VERSION "hnnbnnnynnnnnnnnnnnnnnnnnnnnnnnnnnnnnnnnnn/4/%%%/4/'%**4nnn///"

NS_ :

BS_:

BU_: BAP_Tester Fahrerdisplay_Kombi HUD ICAS1_X_Gateway ICAS3_Gateway ICC_IO_Node Kombi SmartLight_01 ZR_MIB_TOP_ab_Gen3

BO_ 2536721664 BAP_FAS_Profiles_ASG_01: 8 ICAS3_Gateway
	SG_ BAP_FAS_Profiles_ASG_01_Header : 0|8@1+ (1,0) [0|255] "None"  ICAS1_X_Gateway

BO_ 2536721680 BAP_FAS_Profiles_FSG_01: 8 ICAS1_X_Gateway
	SG_ BAP_FAS_Profiles_FSG_01_Header : 0|8@1+ (1,0) [0|255] "None"  ICAS3_Gateway

BO_ 2536707072 BAP_Homelink_ASG_01: 8 ZR_MIB_TOP_ab_Gen3
	SG_ BAP_Homelink_ASG_01_Header : 0|64@1+ (1,0) [0|18446744073709551616] ""  ICAS1_X_Gateway

BO_ 2536707088 BAP_Homelink_FSG_01: 8 ICAS1_X_Gateway
	SG_ BAP_Homelink_FSG_01_Header : 0|64@1+ (1,0) [0|18446744073709551616] ""  ZR_MIB_TOP_ab_Gen3

BO_ 2536722944 BAP_IAA_PSO_ASG_01: 8 ICAS3_Gateway
	SG_ BAP_IAA_PSO_ASG_01_Header : 0|8@1+ (1,0) [0|255] "None"  ICAS1_X_Gateway

BO_ 2536722960 BAP_IAA_PSO_FSG_01: 8 ICAS1_X_Gateway
	SG_ BAP_IAA_PSO_FSG_01_Header : 0|8@1+ (1,0) [0|255] "None"  ICAS3_Gateway,ZR_MIB_TOP_ab_Gen3

BO_ 2536722434 BAP_InfoSettings_ASG_03: 8 ICAS1_X_Gateway
	SG_ BAP_InfoSettings_ASG_03_Header : 0|64@1+ (1,0) [0|18446744073709551616] ""  ICAS3_Gateway,ZR_MIB_TOP_ab_Gen3

BO_ 2536722448 BAP_InfoSettings_FSG_01: 8 ICAS3_Gateway
	SG_ BAP_InfoSettings_FSG_01_Header : 0|8@1+ (1,0) [0|255] "None"  ICAS1_X_Gateway

BO_ 2536729088 BAP_Innenlicht2_ASG_01: 8 ICAS3_Gateway
	SG_ BAP_Innenlicht2_ASG_01_Header : 0|64@1+ (1,0) [0|18446744073709551616] ""  ICAS1_X_Gateway

BO_ 2536729104 BAP_Innenlicht2_FSG_01: 8 ICAS1_X_Gateway
	SG_ BAP_Innenlicht2_FSG_01_Header : 0|64@1+ (1,0) [0|18446744073709551616] ""  ICAS3_Gateway,ZR_MIB_TOP_ab_Gen3

BO_ 2536704000 BAP_Innenlicht_ASG_01: 8 ICAS3_Gateway
	SG_ BAP_Innenlicht_ASG_01_Header : 0|8@1+ (1,0) [0|255] ""  ICAS1_X_Gateway

BO_ 2536704016 BAP_Innenlicht_FSG_01: 8 ICAS1_X_Gateway
	SG_ BAP_Innenlicht_FSG_01_Header : 0|8@1+ (1,0) [0|255] ""  ICAS3_Gateway,ZR_MIB_TOP_ab_Gen3

BO_ 2536702208 BAP_Klima1_ASG_01: 8 ICAS3_Gateway
	SG_ BAP_Klima1_ASG_01_Header : 0|64@1+ (1,0) [0|18446744073709551616] ""  ICAS1_X_Gateway

BO_ 2536702224 BAP_Klima1_FSG_01: 8 ICAS1_X_Gateway
	SG_ BAP_Klima1_FSG_01_Header : 0|64@1+ (1,0) [0|18446744073709551616] ""  ICAS3_Gateway,ZR_MIB_TOP_ab_Gen3

BO_ 2536702464 BAP_Klima2_ASG_01: 8 ICAS3_Gateway
	SG_ BAP_Klima2_ASG_01_Header : 0|64@1+ (1,0) [0|18446744073709551616] ""  ICAS1_X_Gateway

BO_ 2536702480 BAP_Klima2_FSG_01: 8 ICAS1_X_Gateway
	SG_ BAP_Klima2_FSG_01_Header : 0|8@1+ (1,0) [0|255] ""  ICAS3_Gateway,ZR_MIB_TOP_ab_Gen3

BO_ 2536718848 BAP_KlimaMaster_ASG_01: 8 ICAS3_Gateway
	SG_ BAP_KlimaMaster_ASG_01_Header : 0|8@1+ (1,0) [0|255] "None"  ICAS1_X_Gateway

BO_ 2536718864 BAP_KlimaMaster_FSG_01: 8 ICAS1_X_Gateway
	SG_ BAP_KlimaMaster_FSG_01_Header : 0|8@1+ (1,0) [0|255] "None"  ICAS3_Gateway,ZR_MIB_TOP_ab_Gen3

BO_ 2536708352 BAP_LDW_ASG_01: 8 ICAS3_Gateway
	SG_ BAP_LDW_ASG_01_Header : 0|8@1+ (1,0) [0|255] ""  ICAS1_X_Gateway

BO_ 2536708353 BAP_LDW_ASG_02: 8 ICAS3_Gateway
	SG_ BAP_LDW_ASG_02_Header : 0|8@1+ (1,0) [0|255] ""  ICAS1_X_Gateway

BO_ 2536708368 BAP_LDW_FSG_01: 8 ICAS1_X_Gateway
	SG_ BAP_LDW_FSG_01_Header : 0|8@1+ (1,0) [0|255] ""  ICAS3_Gateway,ZR_MIB_TOP_ab_Gen3

BO_ 2536715264 BAP_MFL_ASG_01: 8 Kombi
	SG_ BAP_MFL_ASG_01_Header : 0|8@1+ (1,0) [0|255] ""  ZR_MIB_TOP_ab_Gen3

BO_ 2536715280 BAP_MFL_FSG_01: 8 ZR_MIB_TOP_ab_Gen3
	SG_ BAP_MFL_FSG_01_Header : 0|8@1+ (1,0) [0|255] ""  Kombi

BO_ 2536705536 BAP_Mirror_ASG_01: 8 ICAS3_Gateway
	SG_ BAP_Mirror_ASG_01_Header : 0|8@1+ (1,0) [0|255] ""  ICAS1_X_Gateway

BO_ 2536705552 BAP_Mirror_FSG_01: 8 ICAS1_X_Gateway
	SG_ BAP_Mirror_FSG_01_Header : 0|8@1+ (1,0) [0|255] ""  ICAS3_Gateway,ZR_MIB_TOP_ab_Gen3

BO_ 2536710656 BAP_MKE_ASG_01: 8 ICAS3_Gateway
	SG_ BAP_MKE_ASG_01_Header : 0|8@1+ (1,0) [0|255] ""  ICAS1_X_Gateway

BO_ 2536710672 BAP_MKE_FSG_01: 8 ICAS1_X_Gateway
	SG_ BAP_MKE_FSG_01_Header : 0|8@1+ (1,0) [0|255] ""  ICAS3_Gateway,ZR_MIB_TOP_ab_Gen3

BO_ 2536732416 BAP_MobDevKey_ASG_01: 8 ICAS3_Gateway
	SG_ BAP_MobDevKey_ASG_01_Header : 0|64@1+ (1,0) [0|18446744073709551616] ""  ICAS1_X_Gateway

BO_ 2536732432 BAP_MobDevKey_FSG_01: 8 ICAS1_X_Gateway
	SG_ BAP_MobDevKey_FSG_01_Header : 0|64@1+ (1,0) [0|18446744073709551616] ""  ICAS3_Gateway

BO_ 2536714752 BAP_Navigation_ASG_01: 8 Kombi
	SG_ BAP_Navigation_ASG_01_Header : 0|8@1+ (1,0) [0|255] ""  ZR_MIB_TOP_ab_Gen3

BO_ 2536714753 BAP_Navigation_ASG_02: 8 Kombi
	SG_ BAP_Navigation_ASG_02_Header : 0|8@1+ (1,0) [0|255] ""  ZR_MIB_TOP_ab_Gen3

BO_ 2536714768 BAP_Navigation_FSG_01: 8 ZR_MIB_TOP_ab_Gen3
	SG_ BAP_Navigation_FSG_01_Header : 0|8@1+ (1,0) [0|255] ""  Kombi

BO_ 2536714769 BAP_Navigation_FSG_02: 8 ZR_MIB_TOP_ab_Gen3
	SG_ BAP_Navigation_FSG_02_Header : 0|8@1+ (1,0) [0|255] ""  Kombi

BO_ 2536712704 BAP_OnlineFunctions_ASG_01: 8 Kombi
	SG_ BAP_OnlineFunction_ASG_01_Header : 0|8@1+ (1,0) [0|255] "None"  ZR_MIB_TOP_ab_Gen3

BO_ 2536712720 BAP_OnlineFunctions_FSG_01: 8 ZR_MIB_TOP_ab_Gen3
	SG_ BAP_OnlineFunction_FSG_01_Header : 0|8@1+ (1,0) [0|255] "None"  Kombi

BO_ 2536704512 BAP_OPS_ASG_01: 8 ICAS3_Gateway
	SG_ BAP_OPS_ASG_01_Header : 0|8@1+ (1,0) [0|255] ""  ICAS1_X_Gateway

BO_ 2536704528 BAP_OPS_FSG_01: 8 ICAS1_X_Gateway
	SG_ BAP_OPS_FSG_01_Header : 0|8@1+ (1,0) [0|255] ""  ICAS3_Gateway,ZR_MIB_TOP_ab_Gen3

BO_ 2536704529 BAP_OPS_FSG_02: 8 ICAS1_X_Gateway
	SG_ BAP_OPS_FSG_02_Header : 0|8@1+ (1,0) [0|255] ""  ICAS3_Gateway,ZR_MIB_TOP_ab_Gen3

BO_ 2536723712 BAP_PaCo_ASG_01: 8 ICAS3_Gateway
	SG_ BAP_PaCo_ASG_01_Header : 0|8@1+ (1,0) [0|255] "None"  ICAS1_X_Gateway

BO_ 2536723713 BAP_PaCo_ASG_02: 8 ICAS3_Gateway
	SG_ BAP_PaCo_ASG_02_Header : 0|8@1+ (1,0) [0|255] "None"  ICAS1_X_Gateway

BO_ 2536723728 BAP_PaCo_FSG_01: 8 ICAS1_X_Gateway
	SG_ BAP_PaCo_FSG_01_Header : 0|8@1+ (1,0) [0|255] "None"  ICAS3_Gateway,Kombi,ZR_MIB_TOP_ab_Gen3

BO_ 2536702720 BAP_ParkHeater_ASG_01: 8 ICAS3_Gateway
	SG_ BAP_ParkHeater_ASG_01_Header : 0|8@1+ (1,0) [0|255] ""  ICAS1_X_Gateway

BO_ 2536702736 BAP_ParkHeater_FSG_01: 8 ICAS1_X_Gateway
	SG_ BAP_ParkHeater_FSG_01_Header : 0|8@1+ (1,0) [0|255] ""  ICAS3_Gateway,ZR_MIB_TOP_ab_Gen3

BO_ 2536703744 BAP_RDK_ASG_01: 8 ICAS3_Gateway
	SG_ BAP_RDK_ASG_01_Header : 0|8@1+ (1,0) [0|255] ""  ICAS1_X_Gateway

BO_ 2536703745 BAP_RDK_ASG_02: 8 ICAS3_Gateway
	SG_ BAP_RDK_ASG_02_Header : 0|8@1+ (1,0) [0|255] ""  ICAS1_X_Gateway

BO_ 2536703747 BAP_RDK_ASG_04: 8 ICAS3_Gateway
	SG_ BAP_RDK_ASG_04_Header : 0|64@1+ (1,0) [0|18446744073709551616] ""  ICAS1_X_Gateway

BO_ 2536703760 BAP_RDK_FSG_01: 8 ICAS1_X_Gateway
	SG_ BAP_RDK_FSG_01_Header : 0|8@1+ (1,0) [0|255] ""  ICAS3_Gateway,ZR_MIB_TOP_ab_Gen3

BO_ 2536721921 BAP_RemoteServices_ASG_02: 8 ICAS3_Gateway
	SG_ BAP_RemoteServices_ASG_02_Header : 0|8@1+ (1,0) [0|255] "None"  ICAS1_X_Gateway

BO_ 2536721936 BAP_RemoteServices_FSG_01: 8 ICAS1_X_Gateway
	SG_ BAP_RemoteServices_FSG_01_Header : 0|8@1+ (1,0) [0|255] "None"  ICAS3_Gateway,ZR_MIB_TOP_ab_Gen3

BO_ 2536704768 BAP_RVC_ASG_01: 8 ICAS3_Gateway
	SG_ BAP_RVC_ASG_01_Header : 0|64@1+ (1,0) [0|18446744073709551616] ""  ICAS1_X_Gateway

BO_ 2536704784 BAP_RVC_FSG_01: 8 ICAS1_X_Gateway
	SG_ BAP_RVC_FSG_01_Header : 0|8@1+ (1,0) [0|255] ""  ICAS3_Gateway,ZR_MIB_TOP_ab_Gen3

BO_ 2536717056 BAP_SeatPneumatic_ASG_01: 8 ICAS3_Gateway
	SG_ BAP_SeatPneumatic_ASG_01_Header : 0|8@1+ (1,0) [0|255] ""  ICAS1_X_Gateway

BO_ 2536717072 BAP_SeatPneumatic_FSG_01: 8 ICAS1_X_Gateway
	SG_ BAP_SeatPneumatic_FSG_01_Header : 0|8@1+ (1,0) [0|255] ""  ICAS3_Gateway,ZR_MIB_TOP_ab_Gen3

BO_ 2536706560 BAP_SIA_ASG_01: 8 ZR_MIB_TOP_ab_Gen3
	SG_ BAP_SIA_ASG_01_Header : 0|8@1+ (1,0) [0|255] ""  Kombi

BO_ 2536706576 BAP_SIA_FSG_01: 8 Kombi
	SG_ BAP_SIA_FSG_01_Header : 0|8@1+ (1,0) [0|255] ""  ZR_MIB_TOP_ab_Gen3

BO_ 2536706048 BAP_Sitz1_ASG_01: 8 ICAS3_Gateway
	SG_ BAP_Sitz1_ASG_01_Header : 0|64@1+ (1,0) [0|18446744073709551616] ""  ICAS1_X_Gateway

BO_ 2536706064 BAP_Sitz1_FSG_01: 8 ICAS1_X_Gateway
	SG_ BAP_Sitz1_FSG_01_Header : 0|8@1+ (1,0) [0|255] ""  ICAS3_Gateway,ZR_MIB_TOP_ab_Gen3

BO_ 2536710144 BAP_Sitz2_ASG_01: 8 ZR_MIB_TOP_ab_Gen3
	SG_ BAP_Sitz2_ASG_01_Header : 0|8@1+ (1,0) [0|255] ""  ICAS1_X_Gateway

BO_ 2536710160 BAP_Sitz2_FSG_01: 8 ICAS1_X_Gateway
	SG_ BAP_Sitz2_FSG_01_Header : 0|8@1+ (1,0) [0|255] ""  ZR_MIB_TOP_ab_Gen3

BO_ 2536721152 BAP_Sunroof_ASG_01: 8 ICAS3_Gateway
	SG_ BAP_Sunroof_ASG_01_Header : 0|8@1+ (1,0) [0|255] "None"  ICAS1_X_Gateway

BO_ 2536721168 BAP_Sunroof_FSG_01: 8 ICAS1_X_Gateway
	SG_ BAP_Sunroof_FSG_01_Header : 0|8@1+ (1,0) [0|255] "None"  ICAS3_Gateway

BO_ 2536708608 BAP_SWA_ASG_01: 8 ICAS3_Gateway
	SG_ BAP_SWA_ASG_01_Header : 0|8@1+ (1,0) [0|255] ""  ICAS1_X_Gateway

BO_ 2536708624 BAP_SWA_FSG_01: 8 ICAS1_X_Gateway
	SG_ BAP_SWA_FSG_01_Header : 0|8@1+ (1,0) [0|255] ""  ICAS3_Gateway,ZR_MIB_TOP_ab_Gen3

BO_ 2536712448 BAP_Telefon2_ASG_01: 8 Kombi
	SG_ BAP_Telefon2_ASG_01_Header : 0|8@1+ (1,0) [0|255] ""  ZR_MIB_TOP_ab_Gen3

BO_ 2536712464 BAP_Telefon2_FSG_01: 8 ZR_MIB_TOP_ab_Gen3
	SG_ BAP_Telefon2_FSG_01_Header : 0|8@1+ (1,0) [0|255] ""  Kombi

BO_ 2536712465 BAP_Telefon2_FSG_02: 8 ZR_MIB_TOP_ab_Gen3
	SG_ BAP_Telefon2_FSG_02_Header : 0|8@1+ (1,0) [0|255] "None"  Kombi

BO_ 2536712192 BAP_Telefon_ASG_01: 8 Kombi
	SG_ BAP_Telefon_ASG_01_Header : 0|8@1+ (1,0) [0|255] ""  ZR_MIB_TOP_ab_Gen3

BO_ 2536712193 BAP_Telefon_ASG_02: 8 Kombi
	SG_ BAP_Telefon_ASG_02_Header : 0|8@1+ (1,0) [0|255] ""  ZR_MIB_TOP_ab_Gen3

BO_ 2536712208 BAP_Telefon_FSG_01: 8 ZR_MIB_TOP_ab_Gen3
	SG_ BAP_Telefon_FSG_01_Header : 0|8@1+ (1,0) [0|255] ""  Kombi

BO_ 2536712209 BAP_Telefon_FSG_02: 8 ZR_MIB_TOP_ab_Gen3
	SG_ BAP_Telefon_FSG_02_Header : 0|8@1+ (1,0) [0|255] ""  Kombi

BO_ 2536728576 BAP_THA_ASG_01: 8 ICAS3_Gateway
	SG_ BAP_THA_ASG_01_Header : 0|64@1+ (1,0) [0|18446744073709551616] ""  ICAS1_X_Gateway

BO_ 2536728592 BAP_THA_FSG_01: 8 ICAS1_X_Gateway
	SG_ BAP_THA_FSG_01_Header : 0|64@1+ (1,0) [0|18446744073709551616] ""  ICAS3_Gateway

BO_ 2536726273 BAP_TPA_ASG_02: 8 ICAS3_Gateway
	SG_ BAP_TPA_ASG_02_Header : 0|64@1+ (1,0) [0|18446744073709551616] ""  ICAS1_X_Gateway

BO_ 2536726288 BAP_TPA_FSG_01: 8 ICAS1_X_Gateway
	SG_ BAP_TPA_FSG_01_Header : 0|64@1+ (1,0) [0|18446744073709551616] ""  ICAS3_Gateway

BO_ 2536715776 BAP_TrailerAssist_ASG_01: 8 ICAS3_Gateway
	SG_ BAP_TrailerAssist_ASG_01_Header : 0|8@1+ (1,0) [0|255] ""  ICAS1_X_Gateway

BO_ 2536715792 BAP_TrailerAssist_FSG_01: 8 ICAS1_X_Gateway
	SG_ BAP_TrailerAssist_FSG_01_Header : 0|8@1+ (1,0) [0|255] ""  ICAS3_Gateway,ZR_MIB_TOP_ab_Gen3

BO_ 2536710400 BAP_VZA_ASG_01: 8 ICAS3_Gateway
	SG_ BAP_VZA_ASG_01_Header : 0|8@1+ (1,0) [0|255] ""  ICAS1_X_Gateway

BO_ 2536710401 BAP_VZA_ASG_02: 8 ICAS3_Gateway
	SG_ BAP_VZA_ASG_02_Header : 0|8@1+ (1,0) [0|255] ""  ICAS1_X_Gateway

BO_ 2536710402 BAP_VZA_ASG_03: 8 ICAS3_Gateway
	SG_ BAP_VZA_ASG_03_Header : 0|8@1+ (1,0) [0|255] "None"  ICAS1_X_Gateway

BO_ 2536710416 BAP_VZA_FSG_01: 8 ICAS1_X_Gateway
	SG_ BAP_VZA_FSG_01_Header : 0|8@1+ (1,0) [0|255] ""  ICAS3_Gateway,Kombi,ZR_MIB_TOP_ab_Gen3

BO_ 2536705024 BAP_Wiper_ASG_01: 8 ICAS3_Gateway
	SG_ BAP_Wiper_ASG_01_Header : 0|8@1+ (1,0) [0|255] ""  ICAS1_X_Gateway

BO_ 2536705040 BAP_Wiper_FSG_01: 8 ICAS1_X_Gateway
	SG_ BAP_Wiper_FSG_01_Header : 0|8@1+ (1,0) [0|255] ""  ICAS3_Gateway,ZR_MIB_TOP_ab_Gen3

BO_ 1626 BCM_01: 8 ICAS1_X_Gateway
	SG_ APS_Tongeber_defekt : 44|1@1+ (1,0) [0|1] ""  Vector__XXX
	SG_ BCM1_AFS_Lampe : 35|1@1+ (1,0) [0|1] ""  Vector__XXX
	SG_ BCM1_EasyEntry_Status : 45|1@1+ (1,0) [0|1] ""  Vector__XXX
	SG_ BCM1_Kl_15_HW_erkannt : 17|1@1+ (1,0) [0|1] ""  Vector__XXX
	SG_ BCM1_Kl_15_Sig_HW_erkannt : 18|1@1+ (1,0) [0|1] ""  Vector__XXX
	SG_ BCM1_Lenksaeule_aktiv : 46|1@1+ (1,0) [0|1] ""  Vector__XXX
	SG_ BCM1_MH_Schalter : 31|1@1+ (1,0) [0|1] ""  ICAS3_Gateway,Kombi,ZR_MIB_TOP_ab_Gen3
	SG_ BCM1_MH_WIV_Schalter : 32|1@1+ (1,0) [0|1] ""  Vector__XXX
	SG_ BCM1_NV_Taster : 34|1@1+ (1,0) [0|1] ""  Vector__XXX
	SG_ BCM1_Reisemodus_Texte : 36|2@1+ (1,0) [0|3] ""  Vector__XXX
	SG_ BCM1_Rueckfahrlicht_Schalter : 30|1@1+ (1,0) [0|1] ""  Vector__XXX
	SG_ BCM1_Spannungs_Anf : 47|2@1+ (1,0) [0|3] ""  Vector__XXX
	SG_ BCM1_Valet_Parking_Taster : 26|1@1+ (1,0) [0|1] ""  Vector__XXX
	SG_ BCM1_Warnblink_Taster : 25|1@1+ (1,0) [0|1] ""  Vector__XXX
	SG_ BCM_Anf_AAW_MoLaWa : 58|2@1+ (1,0) [0|3] ""  Vector__XXX
	SG_ BCM_Bremsbelag_Sensor : 12|1@1+ (1,0) [0|1] ""  Kombi
	SG_ BCM_Bremsfluessigkeit_Sensor : 13|1@1+ (1,0) [0|1] ""  Fahrerdisplay_Kombi,Kombi
	SG_ BCM_Charisma_Taste2 : 22|1@1+ (1,0) [0|1] ""  Vector__XXX
	SG_ BCM_Eco_Charisma_Taste : 33|1@1+ (1,0) [0|1] ""  Vector__XXX
	SG_ BCM_Handbremse_Hinweis : 60|1@1+ (1,0) [0|1] ""  Vector__XXX
	SG_ BCM_HDF_betaetigt : 63|1@1+ (1,0) [0|1] ""  Vector__XXX
	SG_ BCM_Hybrid_StartStopp_Taste : 24|1@1+ (1,0) [0|1] ""  Vector__XXX
	SG_ BCM_Hybrid_StSt_Taste_Fehler : 23|1@1+ (1,0) [0|1] ""  Vector__XXX
	SG_ BCM_Kuehlmittel_Sensor : 16|1@1+ (1,0) [0|1] ""  Kombi
	SG_ BCM_Kuehlmittel_Sensor_02 : 19|1@1+ (1,0) [0|1] ""  Vector__XXX
	SG_ BCM_Offroad_Taste : 21|1@1+ (1,0) [0|1] ""  Vector__XXX
	SG_ BCM_ValetTaster_Fkts_LED : 42|1@1+ (1,0) [0|1] ""  Vector__XXX
	SG_ BCM_Waschwasser_Sensor : 15|1@1+ (1,0) [0|1] ""  Kombi
	SG_ Gong_TFL_Umschaltung : 40|1@1+ (1,0) [0|1] ""  Vector__XXX
	SG_ LRH_Taster : 43|1@1+ (1,0) [0|1] ""  Vector__XXX

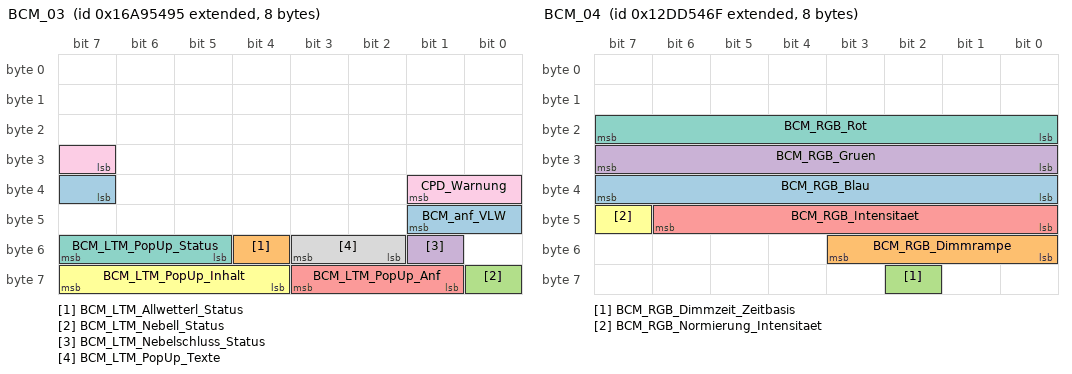
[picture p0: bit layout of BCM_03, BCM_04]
BO_ 2527679637 BCM_03: 8 ICAS1_X_Gateway
	SG_ BCM_anf_VLW : 39|3@1+ (1,0) [0|7] ""  Vector__XXX
	SG_ BCM_LTM_Allwetterl_Status : 52|1@1+ (1,0) [0|1] ""  ICAS3_Gateway,Kombi
	SG_ BCM_LTM_Nebell_Status : 56|1@1+ (1,0) [0|1] ""  Kombi
	SG_ BCM_LTM_Nebelschluss_Status : 49|1@1+ (1,0) [0|1] ""  Kombi
	SG_ BCM_LTM_PopUp_Anf : 57|3@1+ (1,0) [0|7] ""  Kombi
	SG_ BCM_LTM_PopUp_Inhalt : 60|4@1+ (1,0) [0|15] ""  Kombi
	SG_ BCM_LTM_PopUp_Status : 53|3@1+ (1,0) [0|7] ""  Kombi
	SG_ BCM_LTM_PopUp_Texte : 50|2@1+ (1,0) [0|3] ""  Vector__XXX
	SG_ CPD_Warnung : 31|3@1+ (1,0) [0|7] ""  Kombi

BO_ 2463978607 BCM_04: 8 ICAS1_X_Gateway
	SG_ BCM_RGB_Blau : 32|8@1+ (1,0) [0|255] ""  ICAS3_Gateway,ZR_MIB_TOP_ab_Gen3
	SG_ BCM_RGB_Dimmrampe : 48|4@1+ (0.25,0) [0|3.75] "Secon"  Vector__XXX
	SG_ BCM_RGB_Dimmzeit_Zeitbasis : 58|1@1+ (1,0) [0|1] ""  Vector__XXX
	SG_ BCM_RGB_Gruen : 24|8@1+ (1,0) [0|255] ""  ICAS3_Gateway,ZR_MIB_TOP_ab_Gen3
	SG_ BCM_RGB_Intensitaet : 40|7@1+ (1,0) [0|100] "PerCent"  Vector__XXX
	SG_ BCM_RGB_Normierung_Intensitaet : 47|1@1+ (1,0) [0|1] ""  Vector__XXX
	SG_ BCM_RGB_Rot : 16|8@1+ (1,0) [0|255] ""  ICAS3_Gateway,ZR_MIB_TOP_ab_Gen3

BO_ 1432 BCM_Taster_02: 8 ICAS1_X_Gateway
	SG_ BCM_BFS_Massage_Taster : 42|1@1+ (1,0) [0|1] ""  Vector__XXX
	SG_ BCM_BFS_Multif_Taster : 40|1@1+ (1,0) [0|1] ""  Vector__XXX
	SG_ BCM_BFS_Pneumatik_Verstellung : 44|1@1+ (1,0) [0|1] ""  Vector__XXX
	SG_ BCM_BFS_Programmwippe : 38|1@1+ (1,0) [0|1] ""  Vector__XXX
	SG_ BCM_FS_Massage_Taster : 41|1@1+ (1,0) [0|1] ""  Vector__XXX
	SG_ BCM_FS_Multif_Taster : 39|1@1+ (1,0) [0|1] ""  Vector__XXX
	SG_ BCM_FS_Pneumatik_Verstellung : 43|1@1+ (1,0) [0|1] ""  Vector__XXX
	SG_ BCM_FS_Programmwippe : 37|1@1+ (1,0) [0|1] ""  Vector__XXX
	SG_ FAS_Profile_Taster : 20|2@1+ (1,0) [0|3] ""  ZR_MIB_TOP_ab_Gen3
	SG_ LIM_bCall_Taster : 12|1@1+ (1,0) [0|1] ""  Vector__XXX
	SG_ LIM_iCall_Taster : 13|1@1+ (1,0) [0|1] ""  Vector__XXX
	SG_ LIM_S_Rollo_hi : 53|3@1+ (1,0) [0|7] ""  Vector__XXX
	SG_ LIM_S_Rollo_vo : 50|3@1+ (1,0) [0|7] ""  Vector__XXX
	SG_ LIM_S_SAD_hi : 60|4@1+ (1,0) [0|15] ""  Vector__XXX
	SG_ LIM_S_SAD_Vo : 56|4@1+ (1,0) [0|15] ""  Vector__XXX
	SG_ LINDa_Touch_Event : 16|4@1+ (1,0) [0|15] ""  ICAS3_Gateway,ICC_IO_Node,ZR_MIB_TOP_ab_Gen3
	SG_ Tuerkontakt_Innenlicht_Taste : 14|1@1+ (1,0) [0|1] ""  Vector__XXX

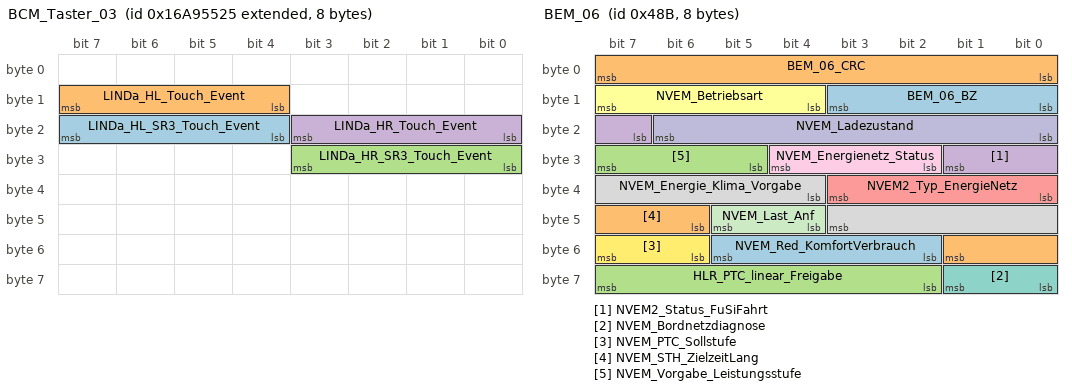
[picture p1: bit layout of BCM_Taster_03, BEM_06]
BO_ 2527679781 BCM_Taster_03: 8 ICAS1_X_Gateway
	SG_ LINDa_HL_SR3_Touch_Event : 20|4@1+ (1,0) [0|15] ""  ICAS3_Gateway,ICC_IO_Node,ZR_MIB_TOP_ab_Gen3
	SG_ LINDa_HL_Touch_Event : 12|4@1+ (1,0) [0|15] ""  ICAS3_Gateway,ICC_IO_Node,ZR_MIB_TOP_ab_Gen3
	SG_ LINDa_HR_SR3_Touch_Event : 24|4@1+ (1,0) [0|15] ""  ICAS3_Gateway,ICC_IO_Node,ZR_MIB_TOP_ab_Gen3
	SG_ LINDa_HR_Touch_Event : 16|4@1+ (1,0) [0|15] ""  ICAS3_Gateway,ICC_IO_Node,ZR_MIB_TOP_ab_Gen3

BO_ 1635 BEM_02: 8 ICAS1_X_Gateway
	SG_ BEM_Anf_KL15_schalten : 54|2@1+ (1,0) [0|3] ""  ICAS3_Gateway,ICC_IO_Node,ZR_MIB_TOP_ab_Gen3
	SG_ BEM_Batt_Ab : 39|1@1+ (1,0) [0|1] ""  ICAS3_Gateway,ICC_IO_Node,ZR_MIB_TOP_ab_Gen3
	SG_ BEM_Batteriediagnose : 28|3@1+ (1,0) [0|7] ""  ICAS3_Gateway,ICC_IO_Node,Kombi,ZR_MIB_TOP_ab_Gen3
	SG_ BEM_DFM : 32|5@1+ (3.225,0.025) [0.025|100] ""  ICAS3_Gateway,ICC_IO_Node,ZR_MIB_TOP_ab_Gen3
	SG_ BEM_EMLIN_ungueltig : 38|1@1+ (1,0) [0|1] ""  ICAS3_Gateway,ICC_IO_Node,ZR_MIB_TOP_ab_Gen3
	SG_ BEM_Generatordiagnose : 16|2@1+ (1,0) [0|3] ""  ICAS3_Gateway,ICC_IO_Node,Kombi,ZR_MIB_TOP_ab_Gen3
	SG_ BEM_HL_Kontingentierung : 8|6@1+ (50,-1000) [-1000|1000] "Watt"  ICAS3_Gateway,ICC_IO_Node,ZR_MIB_TOP_ab_Gen3
	SG_ BEM_HL_Regelung_Status : 21|3@1+ (1,0) [0|7] ""  ICAS3_Gateway,ICC_IO_Node,ZR_MIB_TOP_ab_Gen3
	SG_ BEM_Ladezustand : 24|4@1+ (10,0) [0|100] "PerCent"  ICAS3_Gateway,ICC_IO_Node,Kombi,ZR_MIB_TOP_ab_Gen3
	SG_ BEM_MMI_Vorwarnung : 7|1@1+ (1,0) [0|1] ""  ICAS3_Gateway,ICC_IO_Node,ZR_MIB_TOP_ab_Gen3
	SG_ BEM_Red_Innengeblaese : 18|2@1+ (1,0) [0|3] ""  ICAS3_Gateway,ICC_IO_Node,ZR_MIB_TOP_ab_Gen3
	SG_ BEM_REK_aktiv : 37|1@1+ (1,0) [0|1] ""  ICAS3_Gateway,ICC_IO_Node,ZR_MIB_TOP_ab_Gen3
	SG_ BEM_STH_Einschaltverbot : 20|1@1+ (1,0) [0|1] ""  ICAS3_Gateway,ICC_IO_Node,ZR_MIB_TOP_ab_Gen3
	SG_ BEM_STH_Zielzeit : 3|4@1+ (5,0) [0|60] "Minut"  ICAS3_Gateway,ICC_IO_Node,ZR_MIB_TOP_ab_Gen3
	SG_ BEM_UBDM : 40|8@1+ (0.05,5) [5.05|17.7] "Volt"  ICAS3_Gateway,ICC_IO_Node,ZR_MIB_TOP_ab_Gen3
	SG_ BEM_UGenSoll : 48|6@1+ (0.1,10.6) [10.6|16] "Volt"  ICAS3_Gateway,ICC_IO_Node,ZR_MIB_TOP_ab_Gen3
	SG_ MIB_Stromsparmodus : 31|1@1+ (1,0) [0|1] ""  ICAS3_Gateway,ICC_IO_Node,ZR_MIB_TOP_ab_Gen3
	SG_ NVEM_Abschaltstufe : 0|2@1+ (1,0) [0|3] ""  HUD,ICAS3_Gateway,ICC_IO_Node,Kombi,SmartLight_01,ZR_MIB_TOP_ab_Gen3
	SG_ NVEM_Anf_SD_schalten : 15|1@1+ (1,0) [0|1] ""  ICAS3_Gateway,ICC_IO_Node,ZR_MIB_TOP_ab_Gen3
	SG_ NVEM_Batterie_Service : 56|2@1+ (1,0) [0|3] ""  ICAS3_Gateway,ICC_IO_Node,Kombi,ZR_MIB_TOP_ab_Gen3
	SG_ NVEM_Freigabe_OnlineUpdate : 58|1@1+ (1,0) [0|1] ""  ICAS3_Gateway,ICC_IO_Node,ZR_MIB_TOP_ab_Gen3
	SG_ NVEM_Freigabe_ORU4 : 59|2@1+ (1,0) [0|3] ""  ICAS3_Gateway,ICC_IO_Node,ZR_MIB_TOP_ab_Gen3
	SG_ NVEM_Freigabe_ZusBatt_Laden : 14|1@1+ (1,0) [0|1] ""  ICAS3_Gateway,ICC_IO_Node,ZR_MIB_TOP_ab_Gen3
	SG_ NVEM_Verbraucherabsch_Anz : 61|1@1+ (1,0) [0|1] ""  ICAS3_Gateway,ICC_IO_Node,Kombi,ZR_MIB_TOP_ab_Gen3

BO_ 1163 BEM_06: 8 ICAS1_X_Gateway
	SG_ BEM_06_BZ : 8|4@1+ (1,0) [0|15] ""  Fahrerdisplay_Kombi,Kombi
	SG_ BEM_06_CRC : 0|8@1+ (1,0) [0|255] ""  Fahrerdisplay_Kombi,Kombi
	SG_ HLR_PTC_linear_Freigabe : 58|6@1+ (50,0) [0|3100] "Watt"  Vector__XXX
	SG_ NVEM2_Status_FuSiFahrt : 23|3@1+ (1,0) [0|7] ""  Vector__XXX
	SG_ NVEM2_Typ_EnergieNetz : 32|4@1+ (1,0) [0|15] ""  Vector__XXX
	SG_ NVEM_Betriebsart : 12|4@1+ (1,0) [0|15] ""  Vector__XXX
	SG_ NVEM_Bordnetzdiagnose : 56|2@1+ (1,0) [0|3] ""  Fahrerdisplay_Kombi,Kombi
	SG_ NVEM_Energie_Klima_Vorgabe : 36|8@1+ (10,0) [0|2530] "WattHour"  Vector__XXX
	SG_ NVEM_Energienetz_Status : 26|3@1+ (1,0) [0|7] ""  Vector__XXX
	SG_ NVEM_Ladezustand : 16|7@1+ (1,0) [0|100] "PerCent"  Vector__XXX
	SG_ NVEM_Last_Anf : 44|2@1+ (1,0) [0|3] ""  Vector__XXX
	SG_ NVEM_PTC_Sollstufe : 54|2@1+ (1,0) [0|3] ""  Vector__XXX
	SG_ NVEM_Red_KomfortVerbrauch : 50|4@1+ (1,0) [0|15] ""  Vector__XXX
	SG_ NVEM_STH_ZielzeitLang : 46|4@1+ (10,0) [0|120] "Minut"  Vector__XXX
	SG_ NVEM_Vorgabe_Leistungsstufe : 29|3@1+ (1,0) [0|7] ""  Vector__XXX

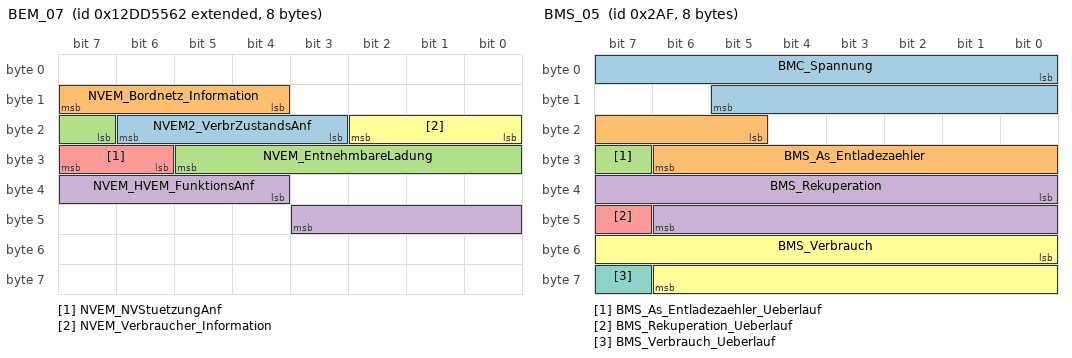
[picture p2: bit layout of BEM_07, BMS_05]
BO_ 2463978850 BEM_07: 8 ICAS1_X_Gateway
	SG_ NVEM2_VerbrZustandsAnf : 19|4@1+ (1,0) [0|15] ""  Vector__XXX
	SG_ NVEM_Bordnetz_Information : 12|4@1+ (1,0) [0|15] ""  Vector__XXX
	SG_ NVEM_EntnehmbareLadung : 23|7@1+ (1,0) [0|127] "AmperHour"  Vector__XXX
	SG_ NVEM_HVEM_FunktionsAnf : 36|8@1+ (1,0) [0|255] ""  ICAS3_Gateway
	SG_ NVEM_NVStuetzungAnf : 30|2@1+ (1,0) [0|3] ""  Vector__XXX
	SG_ NVEM_Verbraucher_Information : 16|3@1+ (1,0) [0|7] ""  Vector__XXX

BO_ 870 Blinkmodi_02: 8 ICAS1_X_Gateway
	SG_ Blinken_li_Fzg_Takt : 25|1@1+ (1,0) [0|1] ""  Vector__XXX
	SG_ Blinken_li_Kombi_Takt : 27|1@1+ (1,0) [0|1] ""  Fahrerdisplay_Kombi,ICAS3_Gateway,Kombi,ZR_MIB_TOP_ab_Gen3
	SG_ Blinken_re_Fzg_Takt : 26|1@1+ (1,0) [0|1] ""  Vector__XXX
	SG_ Blinken_re_Kombi_Takt : 28|1@1+ (1,0) [0|1] ""  Fahrerdisplay_Kombi,ICAS3_Gateway,Kombi,ZR_MIB_TOP_ab_Gen3
	SG_ Blinkmodi_02_BZ : 8|4@1+ (1,0) [0|15] ""  Vector__XXX
	SG_ Blinkmodi_02_CRC : 0|8@1+ (1,0) [0|255] ""  Vector__XXX
	SG_ BM_Autobahn : 34|1@1+ (1,0) [0|1] ""  ZR_MIB_TOP_ab_Gen3
	SG_ BM_Crash : 16|1@1+ (1,0) [0|1] ""  Vector__XXX
	SG_ BM_DWA_Alarm : 15|1@1+ (1,0) [0|1] ""  Vector__XXX
	SG_ BM_DWA_ein : 14|1@1+ (1,0) [0|1] ""  Vector__XXX
	SG_ BM_GDO : 19|1@1+ (1,0) [0|1] ""  Vector__XXX
	SG_ BM_HD_Oeffnung_angelernt : 33|1@1+ (1,0) [0|1] ""  Vector__XXX
	SG_ BM_links : 23|1@1+ (1,0) [0|1] ""  Vector__XXX
	SG_ BM_NBA_n_codiert_n_aktiv : 29|1@1+ (1,0) [0|1] ""  Vector__XXX
	SG_ BM_NBA_Status : 30|2@1+ (1,0) [0|3] ""  Vector__XXX
	SG_ BM_Not_Bremsung : 18|1@1+ (1,0) [0|1] ""  Vector__XXX
	SG_ BM_Panik : 17|1@1+ (1,0) [0|1] ""  Vector__XXX
	SG_ BM_PiloPa : 44|1@1+ (1,0) [0|1] ""  Vector__XXX
	SG_ BM_Recas : 36|1@1+ (1,0) [0|1] ""  Vector__XXX
	SG_ BM_rechts : 24|1@1+ (1,0) [0|1] ""  Vector__XXX
	SG_ BM_Rollenmodus_Blinken : 35|1@1+ (1,0) [0|1] ""  Vector__XXX
	SG_ BM_Taxi_Notalarm : 21|1@1+ (1,0) [0|1] ""  Vector__XXX
	SG_ BM_Telematik : 22|1@1+ (1,0) [0|1] ""  Vector__XXX
	SG_ BM_Telematik_Abbruchgrund : 38|6@1+ (1,0) [0|63] ""  Vector__XXX
	SG_ BM_Warnblinken : 20|1@1+ (1,0) [0|1] ""  Kombi
	SG_ BM_WBT_Beleuchtung : 32|1@1+ (1,0) [0|1] ""  Vector__XXX
	SG_ BM_Wischblinken : 37|1@1+ (1,0) [0|1] ""  Vector__XXX
	SG_ BM_ZV_auf : 12|1@1+ (1,0) [0|1] ""  Vector__XXX
	SG_ BM_ZV_zu : 13|1@1+ (1,0) [0|1] ""  Vector__XXX
	SG_ DWA_Alarmquelle : 59|5@1+ (1,0) [0|31] ""  Vector__XXX
	SG_ SAL_TA_Blinken_Status : 45|3@1+ (1,0) [0|7] ""  Vector__XXX

BO_ 687 BMS_05: 8 ICAS1_X_Gateway
	SG_ BMC_Spannung : 0|14@1+ (0.0625,0) [0|1023.75] "Volt"  Vector__XXX
	SG_ BMS_As_Entladezaehler : 21|10@1+ (1,0) [0|1023] "AmperSecon"  Vector__XXX
	SG_ BMS_As_Entladezaehler_Ueberlauf : 31|1@1+ (1,0) [0|1] ""  Vector__XXX
	SG_ BMS_Rekuperation : 32|15@1+ (10,0) [0|327670] "WattSecond"  Kombi
	SG_ BMS_Rekuperation_Ueberlauf : 47|1@1+ (1,0) [0|1] ""  Kombi
	SG_ BMS_Verbrauch : 48|15@1+ (10,0) [0|327670] "WattSecond"  Kombi
	SG_ BMS_Verbrauch_Ueberlauf : 63|1@1+ (1,0) [0|1] ""  Kombi

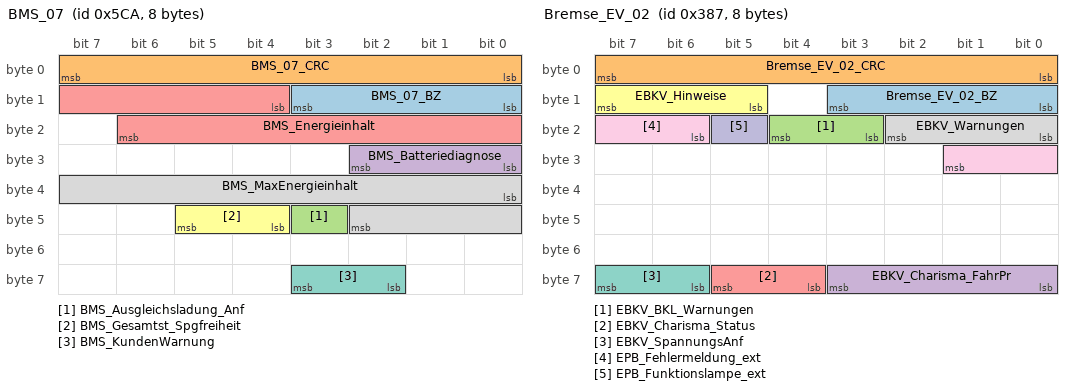
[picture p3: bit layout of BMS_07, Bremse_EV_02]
BO_ 1482 BMS_07: 8 ICAS1_X_Gateway
	SG_ BMS_07_BZ : 8|4@1+ (1,0) [0|15] ""  Vector__XXX
	SG_ BMS_07_CRC : 0|8@1+ (1,0) [0|255] ""  Vector__XXX
	SG_ BMS_Ausgleichsladung_Anf : 43|1@1+ (1,0) [0|1] ""  Vector__XXX
	SG_ BMS_Batteriediagnose : 24|3@1+ (1,0) [0|7] ""  Vector__XXX
	SG_ BMS_Energieinhalt : 12|11@1+ (50,0) [0|102250] "WattHour"  Vector__XXX
	SG_ BMS_Gesamtst_Spgfreiheit : 44|2@1+ (1,0) [0|3] ""  Vector__XXX
	SG_ BMS_KundenWarnung : 58|2@1+ (1,0) [0|3] ""  Fahrerdisplay_Kombi,Kombi
	SG_ BMS_MaxEnergieinhalt : 32|11@1+ (50,0) [0|102250] "WattHour"  Vector__XXX

BO_ 903 Bremse_EV_02: 8 ICAS1_X_Gateway
	SG_ Bremse_EV_02_BZ : 8|4@1+ (1,0) [0|15] ""  Fahrerdisplay_Kombi,Kombi
	SG_ Bremse_EV_02_CRC : 0|8@1+ (1,0) [0|255] ""  Fahrerdisplay_Kombi,Kombi
	SG_ EBKV_BKL_Warnungen : 19|2@1+ (1,0) [0|3] ""  Vector__XXX
	SG_ EBKV_Charisma_FahrPr : 56|4@1+ (1,0) [0|15] ""  Vector__XXX
	SG_ EBKV_Charisma_Status : 60|2@1+ (1,0) [0|3] ""  Vector__XXX
	SG_ EBKV_Hinweise : 13|3@1+ (1,0) [0|7] ""  Kombi
	SG_ EBKV_SpannungsAnf : 62|2@1+ (1,0) [0|3] ""  Vector__XXX
	SG_ EBKV_Warnungen : 16|3@1+ (1,0) [0|7] ""  Kombi
	SG_ EPB_Fehlermeldung_ext : 22|4@1+ (1,0) [0|15] ""  Fahrerdisplay_Kombi,Kombi
	SG_ EPB_Funktionslampe_ext : 21|1@1+ (1,0) [0|1] ""  Fahrerdisplay_Kombi,Kombi

BO_ 902 Charisma_03: 8 ICAS1_X_Gateway
	SG_ CHA_Charge_LED : 57|1@1+ (1,0) [0|1] ""  Vector__XXX
	SG_ CHA_Charisma_Taste2_LED : 0|2@1+ (1,0) [0|3] ""  Vector__XXX
	SG_ CHA_Current_Mode : 52|4@1+ (1,0) [0|15] ""  Vector__XXX
	SG_ CHA_Current_Mode_FPA : 6|6@1+ (1,0) [0|63] ""  Kombi
	SG_ CHA_Eco_Charisma_LED : 12|2@1+ (1,0) [0|3] ""  Vector__XXX
	SG_ CHA_EV_LED : 15|1@1+ (1,0) [0|1] ""  Vector__XXX
	SG_ CHA_Fahrer_Umschaltung : 14|1@1+ (1,0) [0|1] ""  Vector__XXX
	SG_ CHA_Kombi_Texte : 24|4@1+ (1,0) [0|15] ""  Kombi
	SG_ CHA_Kombi_Texte_02 : 60|4@1+ (1,0) [0|15] ""  Kombi
	SG_ CHA_Offroad_LED : 58|2@1+ (1,0) [0|3] ""  Vector__XXX
	SG_ CHA_ReqPrgDispSetup : 2|4@1+ (1,0) [0|15] ""  Kombi
	SG_ CHA_StCurProfDft : 36|2@1+ (1,0) [0|3] ""  Kombi
	SG_ CHA_Ziel_FahrPr_03_01 : 44|4@1+ (1,0) [0|15] ""  Vector__XXX
	SG_ CHA_Ziel_FahrPr_03_02 : 48|4@1+ (1,0) [0|15] ""  Vector__XXX
	SG_ CHA_Ziel_FahrPr_AMB : 16|4@1+ (1,0) [0|15] ""  Vector__XXX
	SG_ CHA_Ziel_FahrPr_HSP : 32|4@1+ (1,0) [0|15] ""  Vector__XXX
	SG_ CHA_Ziel_FahrPr_IVB : 20|4@1+ (1,0) [0|15] ""  Vector__XXX
	SG_ CHA_Ziel_FahrPr_KL : 28|4@1+ (1,0) [0|15] ""  Vector__XXX
	SG_ CHA_Ziel_FahrPr_RWB : 40|4@1+ (1,0) [0|15] ""  Vector__XXX

BO_ 918 Daempfer_01: 8 ICAS1_X_Gateway
	SG_ DR_Gelbe_Warnlampe : 18|2@1+ (1,0) [0|3] ""  Kombi

BO_ 2463978758 Daempfer_05: 16 ICAS1_X_Gateway
	SG_ DR_DCCMonitor_I_Add : 48|8@1+ (0.5,0) [0|100] "PerCent"  ICAS3_Gateway
	SG_ DR_DCCMonitor_I_HL : 64|8@1+ (0.5,0) [0|100] "PerCent"  ICAS3_Gateway
	SG_ DR_DCCMonitor_I_HR : 80|8@1+ (0.5,0) [0|100] "PerCent"  ICAS3_Gateway
	SG_ DR_DCCMonitor_I_SZ_Add : 56|8@1+ (0.5,0) [0|100] "PerCent"  ICAS3_Gateway
	SG_ DR_DCCMonitor_I_SZ_HL : 72|8@1+ (0.5,0) [0|100] "PerCent"  ICAS3_Gateway
	SG_ DR_DCCMonitor_I_SZ_HR : 88|8@1+ (0.5,0) [0|100] "PerCent"  ICAS3_Gateway
	SG_ DR_DCCMonitor_I_SZ_VL : 104|8@1+ (0.5,0) [0|100] "PerCent"  ICAS3_Gateway
	SG_ DR_DCCMonitor_I_SZ_VR : 120|8@1+ (0.5,0) [0|100] "PerCent"  ICAS3_Gateway
	SG_ DR_DCCMonitor_I_VL : 96|8@1+ (0.5,0) [0|100] "PerCent"  ICAS3_Gateway
	SG_ DR_DCCMonitor_I_VR : 112|8@1+ (0.5,0) [0|100] "PerCent"  ICAS3_Gateway

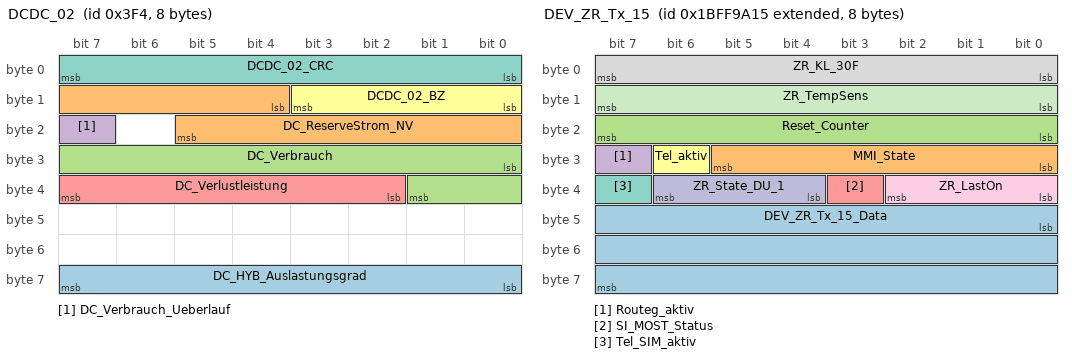
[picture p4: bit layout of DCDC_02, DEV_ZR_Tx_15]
BO_ 1012 DCDC_02: 8 ICAS1_X_Gateway
	SG_ DC_HYB_Auslastungsgrad : 56|8@1+ (0.4,0) [0|100] "PerCent"  Vector__XXX
	SG_ DC_ReserveStrom_NV : 12|10@1+ (1,-511) [-511|510] "Amper"  Vector__XXX
	SG_ DC_Verbrauch : 24|10@1+ (1,0) [0|1023] "WattSecond"  Kombi
	SG_ DC_Verbrauch_Ueberlauf : 23|1@1+ (1,0) [0|1] ""  Kombi
	SG_ DC_Verlustleistung : 34|6@1+ (5,0) [0|305] "Watt"  Vector__XXX
	SG_ DCDC_02_BZ : 8|4@1+ (1,0) [0|15] ""  Vector__XXX
	SG_ DCDC_02_CRC : 0|8@1+ (1,0) [0|255] ""  Vector__XXX

BO_ 2617039369 DEV_HUD_Rx_09: 8 Vector__XXX
	SG_ DEV_HUD_Rx_09_Data : 0|64@1+ (1,0) [0|18446744073709551616] ""  HUD

BO_ 2617039370 DEV_HUD_Rx_10: 8 Vector__XXX
	SG_ DEV_HUD_Rx_10_Data : 0|64@1+ (1,0) [0|18446744073709551616] ""  HUD

BO_ 2617039361 DEV_HUD_Tx_01: 8 HUD
	SG_ DEV_HUD_Tx_01_Data : 0|64@1+ (1,0) [0|18446744073709551616] ""  Vector__XXX

BO_ 2617039362 DEV_HUD_Tx_02: 8 HUD
	SG_ DEV_HUD_Tx_02_Data : 0|64@1+ (1,0) [0|18446744073709551616] ""  Vector__XXX

BO_ 2591834880 DEV_SmaLi_Tx_01: 64 SmartLight_01
	SG_ DEV_SmaLi_Tx_01_Data : 0|512@1+ (1,0) [0|13407807929942597099574024998205846127479365820592393377723561443721764030073546976801874298166903427690031858186486050853753882811946569946433649006084096] ""  Vector__XXX

BO_ 2617219613 DEV_ZR_Produktion_1_Rx_1D: 8 Vector__XXX
	SG_ DEV_ZR_Produktion_1_Rx_1D_Data : 0|64@1+ (1,0) [0|1] ""  ZR_MIB_TOP_ab_Gen3

BO_ 2617219612 DEV_ZR_Produktion_1_Tx_1C: 8 ZR_MIB_TOP_ab_Gen3
	SG_ DEV_ZR_Produktion_1_Tx_1C_Data : 0|64@1+ (1,0) [0|1] ""  Vector__XXX

BO_ 2617219597 DEV_ZR_Req_0D: 8 Vector__XXX
	SG_ DEV_ZR_Req_0D_Data : 0|64@1+ (1,0) [0|1] ""  ZR_MIB_TOP_ab_Gen3

BO_ 2617219584 DEV_ZR_Resp_00: 8 ZR_MIB_TOP_ab_Gen3
	SG_ DEV_ZR_Resp_00_Data : 0|64@1+ (1,0) [0|1] ""  Vector__XXX

BO_ 2617219621 DEV_ZR_SmaLi_01_Tx: 64 ICAS3_Gateway
	SG_ DEV_ZR_SmaLi_01_Tx : 0|512@1+ (1,0) [0|1] ""  Vector__XXX

BO_ 2617219604 DEV_ZR_Tx_14: 8 ICAS3_Gateway
	SG_ DEV_ZR_Tx_14_Data : 0|64@1+ (1,0) [0|1] ""  Vector__XXX

BO_ 2617219605 DEV_ZR_Tx_15: 8 ICAS3_Gateway
	SG_ DEV_ZR_Tx_15_Data : 40|24@1+ (1,0) [0|1] ""  Vector__XXX
	SG_ MMI_State : 24|6@1+ (1,0) [0|63] ""  Vector__XXX
	SG_ Reset_Counter : 16|8@1+ (1,0) [0|253] ""  Vector__XXX
	SG_ Routeg_aktiv : 31|1@1+ (1,0) [0|1] ""  Vector__XXX
	SG_ SI_MOST_Status : 35|1@1+ (1,0) [0|1] ""  Vector__XXX
	SG_ Tel_aktiv : 30|1@1+ (1,0) [0|1] ""  Vector__XXX
	SG_ Tel_SIM_aktiv : 39|1@1+ (1,0) [0|1] ""  Vector__XXX
	SG_ ZR_KL_30F : 0|8@1+ (0.1,0) [0|25.3] "Volt"  Vector__XXX
	SG_ ZR_LastOn : 32|3@1+ (1,0) [0|6] ""  Vector__XXX
	SG_ ZR_State_DU_1 : 36|3@1+ (1,0) [0|7] ""  Vector__XXX
	SG_ ZR_TempSens : 8|8@1+ (1,-55) [-55|127] "DegreCelsi"  Vector__XXX

BO_ 2549880334 DIA_ABT_1_Req: 8 ICAS1_X_Gateway
	SG_ DIA_ABT_1_Req_Data : 0|64@1+ (1,0) [0|18446744073709551616] ""  ICAS3_Gateway,ICC_IO_Node,ZR_MIB_TOP_ab_Gen3

BO_ 2550011406 DIA_ABT_1_Resp: 8 ICAS3_Gateway
	SG_ DIA_ABT_1_Resp_Data : 0|64@1+ (1,0) [0|18446744073709551616] ""  ICAS1_X_Gateway

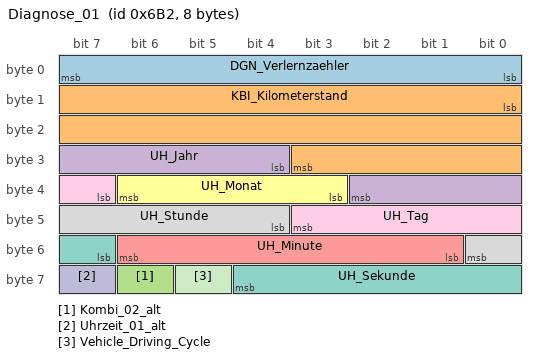
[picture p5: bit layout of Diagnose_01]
BO_ 1714 Diagnose_01: 8 ICAS1_X_Gateway
	SG_ DGN_Verlernzaehler : 0|8@1+ (1,0) [0|254] ""  Fahrerdisplay_Kombi,HUD,ICAS3_Gateway,ICC_IO_Node,Kombi,SmartLight_01,ZR_MIB_TOP_ab_Gen3
	SG_ KBI_Kilometerstand : 8|20@1+ (1,0) [0|1048573] "KiloMeter"  Fahrerdisplay_Kombi,HUD,ICAS3_Gateway,ICC_IO_Node,Kombi,SmartLight_01,ZR_MIB_TOP_ab_Gen3
	SG_ Kombi_02_alt : 62|1@1+ (1,0) [0|1] ""  ICAS3_Gateway,ICC_IO_Node,ZR_MIB_TOP_ab_Gen3
	SG_ UH_Jahr : 28|7@1+ (1,2000) [2000|2127] "Year"  Fahrerdisplay_Kombi,HUD,ICAS3_Gateway,ICC_IO_Node,Kombi,SmartLight_01,ZR_MIB_TOP_ab_Gen3
	SG_ UH_Minute : 49|6@1+ (1,0) [0|59] "Minut"  Fahrerdisplay_Kombi,HUD,ICAS3_Gateway,ICC_IO_Node,Kombi,SmartLight_01,ZR_MIB_TOP_ab_Gen3
	SG_ UH_Monat : 35|4@1+ (1,0) [1|12] "Month"  Fahrerdisplay_Kombi,HUD,ICAS3_Gateway,ICC_IO_Node,Kombi,SmartLight_01,ZR_MIB_TOP_ab_Gen3
	SG_ UH_Sekunde : 55|6@1+ (1,0) [0|59] "Secon"  Fahrerdisplay_Kombi,HUD,ICAS3_Gateway,ICC_IO_Node,Kombi,SmartLight_01,ZR_MIB_TOP_ab_Gen3
	SG_ UH_Stunde : 44|5@1+ (1,0) [0|23] "Hours"  Fahrerdisplay_Kombi,HUD,ICAS3_Gateway,ICC_IO_Node,Kombi,SmartLight_01,ZR_MIB_TOP_ab_Gen3
	SG_ UH_Tag : 39|5@1+ (1,0) [1|31] "Day"  Fahrerdisplay_Kombi,HUD,ICAS3_Gateway,ICC_IO_Node,Kombi,SmartLight_01,ZR_MIB_TOP_ab_Gen3
	SG_ Uhrzeit_01_alt : 63|1@1+ (1,0) [0|1] ""  ICAS3_Gateway,ICC_IO_Node,ZR_MIB_TOP_ab_Gen3
	SG_ Vehicle_Driving_Cycle : 61|1@1+ (1,0) [0|1] ""  ICAS3_Gateway,ICC_IO_Node,ZR_MIB_TOP_ab_Gen3

BO_TX_BU_ 2536721664 :ICAS3_Gateway;
BO_TX_BU_ 2536721680 :ICAS1_X_Gateway;
BO_TX_BU_ 2536707072 :ZR_MIB_TOP_ab_Gen3;
BO_TX_BU_ 2536707088 :ICAS1_X_Gateway;
BO_TX_BU_ 2536722944 :ICAS3_Gateway,ZR_MIB_TOP_ab_Gen3;
BO_TX_BU_ 2536722960 :ICAS1_X_Gateway;
BO_TX_BU_ 2536722434 :ICAS1_X_Gateway;
BO_TX_BU_ 2536722448 :ICAS3_Gateway,ZR_MIB_TOP_ab_Gen3;
BO_TX_BU_ 2536729088 :ICAS3_Gateway,ZR_MIB_TOP_ab_Gen3;
BO_TX_BU_ 2536729104 :ICAS1_X_Gateway;
BO_TX_BU_ 2536704000 :ICAS3_Gateway,ZR_MIB_TOP_ab_Gen3;
BO_TX_BU_ 2536704016 :ICAS1_X_Gateway;
BO_TX_BU_ 2536702208 :ICAS3_Gateway,ZR_MIB_TOP_ab_Gen3;
BO_TX_BU_ 2536702224 :ICAS1_X_Gateway;
BO_TX_BU_ 2536702464 :ICAS3_Gateway,ZR_MIB_TOP_ab_Gen3;
BO_TX_BU_ 2536702480 :ICAS1_X_Gateway;
BO_TX_BU_ 2536718848 :ICAS3_Gateway,ZR_MIB_TOP_ab_Gen3;
BO_TX_BU_ 2536718864 :ICAS1_X_Gateway;
BO_TX_BU_ 2536708352 :ICAS3_Gateway,ZR_MIB_TOP_ab_Gen3;
BO_TX_BU_ 2536708353 :ICAS3_Gateway;
BO_TX_BU_ 2536708368 :ICAS1_X_Gateway;
BO_TX_BU_ 2536715264 :Kombi;
BO_TX_BU_ 2536715280 :ZR_MIB_TOP_ab_Gen3;
BO_TX_BU_ 2536705536 :ICAS3_Gateway,ZR_MIB_TOP_ab_Gen3;
BO_TX_BU_ 2536705552 :ICAS1_X_Gateway;
BO_TX_BU_ 2536710656 :ICAS3_Gateway,ZR_MIB_TOP_ab_Gen3;
BO_TX_BU_ 2536710672 :ICAS1_X_Gateway;
BO_TX_BU_ 2536732416 :ICAS3_Gateway;
BO_TX_BU_ 2536732432 :ICAS1_X_Gateway;
BO_TX_BU_ 2536714752 :Kombi;
BO_TX_BU_ 2536714753 :Kombi;
BO_TX_BU_ 2536714768 :ZR_MIB_TOP_ab_Gen3;
BO_TX_BU_ 2536714769 :ZR_MIB_TOP_ab_Gen3;
BO_TX_BU_ 2536712704 :Kombi;
BO_TX_BU_ 2536712720 :ZR_MIB_TOP_ab_Gen3;
BO_TX_BU_ 2536704512 :ICAS3_Gateway,ZR_MIB_TOP_ab_Gen3;
BO_TX_BU_ 2536704528 :ICAS1_X_Gateway;
BO_TX_BU_ 2536704529 :ICAS1_X_Gateway;
BO_TX_BU_ 2536723712 :ICAS3_Gateway,ZR_MIB_TOP_ab_Gen3;
BO_TX_BU_ 2536723713 :ICAS3_Gateway,Kombi;
BO_TX_BU_ 2536723728 :ICAS1_X_Gateway;
BO_TX_BU_ 2536702720 :ICAS3_Gateway,ZR_MIB_TOP_ab_Gen3;
BO_TX_BU_ 2536702736 :ICAS1_X_Gateway;
BO_TX_BU_ 2536703744 :ICAS3_Gateway,ZR_MIB_TOP_ab_Gen3;
BO_TX_BU_ 2536703745 :ICAS3_Gateway;
BO_TX_BU_ 2536703747 :ICAS3_Gateway,ZR_MIB_TOP_ab_Gen3;
BO_TX_BU_ 2536703760 :ICAS1_X_Gateway;
BO_TX_BU_ 2536721921 :ICAS3_Gateway,ZR_MIB_TOP_ab_Gen3;
BO_TX_BU_ 2536721936 :ICAS1_X_Gateway;
BO_TX_BU_ 2536704768 :ICAS3_Gateway,ZR_MIB_TOP_ab_Gen3;
BO_TX_BU_ 2536704784 :ICAS1_X_Gateway;
BO_TX_BU_ 2536717056 :ICAS3_Gateway,ZR_MIB_TOP_ab_Gen3;
BO_TX_BU_ 2536717072 :ICAS1_X_Gateway;
BO_TX_BU_ 2536706560 :ZR_MIB_TOP_ab_Gen3;
BO_TX_BU_ 2536706576 :Kombi;
BO_TX_BU_ 2536706048 :ICAS3_Gateway,ZR_MIB_TOP_ab_Gen3;
BO_TX_BU_ 2536706064 :ICAS1_X_Gateway;
BO_TX_BU_ 2536710144 :ZR_MIB_TOP_ab_Gen3;
BO_TX_BU_ 2536710160 :ICAS1_X_Gateway;
BO_TX_BU_ 2536721152 :ICAS3_Gateway;
BO_TX_BU_ 2536721168 :ICAS1_X_Gateway;
BO_TX_BU_ 2536708608 :ICAS3_Gateway,ZR_MIB_TOP_ab_Gen3;
BO_TX_BU_ 2536708624 :ICAS1_X_Gateway;
BO_TX_BU_ 2536712448 :Kombi;
BO_TX_BU_ 2536712464 :ZR_MIB_TOP_ab_Gen3;
BO_TX_BU_ 2536712465 :ZR_MIB_TOP_ab_Gen3;
BO_TX_BU_ 2536712192 :Kombi;
BO_TX_BU_ 2536712193 :Kombi;
BO_TX_BU_ 2536712208 :ZR_MIB_TOP_ab_Gen3;
BO_TX_BU_ 2536712209 :ZR_MIB_TOP_ab_Gen3;
BO_TX_BU_ 2536728576 :ICAS3_Gateway;
BO_TX_BU_ 2536728592 :ICAS1_X_Gateway;
BO_TX_BU_ 2536726273 :ICAS3_Gateway;
BO_TX_BU_ 2536726288 :ICAS1_X_Gateway;
BO_TX_BU_ 2536715776 :ICAS3_Gateway,ZR_MIB_TOP_ab_Gen3;
BO_TX_BU_ 2536715792 :ICAS1_X_Gateway;
BO_TX_BU_ 2536710400 :ICAS3_Gateway,ZR_MIB_TOP_ab_Gen3;
BO_TX_BU_ 2536710401 :ICAS3_Gateway,Kombi;
BO_TX_BU_ 2536710402 :ICAS3_Gateway;
BO_TX_BU_ 2536710416 :ICAS1_X_Gateway;
BO_TX_BU_ 2536705024 :ICAS3_Gateway,ZR_MIB_TOP_ab_Gen3;
BO_TX_BU_ 2536705040 :ICAS1_X_Gateway;
BO_TX_BU_ 1626 :ICAS1_X_Gateway;
BO_TX_BU_ 2527679637 :ICAS1_X_Gateway;
BO_TX_BU_ 2463978607 :ICAS1_X_Gateway;
BO_TX_BU_ 1432 :ICAS1_X_Gateway;
BO_TX_BU_ 2527679781 :ICAS1_X_Gateway;
BO_TX_BU_ 1635 :ICAS1_X_Gateway;
BO_TX_BU_ 1163 :ICAS1_X_Gateway;
BO_TX_BU_ 2463978850 :ICAS1_X_Gateway;
BO_TX_BU_ 870 :ICAS1_X_Gateway;
BO_TX_BU_ 687 :ICAS1_X_Gateway;
BO_TX_BU_ 1482 :ICAS1_X_Gateway;
BO_TX_BU_ 903 :ICAS1_X_Gateway;
BO_TX_BU_ 902 :ICAS1_X_Gateway;
BO_TX_BU_ 918 :ICAS1_X_Gateway;
BO_TX_BU_ 2463978758 :ICAS1_X_Gateway;
BO_TX_BU_ 1012 :ICAS1_X_Gateway;
BO_TX_BU_ 2617039361 :HUD;
BO_TX_BU_ 2617039362 :HUD;
BO_TX_BU_ 2591834880 :SmartLight_01;
BO_TX_BU_ 2617219612 :ZR_MIB_TOP_ab_Gen3;
BO_TX_BU_ 2617219584 :ZR_MIB_TOP_ab_Gen3;
BO_TX_BU_ 2617219621 :ICAS3_Gateway;
BO_TX_BU_ 2617219604 :ICAS3_Gateway,ZR_MIB_TOP_ab_Gen3;
BO_TX_BU_ 2617219605 :ICAS3_Gateway,ZR_MIB_TOP_ab_Gen3;
BO_TX_BU_ 2549880334 :ICAS1_X_Gateway;
BO_TX_BU_ 2550011406 :ICAS3_Gateway,ICC_IO_Node,ZR_MIB_TOP_ab_Gen3;
BO_TX_BU_ 1714 :ICAS1_X_Gateway;
CM_ BO_ 1635 "DLC=8 ab D4 gï?½ltig";
CM_ BO_ 870 "Nur die Kombination des statischen und toggelnden Signals ergibt den Blinktakt fï?½r die Hell & Dunkelphase";
CM_ BO_ 903 "Schnittstelle EBKV - Kombi";
CM_ BO_ 902 "ab MQB 7.2.1";
CM_ SG_ 2536721664 BAP_FAS_Profiles_ASG_01_Header "FAS Profiles Anzeigesteuergeraet";
CM_ SG_ 2536721680 BAP_FAS_Profiles_FSG_01_Header "FAS Profiles Funktionssteuergeraet";
CM_ SG_ 2536707072 BAP_Homelink_ASG_01_Header "Homelink Anzeigesteuergeraet";
CM_ SG_ 2536707088 BAP_Homelink_FSG_01_Header "Homelink Funktionssteuergeraet";
CM_ SG_ 2536722944 BAP_IAA_PSO_ASG_01_Header "BAP Strecke fï?½r IAA & PSO\nAnzeigesteuergerï?½te MIB";
CM_ SG_ 2536722960 BAP_IAA_PSO_FSG_01_Header "BAP Strecke fï?½r IAA & PSO";
CM_ SG_ 2536722434 BAP_InfoSettings_ASG_03_Header "BAP Strecke fï?½r Infotainment Settings Anzeigesteuergerï?½t";
CM_ SG_ 2536722448 BAP_InfoSettings_FSG_01_Header "BAP Strecke fï?½r Infotainment Settings ï?½bergabe am Kombi\n\nRelevant nur fï?½r A1 NF und Q3 NF";
CM_ SG_ 2536729088 BAP_Innenlicht2_ASG_01_Header "Innenlicht 2 Anzeigesteuergeraet";
CM_ SG_ 2536729104 BAP_Innenlicht2_FSG_01_Header "Innenlicht 2 Funktionssteuergeraet";
CM_ SG_ 2536702208 BAP_Klima1_ASG_01_Header "BAP_Klima1_ASG_01";
CM_ SG_ 2536702224 BAP_Klima1_FSG_01_Header "BAP-Klima1_FSG_01";
CM_ SG_ 2536702464 BAP_Klima2_ASG_01_Header "BAP_Klima2_ASG_01";
CM_ SG_ 2536718848 BAP_KlimaMaster_ASG_01_Header "KlimaMaster Anzeigesteuergeraet1";
CM_ SG_ 2536718864 BAP_KlimaMaster_FSG_01_Header "KlimaMaster Funktionssteuergeraet";
CM_ SG_ 2536732416 BAP_MobDevKey_ASG_01_Header "MobDevKey Anzeigesteuergeraet 01";
CM_ SG_ 2536732432 BAP_MobDevKey_FSG_01_Header "MobDevKey Funktionssteuergeraet 01";
CM_ SG_ 2536712704 BAP_OnlineFunction_ASG_01_Header "OnlineFunctions Anzeigesteuergeraet";
CM_ SG_ 2536712720 BAP_OnlineFunction_FSG_01_Header "OnlineFunctions Funktionssteuergeraet";
CM_ SG_ 2536723712 BAP_PaCo_ASG_01_Header "PaCo Anzeigesteuergeraet";
CM_ SG_ 2536723713 BAP_PaCo_ASG_02_Header "PaCo Anzeigesteuergeraet2";
CM_ SG_ 2536723728 BAP_PaCo_FSG_01_Header "PaCo Funktionssteuergeraet";
CM_ SG_ 2536703747 BAP_RDK_ASG_04_Header "RDK Anzeigesteuergeraet\n(zusï?½tzliches Signal fï?½r abzusichernde Inhalte)";
CM_ SG_ 2536721921 BAP_RemoteServices_ASG_02_Header "RemoteServices Anzeigesteuergeraet";
CM_ SG_ 2536721936 BAP_RemoteServices_FSG_01_Header "RemoteServices Funktionssteuergeraet";
CM_ SG_ 2536704768 BAP_RVC_ASG_01_Header "Datenkanal fï?½r BAP-Katalog RVC";
CM_ SG_ 2536706048 BAP_Sitz1_ASG_01_Header "Sitz1 Anzeigesteuergeraet";
CM_ SG_ 2536721152 BAP_Sunroof_ASG_01_Header "BAP Anzeige fï?½r SAD vorderes Dachelement.";
CM_ SG_ 2536721168 BAP_Sunroof_FSG_01_Header "BAP Anzeige fï?½r SAD vorderes Dachelement.";
CM_ SG_ 2536712448 BAP_Telefon2_ASG_01_Header "MQB AUDI: keine Verwendung im ZR Entry";
CM_ SG_ 2536712464 BAP_Telefon2_FSG_01_Header "MQB AUDI: keine Verwendung im ZR Entry";
CM_ SG_ 2536712465 BAP_Telefon2_FSG_02_Header "BAP Strecke Telefon zum Kombi";
CM_ SG_ 2536712192 BAP_Telefon_ASG_01_Header "MQB AUDI: keine Verwendung im ZR Entry";
CM_ SG_ 2536712193 BAP_Telefon_ASG_02_Header "MQB AUDI: keine Verwendung im ZR Entry";
CM_ SG_ 2536712208 BAP_Telefon_FSG_01_Header "MQB AUDI: keine Verwendung im ZR Entry";
CM_ SG_ 2536712209 BAP_Telefon_FSG_02_Header "MQB AUDI: keine Verwendung im ZR Entry";
CM_ SG_ 2536728576 BAP_THA_ASG_01_Header "TrailerHitchAssist Anzeigesteuergeraet";
CM_ SG_ 2536728592 BAP_THA_FSG_01_Header "TrailerHitchAssist Funktionssteuergeraet";
CM_ SG_ 2536726273 BAP_TPA_ASG_02_Header "Parktrajektorie Anzeigesteuergerï?½t";
CM_ SG_ 2536726288 BAP_TPA_FSG_01_Header "Parktrajektorie Funktionssteuergeraet";
CM_ SG_ 1626 APS_Tongeber_defekt "Status APS-Tongeber zur HMI-Ansteuerng der RCTA-Funktion";
CM_ SG_ 1626 BCM1_AFS_Lampe "Ansteuerung der AFS-Fehlermeldung im Kombi";
CM_ SG_ 1626 BCM1_EasyEntry_Status "Status EasyEntry fï?½r Lenksï?½ule (wird auch von IVB verwendet)";
CM_ SG_ 1626 BCM1_Kl_15_HW_erkannt "Erkennung Klemme 15 (Hardware) vom BCM1\n";
CM_ SG_ 1626 BCM1_Kl_15_Sig_HW_erkannt "Erkennung Klemme 15 Signal (Hardware) vom BCM1";
CM_ SG_ 1626 BCM1_Lenksaeule_aktiv "Lenksaeulenverstellung aktiv";
CM_ SG_ 1626 BCM1_MH_Schalter "Motorhaubenkontakt";
CM_ SG_ 1626 BCM1_MH_WIV_Schalter "Bewerteter Motorhaubenkontakt fuer WIV";
CM_ SG_ 1626 BCM1_NV_Taster "BCM1_NV_Taster gibt an, ob der NightVision-Taster im Lichtdrehschalter-Modul aktuell betaetigt wird.";
CM_ SG_ 1626 BCM1_Reisemodus_Texte "Ansteuerung der Reisemodus-Texte im Kombi";
CM_ SG_ 1626 BCM1_Rueckfahrlicht_Schalter "Rï?½ckfahrlichtschalter\nab MQB/ MLBevo: Die Ganginformation wird unentprellt ï?½bertragen, im AT-Getriebe wird evtl. kurzzeitig der R-Gang angezeigt. Eine Entprellung muï?½ im Empfï?½nger erfolgen (typisch 400ms).";
CM_ SG_ 1626 BCM1_Spannungs_Anf "Forderung des BCM1-SG's zur Spannungsanhebung.";
CM_ SG_ 1626 BCM1_Valet_Parking_Taster "Valet Parking Taster ";
CM_ SG_ 1626 BCM1_Warnblink_Taster "Warnblinktaster";
CM_ SG_ 1626 BCM_Anf_AAW_MoLaWa "Signal zur Anforderung der Antrieb-Aktiv-Warnung und Motorlaufwarnung. Die Berechnung erfolgt im BCM. Die Ausgabe der Warnungen wird vom Kombiinstrument realisiert";
CM_ SG_ 1626 BCM_Bremsbelag_Sensor "Sensorsignal der Stromschleife  fï?½r Bremsbelagverschleiï?½ aktuell, entstï?½rt, unbewertet";
CM_ SG_ 1626 BCM_Bremsfluessigkeit_Sensor "Kontaktsignal des Sensorschalters fï?½r die Bremsflï?½ssigkeitsreserve aktuell, entstï?½rt, unbewertet";
CM_ SG_ 1626 BCM_Charisma_Taste2 "Betï?½tigung der Charisma-Taste 2";
CM_ SG_ 1626 BCM_Eco_Charisma_Taste "Betï?½tigung Taster ECO alias BlueKey oder Charisma";
CM_ SG_ 1626 BCM_Handbremse_Hinweis "Infotext fuer das Kombiinstrument zur Oeffnung der elektr. Heckklappe.";
CM_ SG_ 1626 BCM_HDF_betaetigt "Betï?½tigung Taster fï?½r Heckdeckelfernentriegelung in Mittelkonsole";
CM_ SG_ 1626 BCM_Hybrid_StartStopp_Taste "Betaetigung Taster 'Hybrid' oder alternativ Taster 'Start/Stopp Deaktivierung', je nach Verbau";
CM_ SG_ 1626 BCM_Hybrid_StSt_Taste_Fehler "Fehlerflag, wenn Tasterdiagnose im BCM fï?½r den StSt-Taster anschlï?½gt.";
CM_ SG_ 1626 BCM_Kuehlmittel_Sensor "Signal der Sensorelektroden fï?½r die Kï?½hlmittelreserve aktuell, entstï?½rt, bewertet (OK/Mangel)";
CM_ SG_ 1626 BCM_Kuehlmittel_Sensor_02 "Signal der zweiten Sensorelektroden fï?½r die Kï?½hlmittelreserve aktuell, entstï?½rt, bewertet (OK/Mangel)";
CM_ SG_ 1626 BCM_Offroad_Taste "Betï?½tigung der Offroad-Taste";
CM_ SG_ 1626 BCM_ValetTaster_Fkts_LED "Im MQB beschreibt das Signal nur den Zustand der Funktion Valet Parking (aktiv/ inaktiv)\nIm MLBevo wird ï?½ber das Signal zusï?½tzlich die ValetTaster_Fkts_LED (an/ aus) gesteuert";
CM_ SG_ 1626 BCM_Waschwasser_Sensor "Signal der Sensorelektroden fï?½r die Waschwasserreserve aktuell, entstï?½rt, bewertet (OK/Mangel)";
CM_ SG_ 1626 Gong_TFL_Umschaltung "Aktivierung / Deaktivierung des TFL per Affengriff wird mit einem Gong im Kombi quittiert.";
CM_ SG_ 1626 LRH_Taster "Tasterbetï?½tigung Lenkradheizung";
CM_ SG_ 2527679637 BCM_anf_VLW "ï?½ber dieses Signal wird die vom BCM errechnete Verlassenswarnung sowie die Meldung eines aktiven Rollfaehigkeitsmodus zur Ausgabe durch das Kombinstrument angefordert.";
CM_ SG_ 2527679637 BCM_LTM_Allwetterl_Status "Allwetterlicht Status zur Anzeige im Allwetterlicht-PopUp";
CM_ SG_ 2527679637 BCM_LTM_Nebell_Status "Nebellicht Status zur Anzeige im Nebellicht-PopUp";
CM_ SG_ 2527679637 BCM_LTM_Nebelschluss_Status "Nebelschlusslicht Status zur Anzeige im Nebelschlusslicht-PopUp";
CM_ SG_ 2527679637 BCM_LTM_PopUp_Anf "Anforderung der entsprechenden Anzeige im Kombi bei Aussenlichtsteuerung ï?½ber LTM (LichtTastenModul)";
CM_ SG_ 2527679637 BCM_LTM_PopUp_Inhalt "Definition Inhalt des PopUps zur Aussenlichtbedienung";
CM_ SG_ 2527679637 BCM_LTM_PopUp_Status "Auswahl der aktiven Aussenlichtfunktion im LTM PopUp";
CM_ SG_ 2527679637 BCM_LTM_PopUp_Texte "Anforderung Kombi-Texte bei Bedienung Aussenlicht ï?½ber LTM (LichtTastenModul)";
CM_ SG_ 2527679637 CPD_Warnung "Ansteuerung einer Warnung im Kombi/ iID mit Ton oder ohne Ton durch die Fkt. ChildPresenceDetection";
CM_ SG_ 2463978607 BCM_RGB_Blau "Farbanteil 'Blau'";
CM_ SG_ 2463978607 BCM_RGB_Dimmrampe "Vorgabe 'Dimmzeit' fï?½r RGB-Slave";
CM_ SG_ 2463978607 BCM_RGB_Dimmzeit_Zeitbasis "Umschaltung der Zeitbasis fï?½r die Berechnung der Dimmzeit zwischen 250ms (Altwert, log. Signalwert: 1) und 50ms (log. Signalwert: 0)";
CM_ SG_ 2463978607 BCM_RGB_Gruen "Farbanteil 'Grï?½n'";
CM_ SG_ 2463978607 BCM_RGB_Intensitaet "Intensitï?½t fï?½r RGB-Slave";
CM_ SG_ 2463978607 BCM_RGB_Normierung_Intensitaet "Normierung der Intensitï?½t fï?½r die RGB-Slaves:\n0 = keine Normierung\n1 = Normierung";
CM_ SG_ 2463978607 BCM_RGB_Rot "Farbanteil 'Rot'";
CM_ SG_ 1432 BCM_BFS_Massage_Taster "Ansteuerungs-Signalisierung der Pneumatik-Funktionen";
CM_ SG_ 1432 BCM_BFS_Multif_Taster "Ansteuerungs-Signalisierung der Pneumatik-Funktionen";
CM_ SG_ 1432 BCM_BFS_Pneumatik_Verstellung "Ansteuerungs-Signalisierung der Pneumatik-Funktionen";
CM_ SG_ 1432 BCM_BFS_Programmwippe "Ansteuerungs-Signalisierung der Pneumatik-Funktionen";
CM_ SG_ 1432 BCM_FS_Massage_Taster "Ansteuerungs-Signalisierung der Pneumatik-Funktionen";
CM_ SG_ 1432 BCM_FS_Multif_Taster "Ansteuerungs-Signalisierung der Pneumatik-Funktionen";
CM_ SG_ 1432 BCM_FS_Pneumatik_Verstellung "Ansteuerungs-Signalisierung der Pneumatik-Funktionen";
CM_ SG_ 1432 BCM_FS_Programmwippe "Ansteuerungs-Signalisierung der Pneumatik-Funktionen";
CM_ SG_ 1432 FAS_Profile_Taster "Das Signal beschreibt den Zustand der FAS-Profile-Tasters";
CM_ SG_ 1432 LIM_bCall_Taster "Statusinformation des Service Call Tasters im Dachmodul";
CM_ SG_ 1432 LIM_iCall_Taster "Betï?½tigungsstatus des Info Call Tasters im Dachmodul";
CM_ SG_ 1432 LIM_S_Rollo_hi "Schalterfeld LIM fï?½r Sonnenrolle Schiebedach hinten";
CM_ SG_ 1432 LIM_S_Rollo_vo "Schalterfeld LIM fï?½r Sonnenrolle Schiebedach vorne";
CM_ SG_ 1432 LIM_S_SAD_hi "Schalterfeld LIM fï?½r SAD hinten";
CM_ SG_ 1432 LIM_S_SAD_Vo "Schalterfeld LIM fï?½r SAD vorne";
CM_ SG_ 1432 LINDa_Touch_Event "Touch_Events fï?½r Informationen einer Funktionsauslï?½sung auf dem LINDa, welches dann fï?½r bspw. ein akustisches Signal zentral umgesetzt werden kï?½nnen.";
CM_ SG_ 1432 Tuerkontakt_Innenlicht_Taste "Taste zum ï?½ndern des Tï?½rkontakt-Lichtfunktionszustandes.";
CM_ SG_ 2527679781 LINDa_HL_SR3_Touch_Event "Touch_Events fï?½r Informationen einer Funktionsauslï?½sung auf dem LINDa (hinten links SR3) , welches dann fï?½r bspw. ein akustisches Signal zentral umgesetzt werden kï?½nnen.";
CM_ SG_ 2527679781 LINDa_HL_Touch_Event "Touch_Events fï?½r Informationen einer Funktionsauslï?½sung auf dem LINDa, welches dann fï?½r bspw. ein akustisches Signal zentral umgesetzt werden kï?½nnen.";
CM_ SG_ 2527679781 LINDa_HR_SR3_Touch_Event "Touch_Events fï?½r Informationen einer Funktionsauslï?½sung auf dem LINDa (hinten rechts SR3), welches dann fï?½r bspw. ein akustisches Signal zentral umgesetzt werden kï?½nnen.";
CM_ SG_ 2527679781 LINDa_HR_Touch_Event "Touch_Events fï?½r Informationen einer Funktionsauslï?½sung auf dem LINDa, welches dann fï?½r bspw. ein akustisches Signal zentral umgesetzt werden kï?½nnen.";
CM_ SG_ 1635 BEM_Anf_KL15_schalten "Abschaltempfehlung bzw. Verhinderung der automatischen Abschaltung Kl15 durch das BCM";
CM_ SG_ 1635 BEM_Batt_Ab "Batterieverbindungskontrolle:\n0x0: Batterie am Bordnetz\n0x1: Batterie ab erkannt";
CM_ SG_ 1635 BEM_Batteriediagnose "Anzeige von Textwarnungen";
CM_ SG_ 1635 BEM_DFM "Generatorauslastungsgrad, vom Generator ï?½ber LIN an das Gateway gesandt. Das Motorsteuergerï?½t regelt auf dieses Signal die PTC, das Energiemanagement im BSG/BCM kalkuliert die Bordnetzauslastung";
CM_ SG_ 1635 BEM_EMLIN_ungueltig "Energie-Lin - Signale sind ungï?½ltig vom Slave Batteriedatenmodul oder Generator\n0 = Signale gï?½ltig\n1 = Signale ungï?½ltig";
CM_ SG_ 1635 BEM_Generatordiagnose "Ansteuerung Generatorwarnleuchte im Kombi\n";
CM_ SG_ 1635 BEM_HL_Kontingentierung "Leistungskontingente fï?½r Heizsysteme";
CM_ SG_ 1635 BEM_HL_Regelung_Status "Status Regelung Heizleistung\n";
CM_ SG_ 1635 BEM_Ladezustand "Ladezustand der Niedervoltbatterie\n";
CM_ SG_ 1635 BEM_MMI_Vorwarnung "Anzeige Vorwarnung MMI-Abschaltung (Initialisierungswert aus EEprom)\n";
CM_ SG_ 1635 BEM_Red_Innengeblaese "Reduzierung Innengeblï?½se\n";
CM_ SG_ 1635 BEM_REK_aktiv "Rekuperationsfreigabe vom Energiemanagement\n0x0 = keine Rekuperationsfreigabe\n0x1 = Rekuperationsfreigabe";
CM_ SG_ 1635 BEM_STH_Einschaltverbot "Einschrï?½nkung Standheizung/-lï?½ftung durch BEM: Setzt der BEM das Bit, dann darf die Standheizung nicht mehr einschalten\n(Die Standheizung muss aber nicht abschalten, sondern darf weiterbrennen)\n(Initialisierungswert aus EEprom)\n";
CM_ SG_ 1635 BEM_STH_Zielzeit "Maximal mï?½gliche Zeit fï?½r den Standheizungsbetrieb, um die Startfï?½higkeit nicht zu gefï?½hrden";
CM_ SG_ 1635 BEM_UBDM "Batteriespannung, gemessen vom Batteriedatenmodul";
CM_ SG_ 1635 BEM_UGenSoll "Sollspannungsvorgabe an den Generator, beinhaltet temperaturoptimierte Batterieladung und Rekuperation";
CM_ SG_ 1635 MIB_Stromsparmodus "Signal beschreibt die Aktivierung fï?½r den Stromsparmodus beim MIB.\nBei AUS (= 0) gibt es keine weitere Anforderung an die MIB-Komponenten.\nBei EIN (= 1) werden alle MIB Komponenten in einen Stromsparmodus versetzt.";
CM_ SG_ 1635 NVEM_Abschaltstufe "Abschaltstufe aus dem Ruheenergiemanagement\nMaï?½nahmen des Empfï?½ngers werden im QLAH Ruhestrommanagement definiert";
CM_ SG_ 1635 NVEM_Anf_SD_schalten "Anforderung Nachlauf fï?½r den Steckdosenbetrieb\nInitialisierungswert aus EEprom";
CM_ SG_ 1635 NVEM_Batterie_Service "Anforderung einer Batterie-Service - Anzeige / Anforderung an die Werkstatt ï?½ber MOD";
CM_ SG_ 1635 NVEM_Freigabe_OnlineUpdate "Freigabe fï?½r Online-Update durch Energiemanagement";
CM_ SG_ 1635 NVEM_Freigabe_ORU4 "Bestï?½tigung oder Ablehnung eines konkreten, angefragten Online Updates durch das Energiemanagements";
CM_ SG_ 1635 NVEM_Freigabe_ZusBatt_Laden "NVEM gibt die Freigabe zum Schlieï?½en des Laderelais im Ruhebetrieb (z.B. bei Verwendung eines Ladegerï?½tes)";
CM_ SG_ 1635 NVEM_Verbraucherabsch_Anz "Information ï?½ber eine Verbraucherbschaltung durch das Energiemanagement";
CM_ SG_ 1163 BEM_06_BZ "4bit Botschaftszï?½hler, wird mit jeder Sendebotschaft inkrementiert";
CM_ SG_ 1163 BEM_06_CRC "Fï?½r MLB:\nBerechnung siehe Lastenheft 'Kommunikationsabsicherung fï?½r FlexRay und CAN'\nAb MQB und MLBevo:\nBerechnung siehe Lastenheft 'End-to-End Kommunikationsabsicherung'\n\nEndwerte siehe Begleitdokument 'S-PDU Kennungsfolgen'";
CM_ SG_ 1163 HLR_PTC_linear_Freigabe "Freigabe des EEM fï?½r den linearen PTC-Zuheizer";
CM_ SG_ 1163 NVEM2_Status_FuSiFahrt "Status sicherheitsrelevante Diagnosen NVEM";
CM_ SG_ 1163 NVEM2_Typ_EnergieNetz "Identifizierte NV-Energiearchitektur";
CM_ SG_ 1163 NVEM_Betriebsart "Betriebsart des Niedervolt - Energiemanagements";
CM_ SG_ 1163 NVEM_Bordnetzdiagnose "Wird vom NVEM im NV-Netz ein Bordnetz-Fehler erkannt, so soll dies zu einer mehrstufigen Anzeige fï?½hren.";
CM_ SG_ 1163 NVEM_Energie_Klima_Vorgabe "NVEM-Energievorgabe fï?½r Klima-Vorkonditionierung";
CM_ SG_ 1163 NVEM_Energienetz_Status "NVEM kommuniziert abgesichert den Zustand des Energienetzes";
CM_ SG_ 1163 NVEM_Ladezustand "Ladezustand des NV-Hauptspeichers.";
CM_ SG_ 1163 NVEM_Last_Anf "Das NVEM fordert fï?½r die Batteriediagnose einen Lastimpuls vom Fahrzeug an, der durch kontrollierte Verbraucherzuschaltungen (z. B. Aktivierung Heckscheibenheizung) generiert wird";
CM_ SG_ 1163 NVEM_PTC_Sollstufe "Vorgabe des BEM an das BCM zur Aktivierung der geforderten PTC - Stufe.\nDas MSG kopiert dies auf das Signal MO_PTC_Status";
CM_ SG_ 1163 NVEM_Red_KomfortVerbrauch "Master - SubMaster Kommunikation";
CM_ SG_ 1163 NVEM_STH_ZielzeitLang "Energetisch erlaubte Betriebszeit im Zielzeitkonzept fï?½r Standheizungen mit 2 Stunden Laufzeit";
CM_ SG_ 1163 NVEM_Vorgabe_Leistungsstufe "Ermittelte Leistungsstufe der Energiequelle";
CM_ SG_ 2463978850 NVEM2_VerbrZustandsAnf "Dieses Signal soll bei FuSi-relevanten Energienotsituationen die Reaktion bei den Nichtdynamischen Verbrauchern auslï?½sen.";
CM_ SG_ 2463978850 NVEM_Bordnetz_Information "Informationsanzeigen zum 12V - Bordnetz";
CM_ SG_ 2463978850 NVEM_EntnehmbareLadung "Im NVEM berechnetes Qe (Entnehmbare Ladung) der 12V Batterie";
CM_ SG_ 2463978850 NVEM_HVEM_FunktionsAnf "Funktionsanforderung des NVEM an das HVEM";
CM_ SG_ 2463978850 NVEM_NVStuetzungAnf "Aktivierung / Deaktivierung Primï?½renergieversorger";
CM_ SG_ 2463978850 NVEM_Verbraucher_Information "Mit diesem Signal lï?½st Das NVM eine Anzeige bzgl. einer bevorstehenden oder erfolgten Verbraucherabschaltung aus";
CM_ SG_ 870 Blinken_li_Fzg_Takt "Fzg-Takt Blinker links\n\n";
CM_ SG_ 870 Blinken_li_Kombi_Takt "Kombi-Takt Blinker links\n\n";
CM_ SG_ 870 Blinken_re_Fzg_Takt "Fzg-Takt Blinker rechts\n\n";
CM_ SG_ 870 Blinken_re_Kombi_Takt "Kombi-Takt Blinker rechts\n\n";
CM_ SG_ 870 Blinkmodi_02_BZ "4bit Botschaftszï?½hler, wird mit jeder Sendebotschaft inkrementiert";
CM_ SG_ 870 Blinkmodi_02_CRC "Fï?½r MLB:\nBerechnung siehe Lastenheft 'Kommunikationsabsicherung fï?½r FlexRay und CAN'\nAb MQB und MLBevo:\nBerechnung siehe Lastenheft 'End-to-End Kommunikationsabsicherung'\n\nEndwerte siehe Begleitdokument 'S-PDU Kennungsfolgen'";
CM_ SG_ 870 BM_Autobahn "Status Autobahnblinken\n";
CM_ SG_ 870 BM_Crash "Status Crashblinken\n";
CM_ SG_ 870 BM_DWA_Alarm "Status DWA-Alarmblinken\n";
CM_ SG_ 870 BM_DWA_ein "Status Quittierungsblinken DWA";
CM_ SG_ 870 BM_GDO "Blinken bei UGDO anlernen\n\n";
CM_ SG_ 870 BM_HD_Oeffnung_angelernt "HD_Rueckmeld_prog eine Blinkerquittierung wird beim BCM2 angefordert.\nWenn die Geschwindigkeit kleiner einer vorgegebenen Schwelle (default 2km/h) ist wird das Signal BM_HD_ï?½ffnung_angelernt versendet und die Blinkerquittierung ausgelï?½st";
CM_ SG_ 870 BM_links "Richtungsblinken links\n\n";
CM_ SG_ 870 BM_NBA_n_codiert_n_aktiv "Notbremsanzeige nicht codiert/nicht aktiv (Fehler)";
CM_ SG_ 870 BM_NBA_Status "Notbremsanzeige Status nicht aktiv / BRL Dunkelphase / BRL Hellphase";
CM_ SG_ 870 BM_Not_Bremsung "Das Signal BM_Not_Bremsung  zeigt an,  ob ein Warnblinken aufgrund einer vom Bremssystem signalisierten Notbremsung aktiv ist.";
CM_ SG_ 870 BM_Panik "Panikblinken\n";
CM_ SG_ 870 BM_PiloPa "Quittierungsblinken bei pilotierten Parkvorgï?½ngen";
CM_ SG_ 870 BM_Recas "Blinkermodus RECAS  (RearEndCollisionAlertSignal)";
CM_ SG_ 870 BM_rechts "Richtungsblinken rechts\n\n";
CM_ SG_ 870 BM_Rollenmodus_Blinken "Das Signal wird statisch gesetzt, wenn die Blinkerart Rollenmodus_Blinken aktiv ist.";
CM_ SG_ 870 BM_Taxi_Notalarm "Blinken bei Taxi-Not-Alarm\n\n";
CM_ SG_ 870 BM_Telematik "Telematikblinken\n";
CM_ SG_ 870 BM_Telematik_Abbruchgrund "Gibt bei erwaretem aber ausbleibendem Flankenanstieg der BM_Telematik an wieso die Ausfï?½hrung verhindert wurde. Bei Flankenabfall der BM_Telematik wird angegeben wieso die Ausfï?½hrung beendet wurde.\n\nBei nicht bereitem Sender soll 'init' gesendet werden,";
CM_ SG_ 870 BM_Warnblinken "Warnblinken\n\n";
CM_ SG_ 870 BM_WBT_Beleuchtung "Aktivierung Warnblinktasterfunktionsbeleuchtung\nWarnblinktasterfunktionsbeleuchtung soll aktiviert werden (statisch auf 1)";
CM_ SG_ 870 BM_Wischblinken "Blinkermodus Wisch_Blinken";
CM_ SG_ 870 BM_ZV_auf "Blinken bei ZV auf\n\n";
CM_ SG_ 870 BM_ZV_zu "Blinken bei ZV zu\n\n";
CM_ SG_ 870 DWA_Alarmquelle "Signalisiert den Auslï?½segrund der DWA";
CM_ SG_ 870 SAL_TA_Blinken_Status "SAL Rï?½ckmeldungTravelAssist Blinker-Status an Funktion TA (MFK)";
CM_ SG_ 687 BMC_Spannung "actual voltage of the battery / Momentanwert: Batteriespannung";
CM_ SG_ 687 BMS_As_Entladezaehler "Signal zur Berechnung des Lastprofils durch die RWB";
CM_ SG_ 687 BMS_As_Entladezaehler_Ueberlauf "Wird beim ersten ï?½berlauf von BMS_As_Entladezahler auf 1 gesetzt. Reset ï?½ber KL15-Wechsel";
CM_ SG_ 687 BMS_Rekuperation "Zï?½hler: Anzeigesignal: Energiezufuhr in die HV-Batterie (Reku). Darf nicht durch Laden der Batterie bedatet werden";
CM_ SG_ 687 BMS_Rekuperation_Ueberlauf "Rekuperationleistungssignal BMS_Rekuperation mindest 1x ï?½bergelaufen";
CM_ SG_ 687 BMS_Verbrauch "Zï?½hler: Energieentnahme aus der HV-Batterie";
CM_ SG_ 687 BMS_Verbrauch_Ueberlauf "Verbrauchssignal mindest 1x ï?½bergelaufen";
CM_ SG_ 1482 BMS_07_CRC "Fï?½r MLB:\n'Berechnung siehe Lastenheft 'Kommunikationsabsicherung fï?½r FlexRay und CAN''\n\nAb MQB und MLBevo:\n'Berechnung siehe Lastenheft 'End-to-End Kommunikationsabsicherung''\n\nEndwerte siehe Begleitdokument 'S-PDU Kennungsfolgen'";
CM_ SG_ 1482 BMS_Ausgleichsladung_Anf "BMS wï?½nscht eine Ausgleichsladung\nFlag derzeit ungenutzt, da BalancingModus im Detail noch nicht geklï?½rt.";
CM_ SG_ 1482 BMS_Batteriediagnose "Anzeige von Textwarnungen";
CM_ SG_ 1482 BMS_Energieinhalt "aktuell nutzbarer Energieinhalt der HV-Batterie\n(bezogen auf ein definiertes mittleres Belastungsprofil)";
CM_ SG_ 1482 BMS_Gesamtst_Spgfreiheit "0 = Funktion nicht aktiviert\n1 = HV-System spannungsfrei (U_Zwkr von BMS, LE und Ladegerï?½t < 20V, DCLadestecker nicht gesteckt und Service Disconnect entriegelt)\n2 = HV-System nicht spannungsfrei (U_Zwkr von BMS, LE und Ladegerï?½t >= 20V, Ladestecker ges";
CM_ SG_ 1482 BMS_KundenWarnung "Kunden Warnung aufgrund eines Batteriefehlers";
CM_ SG_ 1482 BMS_MaxEnergieinhalt "maximaler nutzbarer Energieinhalt der HV-Batterie (bezogen auf Last KBI_RWDS_Lastprofil bei SOC=100%)\nAbhï?½ngig von KBI_RWDS_Lastprofil";
CM_ SG_ 903 Bremse_EV_02_CRC "Fï?½r MLB:\n'Berechnung siehe Lastenheft 'Kommunikationsabsicherung fï?½r FlexRay und CAN''\n\nAb MQB und MLBevo:\n'Berechnung siehe Lastenheft 'End-to-End Kommunikationsabsicherung''\n\nEndwerte siehe Begleitdokument 'S-PDU Kennungsfolgen'";
CM_ SG_ 903 EBKV_BKL_Warnungen "Ansteuerung der BKL-Lampe";
CM_ SG_ 903 EBKV_Charisma_FahrPr "Aktuell eingestellte Kennlinie EBKV";
CM_ SG_ 903 EBKV_Charisma_Status "Systemstatus des FPA-Teilnehmers EBKV";
CM_ SG_ 903 EBKV_Hinweise "Ansteuerung der Textanzeige";
CM_ SG_ 903 EBKV_SpannungsAnf "Anforderung eines Mindest-Spannungs-Niveaus an das NVEM";
CM_ SG_ 903 EBKV_Warnungen "Ansteuerung Kombi zur Fahrerwarnung";
CM_ SG_ 903 EPB_Fehlermeldung_ext "ï?½ber das Signal werden bestimmte Fehlertexte und -lampen fï?½r den separat angeschlossenen Aktuator im Kombi angefordert. Signal wird nur im MEB verwendet.";
CM_ SG_ 903 EPB_Funktionslampe_ext "Ersatzsignal um im Fehlerfall eine Anzeige im Kombi zu triggern. Signal wird nur im MEB verwendet.";
CM_ SG_ 902 CHA_Charge_LED "Ansteuerung der LED am Charge-Taster durch Charisma im PHEV";
CM_ SG_ 902 CHA_Charisma_Taste2_LED "Ansteuerung der 2. Charisma-Taste-LED";
CM_ SG_ 902 CHA_Current_Mode "Aktuell eingestelltes Charisma Fahrprogramm";
CM_ SG_ 902 CHA_Current_Mode_FPA "Aktuell eingestelltes Charisma Fahrprogramm";
CM_ SG_ 902 CHA_Eco_Charisma_LED "Ansteuerung der Funktions-LED der ECO alias Bluekey Taste bzw. Charisma-Taste.\nDer Master der Fahrmodus-Funktion soll die Funktionsleuchte ansteuern, in der MQB Architektur ist der Master im Gateway untergebracht.";
CM_ SG_ 902 CHA_EV_LED "Ansteuerung der LED am EV-Taster durch Charisma im PHEV";
CM_ SG_ 902 CHA_Fahrer_Umschaltung "Die manuelle Umschaltung durch den Fahrer soll signalisiert werden, um zu automatischen Umschaltungen (z.B. Retries) differenzieren zu kï?½nnen.";
CM_ SG_ 902 CHA_Kombi_Texte "Anzeige des aktuellen Charisma-Fahrprofiles im Kombi.\nDie Texte werden HUT-Spezifisch in einem Schnittstellen-LAH definiert.";
CM_ SG_ 902 CHA_Kombi_Texte_02 "Anzeige von Hinweistexten bzgl. Charismaumschaltungen im Kombi.\nDie Texte werden HUT-Spezifisch in einem Schnittstellen-LAH definiert.";
CM_ SG_ 902 CHA_Offroad_LED "Ansteuerung der Offroad-LED";
CM_ SG_ 902 CHA_ReqPrgDispSetup "Requested Charisma-programm to Kombi to change display setup.";
CM_ SG_ 902 CHA_StCurProfDft "Signal indicates if the current Charisma-profile";
CM_ SG_ 902 CHA_Ziel_FahrPr_03_01 "reserviert fï?½r Anforderung Ziel-Fahrprogramm";
CM_ SG_ 902 CHA_Ziel_FahrPr_03_02 "reserviert fï?½r Anforderung Ziel-Fahrprogramm";
CM_ SG_ 902 CHA_Ziel_FahrPr_AMB "Anforderung Ziel-Fahrprogramm Ambientelichtmodul";
CM_ SG_ 902 CHA_Ziel_FahrPr_HSP "Anforderung Ziel-Fahrprogramm Heckspoiler";
CM_ SG_ 902 CHA_Ziel_FahrPr_IVB "Anforderung Ziel-Fahrprogramm IVB";
CM_ SG_ 902 CHA_Ziel_FahrPr_KL "Anforderung Ziel-Fahrprogramm Klima";
CM_ SG_ 902 CHA_Ziel_FahrPr_RWB "Anforderung Zielfahrprogramm Reichweitenberechnung (RWB)";
CM_ SG_ 918 DR_Gelbe_Warnlampe "Bit wird gesetzt, wenn wï?½hrend des Betriebes ein Fehler erkannt wird.";
CM_ SG_ 2463978758 DR_DCCMonitor_I_Add "Summen-Dï?½mpferstrom zur Anzeige im DCC-Monitor in % auf den max. Strom bezogen.";
CM_ SG_ 2463978758 DR_DCCMonitor_I_HL "Dï?½mpferstrom zur Anzeige im DCC-Monitor in % auf den max. Strom bezogen.";
CM_ SG_ 2463978758 DR_DCCMonitor_I_HR "Dï?½mpferstrom zur Anzeige im DCC-Monitor in % auf den max. Strom bezogen.";
CM_ SG_ 2463978758 DR_DCCMonitor_I_SZ_Add "Schleppzeigerwert fï?½r DR_DCCMonitor_I_Add";
CM_ SG_ 2463978758 DR_DCCMonitor_I_SZ_HL "Schleppzeigerwert fï?½r DR_DCCMonitor_I_HL";
CM_ SG_ 2463978758 DR_DCCMonitor_I_SZ_HR "Schleppzeigerwert fï?½r DR_DCCMonitor_I_HR";
CM_ SG_ 2463978758 DR_DCCMonitor_I_SZ_VL "Schleppzeigerwert fï?½r DR_DCCMonitor_I_VL";
CM_ SG_ 2463978758 DR_DCCMonitor_I_SZ_VR "Schleppzeigerwert fï?½r DR_DCCMonitor_I_VR";
CM_ SG_ 2463978758 DR_DCCMonitor_I_VL "Dï?½mpferstrom zur Anzeige im DCC-Monitor in % auf den max. Strom bezogen.";
CM_ SG_ 2463978758 DR_DCCMonitor_I_VR "Dï?½mpferstrom zur Anzeige im DCC-Monitor in % auf den max. Strom bezogen.";
CM_ SG_ 1012 DC_HYB_Auslastungsgrad "Momentanwert: Auslastung DC/DC (DFM Signal), entspricht I_akt / I_max\n(Vorhalt fï?½r MQB)";
CM_ SG_ 1012 DC_ReserveStrom_NV "Momentanwert: Stromreserve vom DC/DC-Wandler in Richtung 12V-Bordnetz\n\nTiefsetzen - positiv\nHochsetzen - negativ";
CM_ SG_ 1012 DC_Verbrauch "Energieverbrauch vom DCDC fï?½r Versorgung 12V-Bordnetz inkl. seines eigenen Wirkungsgrads (bspw.: HV_Strom*HV_Spannung*t)";
CM_ SG_ 1012 DC_Verbrauch_Ueberlauf "ï?½berlauf-Bit fï?½r das Signal DC_Verbrauch";
CM_ SG_ 1012 DC_Verlustleistung "Aktuelle Verlustleistung des DC/DC-Wandlers.";
CM_ SG_ 1012 DCDC_02_CRC "Fï?½r MLB:\n'Berechnung siehe Lastenheft 'Kommunikationsabsicherung fï?½r FlexRay und CAN''\n\nAb MQB und MLBevo:\n'Berechnung siehe Lastenheft 'End-to-End Kommunikationsabsicherung''\n\nEndwerte siehe Begleitdokument 'S-PDU Kennungsfolgen'";
CM_ SG_ 2617219605 MMI_State "Powerstate des Zentralrechners. MMI_Off wird im Zustand dead mode gesendet.";
CM_ SG_ 2617219605 Routeg_aktiv "Routenfï?½hrung aktiv\n";
CM_ SG_ 2617219605 SI_MOST_Status "Das Signal gibt den Zustand des MOST wieder.";
CM_ SG_ 2617219605 Tel_aktiv "Aktives Telefonat oder mute pin aktiv\n";
CM_ SG_ 2617219605 Tel_SIM_aktiv "SimKarte eingelegt\n\n";
CM_ SG_ 2617219605 ZR_KL_30F "Gemessene Versorgungsspannung des Zentralrechners.\n";
CM_ SG_ 2617219605 ZR_LastOn "LastOn state des Zentralrechners";
CM_ SG_ 2617219605 ZR_State_DU_1 "Kontrollbit fï?½r Display, Hintergrundbeleuchtung aus, Hintergrundbeleuchtung an, Energiesparmodus.\n";
CM_ SG_ 2617219605 ZR_TempSens "Aktueller Temperaturwert des Zentralrechners";
CM_ SG_ 2549880334 DIA_ABT_1_Req_Data "DK2F Flash Diagnosezugriff";
CM_ SG_ 2550011406 DIA_ABT_1_Resp_Data "DK2F Flash Diagnosezugriff";
CM_ SG_ 1714 DGN_Verlernzaehler "wrap around 254 --> 0";
CM_ SG_ 1714 KBI_Kilometerstand "Fehler wird ausgegeben, falls Kilometerstand nicht restaurierbar\n";
CM_ SG_ 1714 UH_Minute "0x3C- 0x3f = Werte ungï?½ltig";
CM_ SG_ 1714 UH_Monat "0x0D, 0xF =  Werte ungï?½ltig\n0x0E = Relatives Datum (nur VW)";
CM_ SG_ 1714 UH_Sekunde "0x3C- 0x3f = Werte ungï?½ltig";
CM_ SG_ 1714 UH_Stunde "0x18 - 0x1F = Werte ungï?½ltig";
CM_ SG_ 1714 UH_Tag "0x0: reserviert bei VW";
CM_ SG_ 1714 Uhrzeit_01_alt "\n";
CM_ SG_ 1714 Vehicle_Driving_Cycle "Optimierung der Inbetriebnahme von Steuergerï?½ten in einem Teilverbau in der Produktion.\nSiehe VW80114. Signal bildet (durch eine Gateway-Funktion) den Inhalt des Signals OBD_Driving_Cycle ab.";
BA_DEF_ BO_ "CANFD_BRS" ENUM "0", "1";
BA_DEF_ BO_ "DiagRequest" ENUM "No", "Yes";
BA_DEF_ BO_ "DiagResponse" ENUM "No", "Yes";
BA_DEF_ BO_ "DiagState" ENUM "No", "Yes";
BA_DEF_ BO_ "GenMsgChkConstant" HEX 0 4095;
BA_DEF_ BO_ "GenMsgCycleTime" INT 0 65535;
BA_DEF_ BO_ "GenMsgCycleTimeFast" INT 0 65535;
BA_DEF_ BO_ "GenMsgDelayTime" INT 0 100000;
BA_DEF_ BO_ "GenMsgILSupport" ENUM "No", "Yes";
BA_DEF_ BO_ "GenMsgNrOfRepetition" INT 0 100;
BA_DEF_ BO_ "GenMsgPDUConstants" STRING;
BA_DEF_ BO_ "GenMsgSendType" ENUM "Cyclic", "not_used", "not_used", "not_used", "not_used", "not_used", "not_used", "IfActive", "NoMsgSendType";
BA_DEF_ BO_ "GenMsgStartDelayTime" INT 0 100000;
BA_DEF_ BO_ "MsgType" ENUM "Application", "NM ", "NMH", "TP2.0", "ISO-TP ", "BAP", "EID", "KS", "XCP_PRE_CONFIGURED", "XCP_RUNTIME_CONFIGURED";
BA_DEF_ BO_ "NmMessage" ENUM "No", "Yes";
BA_DEF_ BO_ "NmhMessage" ENUM "No", "Yes";
BA_DEF_ BO_ "VAGTP20_API" HEX 0 255;
BA_DEF_ BO_ "VAGTP20_DynConnection" ENUM "No", "Yes";
BA_DEF_ BO_ "VAGTP20_DynSetup" ENUM "No", "Yes";
BA_DEF_ BO_ "VAGTP20_StatConnection" ENUM "No", "Yes";
BA_DEF_ BO_ "VFrameFormat" ENUM "StandardCAN", "ExtendedCAN", "reserved", "reserved", "reserved", "reserved", "reserved", "reserved", "reserved", "reserved", "reserved", "reserved", "reserved", "reserved", "StandardCAN_FD", "ExtendedCAN_FD";
BA_DEF_ SG_ "Fehlerwert" HEX 0 2147483647;
BA_DEF_ SG_ "GenSigActiveRepetitions" INT -2147483648 2147483647;
BA_DEF_ SG_ "GenSigFuncType" ENUM "NoFunction", "MsgCounter", "CRC-8", "XOR", "XOR-2", "DatedBit", "SW-Kl15", "CHK", "Constant", "Protocol", "CRC-8-SAE_J1850", "CRC-32", "DataLength", "DataID", "MsgCounter16", "SOK-Signatur", "Cluster";
BA_DEF_ SG_ "GenSigInactiveValue" INT -2147483648 2147483647;
BA_DEF_ SG_ "GenSigMissingSourceValue" HEX 0 2147483647;
BA_DEF_ SG_ "GenSigSendType" ENUM "Cyclic", "OnWrite", "OnWriteWithRepetition", "OnChange", "OnChangeWithRepetition", "IfActive", "IfActiveWithRepetition", "NoSigSendType", "OnChangeAndIfActive", "OnChangeAndIfActiveWithRepetition";
BA_DEF_ SG_ "GenSigStartValue" INT -2147483648 2147483647;
BA_DEF_ SG_ "GenSigSwitchedByIgnition" ENUM "No", "Yes";
BA_DEF_ SG_ "NWM-WakeupAllowed" ENUM "No", "Yes";

BA_DEF_REL_ BU_SG_REL_ "GenSigTimeoutTime" INT 0 65535;
BA_DEF_DEF_ "CANFD_BRS" "1";
BA_DEF_DEF_ "DiagRequest" "No";
BA_DEF_DEF_ "DiagResponse" "No";
BA_DEF_DEF_ "DiagState" "No";
BA_DEF_DEF_ "Fehlerwert" 0;
BA_DEF_DEF_ "GenMsgChkConstant" 0;
BA_DEF_DEF_ "GenMsgCycleTime" 0;
BA_DEF_DEF_ "GenMsgCycleTimeFast" 0;
BA_DEF_DEF_ "GenMsgDelayTime" 0;
BA_DEF_DEF_ "GenMsgILSupport" "No";
BA_DEF_DEF_ "GenMsgNrOfRepetition" 0;
BA_DEF_DEF_ "GenMsgPDUConstants" "";
BA_DEF_DEF_ "GenMsgSendType" "NoMsgSendType";
BA_DEF_DEF_ "GenMsgStartDelayTime" 0;
BA_DEF_DEF_ "GenSigActiveRepetitions" 0;
BA_DEF_DEF_ "GenSigFuncType" "NoFunction";
BA_DEF_DEF_ "GenSigInactiveValue" 0;
BA_DEF_DEF_ "GenSigMissingSourceValue" 0;
BA_DEF_DEF_ "GenSigSendType" "NoSigSendType";
BA_DEF_DEF_ "GenSigStartValue" 0;
BA_DEF_DEF_ "GenSigSwitchedByIgnition" "Yes";
BA_DEF_DEF_ "MsgType" "Application";
BA_DEF_DEF_ "NWM-WakeupAllowed" "No";
BA_DEF_DEF_ "NmMessage" "No";
BA_DEF_DEF_ "NmhMessage" "No";
BA_DEF_DEF_ "VAGTP20_API" 0;
BA_DEF_DEF_ "VAGTP20_DynConnection" "No";
BA_DEF_DEF_ "VAGTP20_DynSetup" "No";
BA_DEF_DEF_ "VAGTP20_StatConnection" "No";
BA_DEF_DEF_ "VFrameFormat" "StandardCAN";
BA_DEF_DEF_REL_ "GenSigTimeoutTime" 0;
BA_ "GenMsgCycleTimeFast" BO_ 2536721664 80;
BA_ "GenMsgSendType" BO_ 2536721664 7;
BA_ "MsgType" BO_ 2536721664 5;
BA_ "VFrameFormat" BO_ 2536721664 15;
BA_ "GenMsgCycleTime" BO_ 2536721680 1000;
BA_ "GenMsgCycleTimeFast" BO_ 2536721680 50;
BA_ "GenMsgSendType" BO_ 2536721680 7;
BA_ "MsgType" BO_ 2536721680 5;
BA_ "VFrameFormat" BO_ 2536721680 15;
BA_ "GenMsgCycleTimeFast" BO_ 2536707072 120;
BA_ "GenMsgSendType" BO_ 2536707072 7;
BA_ "MsgType" BO_ 2536707072 5;
BA_ "VFrameFormat" BO_ 2536707072 15;
BA_ "GenMsgCycleTime" BO_ 2536707088 1000;
BA_ "GenMsgCycleTimeFast" BO_ 2536707088 80;
BA_ "GenMsgSendType" BO_ 2536707088 7;
BA_ "MsgType" BO_ 2536707088 5;
BA_ "VFrameFormat" BO_ 2536707088 15;
BA_ "GenMsgCycleTimeFast" BO_ 2536722944 80;
BA_ "GenMsgSendType" BO_ 2536722944 7;
BA_ "MsgType" BO_ 2536722944 5;
BA_ "VFrameFormat" BO_ 2536722944 15;
BA_ "GenMsgCycleTime" BO_ 2536722960 1000;
BA_ "GenMsgCycleTimeFast" BO_ 2536722960 50;
BA_ "GenMsgSendType" BO_ 2536722960 7;
BA_ "MsgType" BO_ 2536722960 5;
BA_ "VFrameFormat" BO_ 2536722960 15;
BA_ "GenMsgCycleTimeFast" BO_ 2536722434 10;
BA_ "GenMsgSendType" BO_ 2536722434 7;
BA_ "MsgType" BO_ 2536722434 5;
BA_ "VFrameFormat" BO_ 2536722434 15;
BA_ "GenMsgCycleTime" BO_ 2536722448 1000;
BA_ "GenMsgCycleTimeFast" BO_ 2536722448 10;
BA_ "GenMsgSendType" BO_ 2536722448 7;
BA_ "MsgType" BO_ 2536722448 5;
BA_ "VFrameFormat" BO_ 2536722448 15;
BA_ "GenMsgCycleTimeFast" BO_ 2536729088 80;
BA_ "GenMsgSendType" BO_ 2536729088 7;
BA_ "MsgType" BO_ 2536729088 5;
BA_ "VFrameFormat" BO_ 2536729088 15;
BA_ "GenMsgCycleTime" BO_ 2536729104 1000;
BA_ "GenMsgCycleTimeFast" BO_ 2536729104 50;
BA_ "GenMsgSendType" BO_ 2536729104 7;
BA_ "MsgType" BO_ 2536729104 5;
BA_ "VFrameFormat" BO_ 2536729104 15;
BA_ "DiagState" BO_ 2536704000 1;
BA_ "GenMsgCycleTimeFast" BO_ 2536704000 80;
BA_ "GenMsgSendType" BO_ 2536704000 7;
BA_ "MsgType" BO_ 2536704000 5;
BA_ "VFrameFormat" BO_ 2536704000 15;
BA_ "GenMsgCycleTime" BO_ 2536704016 1000;
BA_ "GenMsgCycleTimeFast" BO_ 2536704016 50;
BA_ "GenMsgSendType" BO_ 2536704016 7;
BA_ "MsgType" BO_ 2536704016 5;
BA_ "VFrameFormat" BO_ 2536704016 15;
BA_ "GenMsgCycleTimeFast" BO_ 2536702208 80;
BA_ "GenMsgSendType" BO_ 2536702208 7;
BA_ "MsgType" BO_ 2536702208 5;
BA_ "VFrameFormat" BO_ 2536702208 15;
BA_ "GenMsgCycleTime" BO_ 2536702224 1000;
BA_ "GenMsgCycleTimeFast" BO_ 2536702224 50;
BA_ "GenMsgSendType" BO_ 2536702224 7;
BA_ "MsgType" BO_ 2536702224 5;
BA_ "VFrameFormat" BO_ 2536702224 15;
BA_ "GenMsgCycleTimeFast" BO_ 2536702464 80;
BA_ "GenMsgSendType" BO_ 2536702464 7;
BA_ "MsgType" BO_ 2536702464 5;
BA_ "VFrameFormat" BO_ 2536702464 15;
BA_ "GenMsgCycleTime" BO_ 2536702480 1000;
BA_ "GenMsgCycleTimeFast" BO_ 2536702480 50;
BA_ "GenMsgSendType" BO_ 2536702480 7;
BA_ "MsgType" BO_ 2536702480 5;
BA_ "VFrameFormat" BO_ 2536702480 15;
BA_ "GenMsgCycleTimeFast" BO_ 2536718848 80;
BA_ "GenMsgSendType" BO_ 2536718848 7;
BA_ "MsgType" BO_ 2536718848 5;
BA_ "VFrameFormat" BO_ 2536718848 15;
BA_ "GenMsgCycleTime" BO_ 2536718864 1000;
BA_ "GenMsgCycleTimeFast" BO_ 2536718864 50;
BA_ "GenMsgSendType" BO_ 2536718864 7;
BA_ "MsgType" BO_ 2536718864 5;
BA_ "VFrameFormat" BO_ 2536718864 15;
BA_ "GenMsgCycleTimeFast" BO_ 2536708352 80;
BA_ "GenMsgSendType" BO_ 2536708352 7;
BA_ "MsgType" BO_ 2536708352 5;
BA_ "VFrameFormat" BO_ 2536708352 15;
BA_ "GenMsgCycleTimeFast" BO_ 2536708353 80;
BA_ "GenMsgSendType" BO_ 2536708353 7;
BA_ "MsgType" BO_ 2536708353 5;
BA_ "VFrameFormat" BO_ 2536708353 15;
BA_ "GenMsgCycleTime" BO_ 2536708368 1000;
BA_ "GenMsgCycleTimeFast" BO_ 2536708368 50;
BA_ "GenMsgSendType" BO_ 2536708368 7;
BA_ "MsgType" BO_ 2536708368 5;
BA_ "VFrameFormat" BO_ 2536708368 15;
BA_ "GenMsgCycleTimeFast" BO_ 2536715264 80;
BA_ "GenMsgSendType" BO_ 2536715264 7;
BA_ "MsgType" BO_ 2536715264 5;
BA_ "VFrameFormat" BO_ 2536715264 15;
BA_ "GenMsgCycleTime" BO_ 2536715280 1000;
BA_ "GenMsgCycleTimeFast" BO_ 2536715280 50;
BA_ "GenMsgSendType" BO_ 2536715280 7;
BA_ "MsgType" BO_ 2536715280 5;
BA_ "VFrameFormat" BO_ 2536715280 15;
BA_ "GenMsgCycleTimeFast" BO_ 2536705536 80;
BA_ "GenMsgSendType" BO_ 2536705536 7;
BA_ "MsgType" BO_ 2536705536 5;
BA_ "VFrameFormat" BO_ 2536705536 15;
BA_ "GenMsgCycleTime" BO_ 2536705552 1000;
BA_ "GenMsgCycleTimeFast" BO_ 2536705552 50;
BA_ "GenMsgSendType" BO_ 2536705552 7;
BA_ "MsgType" BO_ 2536705552 5;
BA_ "VFrameFormat" BO_ 2536705552 15;
BA_ "GenMsgCycleTimeFast" BO_ 2536710656 80;
BA_ "GenMsgSendType" BO_ 2536710656 7;
BA_ "MsgType" BO_ 2536710656 5;
BA_ "VFrameFormat" BO_ 2536710656 15;
BA_ "GenMsgCycleTime" BO_ 2536710672 1000;
BA_ "GenMsgCycleTimeFast" BO_ 2536710672 50;
BA_ "GenMsgSendType" BO_ 2536710672 7;
BA_ "MsgType" BO_ 2536710672 5;
BA_ "VFrameFormat" BO_ 2536710672 15;
BA_ "GenMsgCycleTimeFast" BO_ 2536732416 80;
BA_ "GenMsgSendType" BO_ 2536732416 7;
BA_ "MsgType" BO_ 2536732416 5;
BA_ "VFrameFormat" BO_ 2536732416 15;
BA_ "GenMsgCycleTime" BO_ 2536732432 1000;
BA_ "GenMsgCycleTimeFast" BO_ 2536732432 50;
BA_ "GenMsgSendType" BO_ 2536732432 7;
BA_ "MsgType" BO_ 2536732432 5;
BA_ "VFrameFormat" BO_ 2536732432 15;
BA_ "GenMsgCycleTimeFast" BO_ 2536714752 30;
BA_ "GenMsgSendType" BO_ 2536714752 7;
BA_ "MsgType" BO_ 2536714752 5;
BA_ "VFrameFormat" BO_ 2536714752 15;
BA_ "GenMsgCycleTimeFast" BO_ 2536714753 50;
BA_ "GenMsgSendType" BO_ 2536714753 7;
BA_ "MsgType" BO_ 2536714753 5;
BA_ "VFrameFormat" BO_ 2536714753 15;
BA_ "GenMsgCycleTime" BO_ 2536714768 1000;
BA_ "GenMsgCycleTimeFast" BO_ 2536714768 30;
BA_ "GenMsgSendType" BO_ 2536714768 7;
BA_ "MsgType" BO_ 2536714768 5;
BA_ "VFrameFormat" BO_ 2536714768 15;
BA_ "GenMsgCycleTime" BO_ 2536714769 1000;
BA_ "GenMsgCycleTimeFast" BO_ 2536714769 10;
BA_ "GenMsgSendType" BO_ 2536714769 7;
BA_ "MsgType" BO_ 2536714769 5;
BA_ "VFrameFormat" BO_ 2536714769 15;
BA_ "GenMsgCycleTimeFast" BO_ 2536712704 80;
BA_ "GenMsgSendType" BO_ 2536712704 7;
BA_ "MsgType" BO_ 2536712704 5;
BA_ "VFrameFormat" BO_ 2536712704 15;
BA_ "GenMsgCycleTime" BO_ 2536712720 1000;
BA_ "GenMsgCycleTimeFast" BO_ 2536712720 50;
BA_ "GenMsgSendType" BO_ 2536712720 7;
BA_ "MsgType" BO_ 2536712720 5;
BA_ "VFrameFormat" BO_ 2536712720 15;
BA_ "GenMsgCycleTimeFast" BO_ 2536704512 80;
BA_ "GenMsgSendType" BO_ 2536704512 7;
BA_ "MsgType" BO_ 2536704512 5;
BA_ "VFrameFormat" BO_ 2536704512 15;
BA_ "GenMsgCycleTime" BO_ 2536704528 1000;
BA_ "GenMsgCycleTimeFast" BO_ 2536704528 50;
BA_ "GenMsgSendType" BO_ 2536704528 7;
BA_ "MsgType" BO_ 2536704528 5;
BA_ "VFrameFormat" BO_ 2536704528 15;
BA_ "GenMsgCycleTime" BO_ 2536704529 1000;
BA_ "GenMsgCycleTimeFast" BO_ 2536704529 50;
BA_ "GenMsgSendType" BO_ 2536704529 7;
BA_ "MsgType" BO_ 2536704529 5;
BA_ "VFrameFormat" BO_ 2536704529 15;
BA_ "GenMsgCycleTimeFast" BO_ 2536723712 20;
BA_ "GenMsgSendType" BO_ 2536723712 7;
BA_ "MsgType" BO_ 2536723712 5;
BA_ "VFrameFormat" BO_ 2536723712 15;
BA_ "GenMsgCycleTimeFast" BO_ 2536723713 20;
BA_ "GenMsgSendType" BO_ 2536723713 7;
BA_ "MsgType" BO_ 2536723713 5;
BA_ "VFrameFormat" BO_ 2536723713 15;
BA_ "GenMsgCycleTime" BO_ 2536723728 1000;
BA_ "GenMsgCycleTimeFast" BO_ 2536723728 20;
BA_ "GenMsgSendType" BO_ 2536723728 7;
BA_ "MsgType" BO_ 2536723728 5;
BA_ "VFrameFormat" BO_ 2536723728 15;
BA_ "GenMsgCycleTimeFast" BO_ 2536702720 80;
BA_ "GenMsgSendType" BO_ 2536702720 7;
BA_ "MsgType" BO_ 2536702720 5;
BA_ "VFrameFormat" BO_ 2536702720 15;
BA_ "GenMsgCycleTime" BO_ 2536702736 1000;
BA_ "GenMsgCycleTimeFast" BO_ 2536702736 50;
BA_ "GenMsgSendType" BO_ 2536702736 7;
BA_ "MsgType" BO_ 2536702736 5;
BA_ "VFrameFormat" BO_ 2536702736 15;
BA_ "GenMsgCycleTimeFast" BO_ 2536703744 80;
BA_ "GenMsgSendType" BO_ 2536703744 7;
BA_ "MsgType" BO_ 2536703744 5;
BA_ "VFrameFormat" BO_ 2536703744 15;
BA_ "GenMsgCycleTimeFast" BO_ 2536703745 80;
BA_ "GenMsgSendType" BO_ 2536703745 7;
BA_ "MsgType" BO_ 2536703745 5;
BA_ "VFrameFormat" BO_ 2536703745 15;
BA_ "GenMsgCycleTimeFast" BO_ 2536703747 80;
BA_ "GenMsgSendType" BO_ 2536703747 7;
BA_ "MsgType" BO_ 2536703747 5;
BA_ "VFrameFormat" BO_ 2536703747 15;
BA_ "GenMsgCycleTime" BO_ 2536703760 1000;
BA_ "GenMsgCycleTimeFast" BO_ 2536703760 50;
BA_ "GenMsgSendType" BO_ 2536703760 7;
BA_ "MsgType" BO_ 2536703760 5;
BA_ "VFrameFormat" BO_ 2536703760 15;
BA_ "GenMsgCycleTimeFast" BO_ 2536721921 80;
BA_ "GenMsgSendType" BO_ 2536721921 7;
BA_ "MsgType" BO_ 2536721921 5;
BA_ "VFrameFormat" BO_ 2536721921 15;
BA_ "GenMsgCycleTime" BO_ 2536721936 1000;
BA_ "GenMsgCycleTimeFast" BO_ 2536721936 50;
BA_ "GenMsgSendType" BO_ 2536721936 7;
BA_ "MsgType" BO_ 2536721936 5;
BA_ "VFrameFormat" BO_ 2536721936 15;
BA_ "GenMsgCycleTimeFast" BO_ 2536704768 80;
BA_ "GenMsgSendType" BO_ 2536704768 7;
BA_ "MsgType" BO_ 2536704768 5;
BA_ "VFrameFormat" BO_ 2536704768 15;
BA_ "GenMsgCycleTime" BO_ 2536704784 1000;
BA_ "GenMsgCycleTimeFast" BO_ 2536704784 50;
BA_ "GenMsgSendType" BO_ 2536704784 7;
BA_ "MsgType" BO_ 2536704784 5;
BA_ "VFrameFormat" BO_ 2536704784 15;
BA_ "GenMsgCycleTimeFast" BO_ 2536717056 80;
BA_ "GenMsgSendType" BO_ 2536717056 7;
BA_ "MsgType" BO_ 2536717056 5;
BA_ "VFrameFormat" BO_ 2536717056 15;
BA_ "GenMsgCycleTime" BO_ 2536717072 1000;
BA_ "GenMsgCycleTimeFast" BO_ 2536717072 50;
BA_ "GenMsgSendType" BO_ 2536717072 7;
BA_ "MsgType" BO_ 2536717072 5;
BA_ "VFrameFormat" BO_ 2536717072 15;
BA_ "GenMsgCycleTimeFast" BO_ 2536706560 80;
BA_ "GenMsgSendType" BO_ 2536706560 7;
BA_ "MsgType" BO_ 2536706560 5;
BA_ "VFrameFormat" BO_ 2536706560 15;
BA_ "GenMsgCycleTime" BO_ 2536706576 1000;
BA_ "GenMsgCycleTimeFast" BO_ 2536706576 50;
BA_ "GenMsgSendType" BO_ 2536706576 7;
BA_ "MsgType" BO_ 2536706576 5;
BA_ "VFrameFormat" BO_ 2536706576 15;
BA_ "GenMsgCycleTimeFast" BO_ 2536706048 80;
BA_ "GenMsgSendType" BO_ 2536706048 7;
BA_ "MsgType" BO_ 2536706048 5;
BA_ "VFrameFormat" BO_ 2536706048 15;
BA_ "GenMsgCycleTime" BO_ 2536706064 1000;
BA_ "GenMsgCycleTimeFast" BO_ 2536706064 50;
BA_ "GenMsgSendType" BO_ 2536706064 7;
BA_ "MsgType" BO_ 2536706064 5;
BA_ "VFrameFormat" BO_ 2536706064 15;
BA_ "GenMsgCycleTimeFast" BO_ 2536710144 80;
BA_ "GenMsgSendType" BO_ 2536710144 7;
BA_ "MsgType" BO_ 2536710144 5;
BA_ "VFrameFormat" BO_ 2536710144 15;
BA_ "GenMsgCycleTime" BO_ 2536710160 1000;
BA_ "GenMsgCycleTimeFast" BO_ 2536710160 50;
BA_ "GenMsgSendType" BO_ 2536710160 7;
BA_ "MsgType" BO_ 2536710160 5;
BA_ "VFrameFormat" BO_ 2536710160 15;
BA_ "GenMsgCycleTimeFast" BO_ 2536721152 80;
BA_ "GenMsgSendType" BO_ 2536721152 7;
BA_ "MsgType" BO_ 2536721152 5;
BA_ "VFrameFormat" BO_ 2536721152 15;
BA_ "GenMsgCycleTime" BO_ 2536721168 1000;
BA_ "GenMsgCycleTimeFast" BO_ 2536721168 50;
BA_ "GenMsgSendType" BO_ 2536721168 7;
BA_ "MsgType" BO_ 2536721168 5;
BA_ "VFrameFormat" BO_ 2536721168 15;
BA_ "GenMsgCycleTimeFast" BO_ 2536708608 80;
BA_ "GenMsgSendType" BO_ 2536708608 7;
BA_ "MsgType" BO_ 2536708608 5;
BA_ "VFrameFormat" BO_ 2536708608 15;
BA_ "GenMsgCycleTime" BO_ 2536708624 1000;
BA_ "GenMsgCycleTimeFast" BO_ 2536708624 50;
BA_ "GenMsgSendType" BO_ 2536708624 7;
BA_ "MsgType" BO_ 2536708624 5;
BA_ "VFrameFormat" BO_ 2536708624 15;
BA_ "GenMsgCycleTimeFast" BO_ 2536712448 80;
BA_ "GenMsgSendType" BO_ 2536712448 7;
BA_ "MsgType" BO_ 2536712448 5;
BA_ "VFrameFormat" BO_ 2536712448 15;
BA_ "GenMsgCycleTime" BO_ 2536712464 1000;
BA_ "GenMsgCycleTimeFast" BO_ 2536712464 50;
BA_ "GenMsgSendType" BO_ 2536712464 7;
BA_ "MsgType" BO_ 2536712464 5;
BA_ "VFrameFormat" BO_ 2536712464 15;
BA_ "GenMsgCycleTime" BO_ 2536712465 1000;
BA_ "GenMsgCycleTimeFast" BO_ 2536712465 50;
BA_ "GenMsgSendType" BO_ 2536712465 7;
BA_ "MsgType" BO_ 2536712465 5;
BA_ "VFrameFormat" BO_ 2536712465 15;
BA_ "GenMsgCycleTimeFast" BO_ 2536712192 30;
BA_ "GenMsgSendType" BO_ 2536712192 7;
BA_ "MsgType" BO_ 2536712192 5;
BA_ "VFrameFormat" BO_ 2536712192 15;
BA_ "GenMsgCycleTimeFast" BO_ 2536712193 50;
BA_ "GenMsgSendType" BO_ 2536712193 7;
BA_ "MsgType" BO_ 2536712193 5;
BA_ "VFrameFormat" BO_ 2536712193 15;
BA_ "GenMsgCycleTime" BO_ 2536712208 1000;
BA_ "GenMsgCycleTimeFast" BO_ 2536712208 30;
BA_ "GenMsgSendType" BO_ 2536712208 7;
BA_ "MsgType" BO_ 2536712208 5;
BA_ "VFrameFormat" BO_ 2536712208 15;
BA_ "GenMsgCycleTime" BO_ 2536712209 1000;
BA_ "GenMsgCycleTimeFast" BO_ 2536712209 10;
BA_ "GenMsgSendType" BO_ 2536712209 7;
BA_ "MsgType" BO_ 2536712209 5;
BA_ "VFrameFormat" BO_ 2536712209 15;
BA_ "GenMsgCycleTimeFast" BO_ 2536728576 80;
BA_ "GenMsgSendType" BO_ 2536728576 7;
BA_ "MsgType" BO_ 2536728576 5;
BA_ "VFrameFormat" BO_ 2536728576 15;
BA_ "GenMsgCycleTime" BO_ 2536728592 1000;
BA_ "GenMsgCycleTimeFast" BO_ 2536728592 50;
BA_ "GenMsgSendType" BO_ 2536728592 7;
BA_ "MsgType" BO_ 2536728592 5;
BA_ "VFrameFormat" BO_ 2536728592 15;
BA_ "GenMsgCycleTimeFast" BO_ 2536726273 80;
BA_ "GenMsgSendType" BO_ 2536726273 7;
BA_ "MsgType" BO_ 2536726273 5;
BA_ "VFrameFormat" BO_ 2536726273 15;
BA_ "GenMsgCycleTime" BO_ 2536726288 1000;
BA_ "GenMsgCycleTimeFast" BO_ 2536726288 20;
BA_ "GenMsgSendType" BO_ 2536726288 7;
BA_ "MsgType" BO_ 2536726288 5;
BA_ "VFrameFormat" BO_ 2536726288 15;
BA_ "GenMsgCycleTimeFast" BO_ 2536715776 80;
BA_ "GenMsgSendType" BO_ 2536715776 7;
BA_ "MsgType" BO_ 2536715776 5;
BA_ "VFrameFormat" BO_ 2536715776 15;
BA_ "GenMsgCycleTime" BO_ 2536715792 1000;
BA_ "GenMsgCycleTimeFast" BO_ 2536715792 50;
BA_ "GenMsgSendType" BO_ 2536715792 7;
BA_ "MsgType" BO_ 2536715792 5;
BA_ "VFrameFormat" BO_ 2536715792 15;
BA_ "GenMsgCycleTime" BO_ 2536710400 1000;
BA_ "GenMsgCycleTimeFast" BO_ 2536710400 80;
BA_ "GenMsgSendType" BO_ 2536710400 7;
BA_ "MsgType" BO_ 2536710400 5;
BA_ "VFrameFormat" BO_ 2536710400 15;
BA_ "GenMsgCycleTime" BO_ 2536710401 1000;
BA_ "GenMsgCycleTimeFast" BO_ 2536710401 80;
BA_ "GenMsgSendType" BO_ 2536710401 7;
BA_ "MsgType" BO_ 2536710401 5;
BA_ "VFrameFormat" BO_ 2536710401 15;
BA_ "GenMsgCycleTime" BO_ 2536710402 1000;
BA_ "GenMsgCycleTimeFast" BO_ 2536710402 80;
BA_ "GenMsgSendType" BO_ 2536710402 7;
BA_ "MsgType" BO_ 2536710402 5;
BA_ "VFrameFormat" BO_ 2536710402 15;
BA_ "GenMsgCycleTime" BO_ 2536710416 1000;
BA_ "GenMsgCycleTimeFast" BO_ 2536710416 50;
BA_ "GenMsgSendType" BO_ 2536710416 7;
BA_ "MsgType" BO_ 2536710416 5;
BA_ "VFrameFormat" BO_ 2536710416 15;
BA_ "GenMsgCycleTimeFast" BO_ 2536705024 80;
BA_ "GenMsgSendType" BO_ 2536705024 7;
BA_ "MsgType" BO_ 2536705024 5;
BA_ "VFrameFormat" BO_ 2536705024 15;
BA_ "GenMsgCycleTime" BO_ 2536705040 1000;
BA_ "GenMsgCycleTimeFast" BO_ 2536705040 50;
BA_ "GenMsgSendType" BO_ 2536705040 7;
BA_ "MsgType" BO_ 2536705040 5;
BA_ "VFrameFormat" BO_ 2536705040 15;
BA_ "GenMsgCycleTime" BO_ 1626 1000;
BA_ "GenMsgCycleTimeFast" BO_ 1626 100;
BA_ "GenMsgDelayTime" BO_ 1626 30;
BA_ "GenMsgILSupport" BO_ 1626 1;
BA_ "GenMsgNrOfRepetition" BO_ 1626 5;
BA_ "GenMsgSendType" BO_ 1626 0;
BA_ "VFrameFormat" BO_ 1626 14;
BA_ "GenMsgCycleTime" BO_ 2527679637 1000;
BA_ "GenMsgDelayTime" BO_ 2527679637 50;
BA_ "GenMsgILSupport" BO_ 2527679637 1;
BA_ "GenMsgSendType" BO_ 2527679637 0;
BA_ "VFrameFormat" BO_ 2527679637 15;
BA_ "GenMsgCycleTime" BO_ 2463978607 200;
BA_ "GenMsgDelayTime" BO_ 2463978607 20;
BA_ "GenMsgILSupport" BO_ 2463978607 1;
BA_ "GenMsgSendType" BO_ 2463978607 0;
BA_ "VFrameFormat" BO_ 2463978607 15;
BA_ "GenMsgCycleTime" BO_ 1432 1000;
BA_ "GenMsgCycleTimeFast" BO_ 1432 100;
BA_ "GenMsgDelayTime" BO_ 1432 20;
BA_ "GenMsgILSupport" BO_ 1432 1;
BA_ "GenMsgNrOfRepetition" BO_ 1432 5;
BA_ "GenMsgSendType" BO_ 1432 0;
BA_ "VFrameFormat" BO_ 1432 14;
BA_ "GenMsgCycleTime" BO_ 2527679781 1000;
BA_ "GenMsgDelayTime" BO_ 2527679781 20;
BA_ "GenMsgILSupport" BO_ 2527679781 1;
BA_ "GenMsgSendType" BO_ 2527679781 0;
BA_ "VFrameFormat" BO_ 2527679781 15;
BA_ "GenMsgCycleTime" BO_ 1635 100;
BA_ "GenMsgILSupport" BO_ 1635 1;
BA_ "GenMsgSendType" BO_ 1635 0;
BA_ "VFrameFormat" BO_ 1635 14;
BA_ "GenMsgCycleTime" BO_ 1163 100;
BA_ "GenMsgILSupport" BO_ 1163 1;
BA_ "GenMsgPDUConstants" BO_ 1163 "0x54,0xaf,0x8a,0xfb,0x0d,0x87,0x6a,0x0f,0x47,0x78,0x31,0x4f,0x35,0x28,0x82,0x6d";
BA_ "GenMsgSendType" BO_ 1163 0;
BA_ "VFrameFormat" BO_ 1163 14;
BA_ "GenMsgCycleTime" BO_ 2463978850 100;
BA_ "GenMsgILSupport" BO_ 2463978850 1;
BA_ "GenMsgPDUConstants" BO_ 2463978850 "0xaa,0xa9,0xe6,0xc5,0xc4,0x2b,0x0b,0x8e,0xfb,0x15,0xa4,0x64,0x1e,0x20,0x50,0x95";
BA_ "GenMsgSendType" BO_ 2463978850 0;
BA_ "VFrameFormat" BO_ 2463978850 15;
BA_ "GenMsgCycleTime" BO_ 870 1000;
BA_ "GenMsgCycleTimeFast" BO_ 870 50;
BA_ "GenMsgDelayTime" BO_ 870 10;
BA_ "GenMsgILSupport" BO_ 870 1;
BA_ "GenMsgNrOfRepetition" BO_ 870 5;
BA_ "GenMsgPDUConstants" BO_ 870 "0xa9,0xbd,0xfb,0x3c,0x95,0x0f,0x75,0x3a,0x4f,0x19,0x59,0x6d,0xb2,0xe9,0xd1,0x97";
BA_ "GenMsgSendType" BO_ 870 0;
BA_ "VFrameFormat" BO_ 870 14;
BA_ "GenMsgCycleTime" BO_ 687 50;
BA_ "GenMsgILSupport" BO_ 687 1;
BA_ "GenMsgSendType" BO_ 687 0;
BA_ "VFrameFormat" BO_ 687 14;
BA_ "GenMsgChkConstant" BO_ 1482 67;
BA_ "GenMsgCycleTime" BO_ 1482 500;
BA_ "GenMsgDelayTime" BO_ 1482 50;
BA_ "GenMsgILSupport" BO_ 1482 1;
BA_ "GenMsgPDUConstants" BO_ 1482 "0x43,0x43,0x43,0x43,0x43,0x43,0x43,0x43,0x43,0x43,0x43,0x43,0x43,0x43,0x43,0x43";
BA_ "GenMsgSendType" BO_ 1482 0;
BA_ "VFrameFormat" BO_ 1482 14;
BA_ "GenMsgChkConstant" BO_ 903 222;
BA_ "GenMsgCycleTime" BO_ 903 100;
BA_ "GenMsgILSupport" BO_ 903 1;
BA_ "GenMsgPDUConstants" BO_ 903 "0xde,0xde,0xde,0xde,0xde,0xde,0xde,0xde,0xde,0xde,0xde,0xde,0xde,0xde,0xde,0xde";
BA_ "GenMsgSendType" BO_ 903 0;
BA_ "VFrameFormat" BO_ 903 14;
BA_ "GenMsgCycleTime" BO_ 902 1000;
BA_ "GenMsgDelayTime" BO_ 902 50;
BA_ "GenMsgILSupport" BO_ 902 1;
BA_ "GenMsgSendType" BO_ 902 0;
BA_ "VFrameFormat" BO_ 902 14;
BA_ "GenMsgCycleTime" BO_ 918 100;
BA_ "GenMsgILSupport" BO_ 918 1;
BA_ "GenMsgSendType" BO_ 918 0;
BA_ "VFrameFormat" BO_ 918 14;
BA_ "GenMsgCycleTime" BO_ 2463978758 100;
BA_ "GenMsgILSupport" BO_ 2463978758 1;
BA_ "GenMsgSendType" BO_ 2463978758 0;
BA_ "VFrameFormat" BO_ 2463978758 15;
BA_ "GenMsgCycleTime" BO_ 1012 50;
BA_ "GenMsgILSupport" BO_ 1012 1;
BA_ "GenMsgPDUConstants" BO_ 1012 "0x26,0xe4,0xc5,0x16,0xcf,0x20,0x65,0xad,0xed,0x6a,0xa3,0x49,0x02,0x6b,0xb2,0xbd";
BA_ "GenMsgSendType" BO_ 1012 0;
BA_ "VFrameFormat" BO_ 1012 14;
BA_ "MsgType" BO_ 2617039369 6;
BA_ "VFrameFormat" BO_ 2617039369 15;
BA_ "MsgType" BO_ 2617039370 6;
BA_ "VFrameFormat" BO_ 2617039370 15;
BA_ "MsgType" BO_ 2617039361 6;
BA_ "VFrameFormat" BO_ 2617039361 15;
BA_ "MsgType" BO_ 2617039362 6;
BA_ "VFrameFormat" BO_ 2617039362 15;
BA_ "MsgType" BO_ 2591834880 6;
BA_ "VFrameFormat" BO_ 2591834880 15;
BA_ "MsgType" BO_ 2617219613 6;
BA_ "VFrameFormat" BO_ 2617219613 15;
BA_ "MsgType" BO_ 2617219612 6;
BA_ "VFrameFormat" BO_ 2617219612 15;
BA_ "MsgType" BO_ 2617219597 6;
BA_ "VFrameFormat" BO_ 2617219597 15;
BA_ "MsgType" BO_ 2617219584 6;
BA_ "VFrameFormat" BO_ 2617219584 15;
BA_ "MsgType" BO_ 2617219621 6;
BA_ "VFrameFormat" BO_ 2617219621 15;
BA_ "MsgType" BO_ 2617219604 6;
BA_ "VFrameFormat" BO_ 2617219604 15;
BA_ "MsgType" BO_ 2617219605 6;
BA_ "VFrameFormat" BO_ 2617219605 15;
BA_ "DiagRequest" BO_ 2549880334 1;
BA_ "MsgType" BO_ 2549880334 4;
BA_ "VFrameFormat" BO_ 2549880334 15;
BA_ "DiagResponse" BO_ 2550011406 1;
BA_ "MsgType" BO_ 2550011406 4;
BA_ "VFrameFormat" BO_ 2550011406 15;
BA_ "GenMsgCycleTime" BO_ 1714 1000;
BA_ "GenMsgILSupport" BO_ 1714 1;
BA_ "GenMsgSendType" BO_ 1714 0;
BA_ "VFrameFormat" BO_ 1714 14;
BA_ "GenSigSendType" SG_ 2536721664 BAP_FAS_Profiles_ASG_01_Header 3;
BA_ "GenSigSwitchedByIgnition" SG_ 2536721664 BAP_FAS_Profiles_ASG_01_Header 0;
BA_ "GenSigSendType" SG_ 2536721680 BAP_FAS_Profiles_FSG_01_Header 3;
BA_ "GenSigSwitchedByIgnition" SG_ 2536721680 BAP_FAS_Profiles_FSG_01_Header 0;
BA_ "GenSigSendType" SG_ 2536707072 BAP_Homelink_ASG_01_Header 3;
BA_ "GenSigSwitchedByIgnition" SG_ 2536707072 BAP_Homelink_ASG_01_Header 0;
BA_ "GenSigSendType" SG_ 2536707088 BAP_Homelink_FSG_01_Header 3;
BA_ "GenSigSwitchedByIgnition" SG_ 2536707088 BAP_Homelink_FSG_01_Header 0;
BA_ "GenSigSendType" SG_ 2536722944 BAP_IAA_PSO_ASG_01_Header 3;
BA_ "GenSigSwitchedByIgnition" SG_ 2536722944 BAP_IAA_PSO_ASG_01_Header 0;
BA_ "GenSigSendType" SG_ 2536722960 BAP_IAA_PSO_FSG_01_Header 3;
BA_ "GenSigSwitchedByIgnition" SG_ 2536722960 BAP_IAA_PSO_FSG_01_Header 0;
BA_ "GenSigSendType" SG_ 2536722434 BAP_InfoSettings_ASG_03_Header 3;
BA_ "GenSigSwitchedByIgnition" SG_ 2536722434 BAP_InfoSettings_ASG_03_Header 0;
BA_ "GenSigSendType" SG_ 2536722448 BAP_InfoSettings_FSG_01_Header 3;
BA_ "GenSigSwitchedByIgnition" SG_ 2536722448 BAP_InfoSettings_FSG_01_Header 0;
BA_ "GenSigSendType" SG_ 2536729088 BAP_Innenlicht2_ASG_01_Header 3;
BA_ "GenSigSwitchedByIgnition" SG_ 2536729088 BAP_Innenlicht2_ASG_01_Header 0;
BA_ "GenSigSendType" SG_ 2536729104 BAP_Innenlicht2_FSG_01_Header 3;
BA_ "GenSigSwitchedByIgnition" SG_ 2536729104 BAP_Innenlicht2_FSG_01_Header 0;
BA_ "GenSigSendType" SG_ 2536704000 BAP_Innenlicht_ASG_01_Header 3;
BA_ "GenSigSwitchedByIgnition" SG_ 2536704000 BAP_Innenlicht_ASG_01_Header 0;
BA_ "GenSigSendType" SG_ 2536704016 BAP_Innenlicht_FSG_01_Header 3;
BA_ "GenSigSwitchedByIgnition" SG_ 2536704016 BAP_Innenlicht_FSG_01_Header 0;
BA_ "GenSigSendType" SG_ 2536702208 BAP_Klima1_ASG_01_Header 3;
BA_ "GenSigSwitchedByIgnition" SG_ 2536702208 BAP_Klima1_ASG_01_Header 0;
BA_ "GenSigSendType" SG_ 2536702224 BAP_Klima1_FSG_01_Header 3;
BA_ "GenSigSwitchedByIgnition" SG_ 2536702224 BAP_Klima1_FSG_01_Header 0;
BA_ "GenSigSendType" SG_ 2536702464 BAP_Klima2_ASG_01_Header 3;
BA_ "GenSigSwitchedByIgnition" SG_ 2536702464 BAP_Klima2_ASG_01_Header 0;
BA_ "GenSigSendType" SG_ 2536702480 BAP_Klima2_FSG_01_Header 3;
BA_ "GenSigSwitchedByIgnition" SG_ 2536702480 BAP_Klima2_FSG_01_Header 0;
BA_ "GenSigSendType" SG_ 2536718848 BAP_KlimaMaster_ASG_01_Header 3;
BA_ "GenSigSwitchedByIgnition" SG_ 2536718848 BAP_KlimaMaster_ASG_01_Header 0;
BA_ "GenSigSendType" SG_ 2536718864 BAP_KlimaMaster_FSG_01_Header 3;
BA_ "GenSigSwitchedByIgnition" SG_ 2536718864 BAP_KlimaMaster_FSG_01_Header 0;
BA_ "GenSigSendType" SG_ 2536708352 BAP_LDW_ASG_01_Header 3;
BA_ "GenSigSwitchedByIgnition" SG_ 2536708352 BAP_LDW_ASG_01_Header 0;
BA_ "GenSigSendType" SG_ 2536708353 BAP_LDW_ASG_02_Header 3;
BA_ "GenSigSwitchedByIgnition" SG_ 2536708353 BAP_LDW_ASG_02_Header 0;
BA_ "GenSigSendType" SG_ 2536708368 BAP_LDW_FSG_01_Header 3;
BA_ "GenSigSwitchedByIgnition" SG_ 2536708368 BAP_LDW_FSG_01_Header 0;
BA_ "GenSigSendType" SG_ 2536715264 BAP_MFL_ASG_01_Header 3;
BA_ "GenSigSwitchedByIgnition" SG_ 2536715264 BAP_MFL_ASG_01_Header 0;
BA_ "GenSigSendType" SG_ 2536715280 BAP_MFL_FSG_01_Header 3;
BA_ "GenSigSwitchedByIgnition" SG_ 2536715280 BAP_MFL_FSG_01_Header 0;
BA_ "GenSigSendType" SG_ 2536705536 BAP_Mirror_ASG_01_Header 3;
BA_ "GenSigSwitchedByIgnition" SG_ 2536705536 BAP_Mirror_ASG_01_Header 0;
BA_ "GenSigSendType" SG_ 2536705552 BAP_Mirror_FSG_01_Header 3;
BA_ "GenSigSwitchedByIgnition" SG_ 2536705552 BAP_Mirror_FSG_01_Header 0;
BA_ "GenSigSendType" SG_ 2536710656 BAP_MKE_ASG_01_Header 3;
BA_ "GenSigSwitchedByIgnition" SG_ 2536710656 BAP_MKE_ASG_01_Header 0;
BA_ "GenSigSendType" SG_ 2536710672 BAP_MKE_FSG_01_Header 3;
BA_ "GenSigSwitchedByIgnition" SG_ 2536710672 BAP_MKE_FSG_01_Header 0;
BA_ "GenSigSendType" SG_ 2536732416 BAP_MobDevKey_ASG_01_Header 3;
BA_ "GenSigSwitchedByIgnition" SG_ 2536732416 BAP_MobDevKey_ASG_01_Header 0;
BA_ "GenSigSendType" SG_ 2536732432 BAP_MobDevKey_FSG_01_Header 3;
BA_ "GenSigSwitchedByIgnition" SG_ 2536732432 BAP_MobDevKey_FSG_01_Header 0;
BA_ "GenSigSendType" SG_ 2536714752 BAP_Navigation_ASG_01_Header 3;
BA_ "GenSigSwitchedByIgnition" SG_ 2536714752 BAP_Navigation_ASG_01_Header 0;
BA_ "GenSigSendType" SG_ 2536714753 BAP_Navigation_ASG_02_Header 3;
BA_ "GenSigSwitchedByIgnition" SG_ 2536714753 BAP_Navigation_ASG_02_Header 0;
BA_ "GenSigSendType" SG_ 2536714768 BAP_Navigation_FSG_01_Header 3;
BA_ "GenSigSwitchedByIgnition" SG_ 2536714768 BAP_Navigation_FSG_01_Header 0;
BA_ "GenSigSendType" SG_ 2536714769 BAP_Navigation_FSG_02_Header 3;
BA_ "GenSigSwitchedByIgnition" SG_ 2536714769 BAP_Navigation_FSG_02_Header 0;
BA_ "GenSigSendType" SG_ 2536712704 BAP_OnlineFunction_ASG_01_Header 3;
BA_ "GenSigSwitchedByIgnition" SG_ 2536712704 BAP_OnlineFunction_ASG_01_Header 0;
BA_ "GenSigSendType" SG_ 2536712720 BAP_OnlineFunction_FSG_01_Header 3;
BA_ "GenSigSwitchedByIgnition" SG_ 2536712720 BAP_OnlineFunction_FSG_01_Header 0;
BA_ "GenSigSendType" SG_ 2536704512 BAP_OPS_ASG_01_Header 3;
BA_ "GenSigSwitchedByIgnition" SG_ 2536704512 BAP_OPS_ASG_01_Header 0;
BA_ "GenSigSendType" SG_ 2536704528 BAP_OPS_FSG_01_Header 3;
BA_ "GenSigSwitchedByIgnition" SG_ 2536704528 BAP_OPS_FSG_01_Header 0;
BA_ "GenSigSendType" SG_ 2536704529 BAP_OPS_FSG_02_Header 3;
BA_ "GenSigSwitchedByIgnition" SG_ 2536704529 BAP_OPS_FSG_02_Header 0;
BA_ "GenSigSendType" SG_ 2536723712 BAP_PaCo_ASG_01_Header 3;
BA_ "GenSigSwitchedByIgnition" SG_ 2536723712 BAP_PaCo_ASG_01_Header 0;
BA_ "GenSigSendType" SG_ 2536723713 BAP_PaCo_ASG_02_Header 3;
BA_ "GenSigSwitchedByIgnition" SG_ 2536723713 BAP_PaCo_ASG_02_Header 0;
BA_ "GenSigSendType" SG_ 2536723728 BAP_PaCo_FSG_01_Header 3;
BA_ "GenSigSwitchedByIgnition" SG_ 2536723728 BAP_PaCo_FSG_01_Header 0;
BA_ "GenSigSendType" SG_ 2536702720 BAP_ParkHeater_ASG_01_Header 3;
BA_ "GenSigSwitchedByIgnition" SG_ 2536702720 BAP_ParkHeater_ASG_01_Header 0;
BA_ "GenSigSendType" SG_ 2536702736 BAP_ParkHeater_FSG_01_Header 3;
BA_ "GenSigSwitchedByIgnition" SG_ 2536702736 BAP_ParkHeater_FSG_01_Header 0;
BA_ "GenSigSendType" SG_ 2536703744 BAP_RDK_ASG_01_Header 3;
BA_ "GenSigSwitchedByIgnition" SG_ 2536703744 BAP_RDK_ASG_01_Header 0;
BA_ "GenSigSendType" SG_ 2536703745 BAP_RDK_ASG_02_Header 3;
BA_ "GenSigSwitchedByIgnition" SG_ 2536703745 BAP_RDK_ASG_02_Header 0;
BA_ "GenSigSendType" SG_ 2536703747 BAP_RDK_ASG_04_Header 3;
BA_ "GenSigSwitchedByIgnition" SG_ 2536703747 BAP_RDK_ASG_04_Header 0;
BA_ "GenSigSendType" SG_ 2536703760 BAP_RDK_FSG_01_Header 3;
BA_ "GenSigSwitchedByIgnition" SG_ 2536703760 BAP_RDK_FSG_01_Header 0;
BA_ "GenSigSendType" SG_ 2536721921 BAP_RemoteServices_ASG_02_Header 3;
BA_ "GenSigSwitchedByIgnition" SG_ 2536721921 BAP_RemoteServices_ASG_02_Header 0;
BA_ "GenSigSendType" SG_ 2536721936 BAP_RemoteServices_FSG_01_Header 3;
BA_ "GenSigSwitchedByIgnition" SG_ 2536721936 BAP_RemoteServices_FSG_01_Header 0;
BA_ "GenSigSendType" SG_ 2536704768 BAP_RVC_ASG_01_Header 3;
BA_ "GenSigSwitchedByIgnition" SG_ 2536704768 BAP_RVC_ASG_01_Header 0;
BA_ "GenSigSendType" SG_ 2536704784 BAP_RVC_FSG_01_Header 3;
BA_ "GenSigSwitchedByIgnition" SG_ 2536704784 BAP_RVC_FSG_01_Header 0;
BA_ "GenSigSendType" SG_ 2536717056 BAP_SeatPneumatic_ASG_01_Header 3;
BA_ "GenSigSwitchedByIgnition" SG_ 2536717056 BAP_SeatPneumatic_ASG_01_Header 0;
BA_ "GenSigSendType" SG_ 2536717072 BAP_SeatPneumatic_FSG_01_Header 3;
BA_ "GenSigSwitchedByIgnition" SG_ 2536717072 BAP_SeatPneumatic_FSG_01_Header 0;
BA_ "GenSigSendType" SG_ 2536706560 BAP_SIA_ASG_01_Header 3;
BA_ "GenSigSwitchedByIgnition" SG_ 2536706560 BAP_SIA_ASG_01_Header 0;
BA_ "GenSigSendType" SG_ 2536706576 BAP_SIA_FSG_01_Header 3;
BA_ "GenSigSwitchedByIgnition" SG_ 2536706576 BAP_SIA_FSG_01_Header 0;
BA_ "GenSigSendType" SG_ 2536706048 BAP_Sitz1_ASG_01_Header 3;
BA_ "GenSigSwitchedByIgnition" SG_ 2536706048 BAP_Sitz1_ASG_01_Header 0;
BA_ "GenSigSendType" SG_ 2536706064 BAP_Sitz1_FSG_01_Header 3;
BA_ "GenSigSwitchedByIgnition" SG_ 2536706064 BAP_Sitz1_FSG_01_Header 0;
BA_ "GenSigSendType" SG_ 2536710144 BAP_Sitz2_ASG_01_Header 3;
BA_ "GenSigSwitchedByIgnition" SG_ 2536710144 BAP_Sitz2_ASG_01_Header 0;
BA_ "GenSigSendType" SG_ 2536710160 BAP_Sitz2_FSG_01_Header 3;
BA_ "GenSigSwitchedByIgnition" SG_ 2536710160 BAP_Sitz2_FSG_01_Header 0;
BA_ "GenSigSendType" SG_ 2536721152 BAP_Sunroof_ASG_01_Header 3;
BA_ "GenSigSwitchedByIgnition" SG_ 2536721152 BAP_Sunroof_ASG_01_Header 0;
BA_ "GenSigSendType" SG_ 2536721168 BAP_Sunroof_FSG_01_Header 3;
BA_ "GenSigSwitchedByIgnition" SG_ 2536721168 BAP_Sunroof_FSG_01_Header 0;
BA_ "GenSigSendType" SG_ 2536708608 BAP_SWA_ASG_01_Header 3;
BA_ "GenSigSwitchedByIgnition" SG_ 2536708608 BAP_SWA_ASG_01_Header 0;
BA_ "GenSigSendType" SG_ 2536708624 BAP_SWA_FSG_01_Header 3;
BA_ "GenSigSendType" SG_ 2536712448 BAP_Telefon2_ASG_01_Header 3;
BA_ "GenSigSwitchedByIgnition" SG_ 2536712448 BAP_Telefon2_ASG_01_Header 0;
BA_ "GenSigSendType" SG_ 2536712464 BAP_Telefon2_FSG_01_Header 3;
BA_ "GenSigSwitchedByIgnition" SG_ 2536712464 BAP_Telefon2_FSG_01_Header 0;
BA_ "GenSigSendType" SG_ 2536712465 BAP_Telefon2_FSG_02_Header 3;
BA_ "GenSigSwitchedByIgnition" SG_ 2536712465 BAP_Telefon2_FSG_02_Header 0;
BA_ "GenSigSendType" SG_ 2536712192 BAP_Telefon_ASG_01_Header 3;
BA_ "GenSigSwitchedByIgnition" SG_ 2536712192 BAP_Telefon_ASG_01_Header 0;
BA_ "GenSigSendType" SG_ 2536712193 BAP_Telefon_ASG_02_Header 3;
BA_ "GenSigSwitchedByIgnition" SG_ 2536712193 BAP_Telefon_ASG_02_Header 0;
BA_ "GenSigSendType" SG_ 2536712208 BAP_Telefon_FSG_01_Header 3;
BA_ "GenSigSwitchedByIgnition" SG_ 2536712208 BAP_Telefon_FSG_01_Header 0;
BA_ "GenSigSendType" SG_ 2536712209 BAP_Telefon_FSG_02_Header 3;
BA_ "GenSigSwitchedByIgnition" SG_ 2536712209 BAP_Telefon_FSG_02_Header 0;
BA_ "GenSigSendType" SG_ 2536728576 BAP_THA_ASG_01_Header 3;
BA_ "GenSigSwitchedByIgnition" SG_ 2536728576 BAP_THA_ASG_01_Header 0;
BA_ "GenSigSendType" SG_ 2536728592 BAP_THA_FSG_01_Header 3;
BA_ "GenSigSwitchedByIgnition" SG_ 2536728592 BAP_THA_FSG_01_Header 0;
BA_ "GenSigSendType" SG_ 2536726273 BAP_TPA_ASG_02_Header 3;
BA_ "GenSigSwitchedByIgnition" SG_ 2536726273 BAP_TPA_ASG_02_Header 0;
BA_ "GenSigSendType" SG_ 2536726288 BAP_TPA_FSG_01_Header 3;
BA_ "GenSigSwitchedByIgnition" SG_ 2536726288 BAP_TPA_FSG_01_Header 0;
BA_ "GenSigSendType" SG_ 2536715776 BAP_TrailerAssist_ASG_01_Header 3;
BA_ "GenSigSwitchedByIgnition" SG_ 2536715776 BAP_TrailerAssist_ASG_01_Header 0;
BA_ "GenSigSendType" SG_ 2536715792 BAP_TrailerAssist_FSG_01_Header 3;
BA_ "GenSigSendType" SG_ 2536710400 BAP_VZA_ASG_01_Header 3;
BA_ "GenSigSwitchedByIgnition" SG_ 2536710400 BAP_VZA_ASG_01_Header 0;
BA_ "GenSigSendType" SG_ 2536710401 BAP_VZA_ASG_02_Header 3;
BA_ "GenSigSwitchedByIgnition" SG_ 2536710401 BAP_VZA_ASG_02_Header 0;
BA_ "GenSigSendType" SG_ 2536710402 BAP_VZA_ASG_03_Header 3;
BA_ "GenSigSwitchedByIgnition" SG_ 2536710402 BAP_VZA_ASG_03_Header 0;
BA_ "GenSigSendType" SG_ 2536710416 BAP_VZA_FSG_01_Header 3;
BA_ "GenSigSwitchedByIgnition" SG_ 2536710416 BAP_VZA_FSG_01_Header 0;
BA_ "GenSigSendType" SG_ 2536705024 BAP_Wiper_ASG_01_Header 3;
BA_ "GenSigSwitchedByIgnition" SG_ 2536705024 BAP_Wiper_ASG_01_Header 0;
BA_ "GenSigSendType" SG_ 2536705040 BAP_Wiper_FSG_01_Header 3;
BA_ "GenSigSwitchedByIgnition" SG_ 2536705040 BAP_Wiper_FSG_01_Header 0;
BA_ "GenSigSendType" SG_ 1626 APS_Tongeber_defekt 3;
BA_ "GenSigSwitchedByIgnition" SG_ 1626 APS_Tongeber_defekt 0;
BA_ "GenSigSendType" SG_ 1626 BCM1_AFS_Lampe 3;
BA_ "GenSigSwitchedByIgnition" SG_ 1626 BCM1_AFS_Lampe 0;
BA_ "GenSigSendType" SG_ 1626 BCM1_EasyEntry_Status 3;
BA_ "GenSigSwitchedByIgnition" SG_ 1626 BCM1_EasyEntry_Status 0;
BA_ "GenSigSendType" SG_ 1626 BCM1_Kl_15_HW_erkannt 3;
BA_ "GenSigSwitchedByIgnition" SG_ 1626 BCM1_Kl_15_HW_erkannt 0;
BA_ "GenSigSendType" SG_ 1626 BCM1_Kl_15_Sig_HW_erkannt 3;
BA_ "GenSigSwitchedByIgnition" SG_ 1626 BCM1_Kl_15_Sig_HW_erkannt 0;
BA_ "GenSigSendType" SG_ 1626 BCM1_Lenksaeule_aktiv 3;
BA_ "GenSigSwitchedByIgnition" SG_ 1626 BCM1_Lenksaeule_aktiv 0;
BA_ "GenSigSendType" SG_ 1626 BCM1_MH_Schalter 3;
BA_ "GenSigSwitchedByIgnition" SG_ 1626 BCM1_MH_Schalter 0;
BA_ "GenSigSendType" SG_ 1626 BCM1_MH_WIV_Schalter 3;
BA_ "GenSigSwitchedByIgnition" SG_ 1626 BCM1_MH_WIV_Schalter 0;
BA_ "GenSigSendType" SG_ 1626 BCM1_NV_Taster 0;
BA_ "GenSigSwitchedByIgnition" SG_ 1626 BCM1_NV_Taster 0;
BA_ "GenSigSendType" SG_ 1626 BCM1_Reisemodus_Texte 3;
BA_ "GenSigSwitchedByIgnition" SG_ 1626 BCM1_Reisemodus_Texte 0;
BA_ "GenSigSendType" SG_ 1626 BCM1_Rueckfahrlicht_Schalter 3;
BA_ "GenSigSwitchedByIgnition" SG_ 1626 BCM1_Rueckfahrlicht_Schalter 0;
BA_ "GenSigSendType" SG_ 1626 BCM1_Spannungs_Anf 3;
BA_ "GenSigSwitchedByIgnition" SG_ 1626 BCM1_Spannungs_Anf 0;
BA_ "GenSigSendType" SG_ 1626 BCM1_Valet_Parking_Taster 0;
BA_ "GenSigSwitchedByIgnition" SG_ 1626 BCM1_Valet_Parking_Taster 0;
BA_ "GenSigSendType" SG_ 1626 BCM1_Warnblink_Taster 3;
BA_ "GenSigSwitchedByIgnition" SG_ 1626 BCM1_Warnblink_Taster 0;
BA_ "GenSigSendType" SG_ 1626 BCM_Anf_AAW_MoLaWa 3;
BA_ "GenSigSwitchedByIgnition" SG_ 1626 BCM_Anf_AAW_MoLaWa 0;
BA_ "GenSigSendType" SG_ 1626 BCM_Bremsbelag_Sensor 3;
BA_ "GenSigSwitchedByIgnition" SG_ 1626 BCM_Bremsbelag_Sensor 0;
BA_ "GenSigSendType" SG_ 1626 BCM_Bremsfluessigkeit_Sensor 3;
BA_ "GenSigSwitchedByIgnition" SG_ 1626 BCM_Bremsfluessigkeit_Sensor 0;
BA_ "GenSigSendType" SG_ 1626 BCM_Charisma_Taste2 3;
BA_ "GenSigSwitchedByIgnition" SG_ 1626 BCM_Charisma_Taste2 0;
BA_ "GenSigSendType" SG_ 1626 BCM_Eco_Charisma_Taste 3;
BA_ "GenSigSwitchedByIgnition" SG_ 1626 BCM_Eco_Charisma_Taste 0;
BA_ "GenSigSendType" SG_ 1626 BCM_Handbremse_Hinweis 4;
BA_ "GenSigSwitchedByIgnition" SG_ 1626 BCM_Handbremse_Hinweis 0;
BA_ "GenSigSendType" SG_ 1626 BCM_HDF_betaetigt 4;
BA_ "GenSigSwitchedByIgnition" SG_ 1626 BCM_HDF_betaetigt 0;
BA_ "GenSigSendType" SG_ 1626 BCM_Hybrid_StartStopp_Taste 3;
BA_ "GenSigSwitchedByIgnition" SG_ 1626 BCM_Hybrid_StartStopp_Taste 0;
BA_ "GenSigSendType" SG_ 1626 BCM_Hybrid_StSt_Taste_Fehler 3;
BA_ "GenSigSwitchedByIgnition" SG_ 1626 BCM_Hybrid_StSt_Taste_Fehler 0;
BA_ "GenSigSendType" SG_ 1626 BCM_Kuehlmittel_Sensor 3;
BA_ "GenSigSwitchedByIgnition" SG_ 1626 BCM_Kuehlmittel_Sensor 0;
BA_ "GenSigSendType" SG_ 1626 BCM_Kuehlmittel_Sensor_02 3;
BA_ "GenSigSwitchedByIgnition" SG_ 1626 BCM_Kuehlmittel_Sensor_02 0;
BA_ "GenSigSendType" SG_ 1626 BCM_Offroad_Taste 3;
BA_ "GenSigSwitchedByIgnition" SG_ 1626 BCM_Offroad_Taste 0;
BA_ "GenSigSendType" SG_ 1626 BCM_ValetTaster_Fkts_LED 4;
BA_ "GenSigSwitchedByIgnition" SG_ 1626 BCM_ValetTaster_Fkts_LED 0;
BA_ "GenSigSendType" SG_ 1626 BCM_Waschwasser_Sensor 3;
BA_ "GenSigSwitchedByIgnition" SG_ 1626 BCM_Waschwasser_Sensor 0;
BA_ "GenSigSendType" SG_ 1626 Gong_TFL_Umschaltung 3;
BA_ "GenSigSwitchedByIgnition" SG_ 1626 Gong_TFL_Umschaltung 0;
BA_ "GenSigSendType" SG_ 1626 LRH_Taster 3;
BA_ "GenSigSwitchedByIgnition" SG_ 1626 LRH_Taster 0;
BA_ "GenSigSendType" SG_ 2527679637 BCM_anf_VLW 3;
BA_ "GenSigSwitchedByIgnition" SG_ 2527679637 BCM_anf_VLW 0;
BA_ "GenSigSendType" SG_ 2527679637 BCM_LTM_Allwetterl_Status 3;
BA_ "GenSigSwitchedByIgnition" SG_ 2527679637 BCM_LTM_Allwetterl_Status 0;
BA_ "GenSigSendType" SG_ 2527679637 BCM_LTM_Nebell_Status 3;
BA_ "GenSigSwitchedByIgnition" SG_ 2527679637 BCM_LTM_Nebell_Status 0;
BA_ "GenSigSendType" SG_ 2527679637 BCM_LTM_Nebelschluss_Status 3;
BA_ "GenSigSwitchedByIgnition" SG_ 2527679637 BCM_LTM_Nebelschluss_Status 0;
BA_ "GenSigSendType" SG_ 2527679637 BCM_LTM_PopUp_Anf 3;
BA_ "GenSigSwitchedByIgnition" SG_ 2527679637 BCM_LTM_PopUp_Anf 0;
BA_ "GenSigSendType" SG_ 2527679637 BCM_LTM_PopUp_Inhalt 3;
BA_ "GenSigSwitchedByIgnition" SG_ 2527679637 BCM_LTM_PopUp_Inhalt 0;
BA_ "GenSigSendType" SG_ 2527679637 BCM_LTM_PopUp_Status 3;
BA_ "GenSigSwitchedByIgnition" SG_ 2527679637 BCM_LTM_PopUp_Status 0;
BA_ "GenSigSendType" SG_ 2527679637 BCM_LTM_PopUp_Texte 3;
BA_ "GenSigSwitchedByIgnition" SG_ 2527679637 BCM_LTM_PopUp_Texte 0;
BA_ "GenSigSendType" SG_ 2527679637 CPD_Warnung 3;
BA_ "GenSigSwitchedByIgnition" SG_ 2527679637 CPD_Warnung 0;
BA_ "GenSigSendType" SG_ 2463978607 BCM_RGB_Blau 3;
BA_ "GenSigSwitchedByIgnition" SG_ 2463978607 BCM_RGB_Blau 0;
BA_ "GenSigSendType" SG_ 2463978607 BCM_RGB_Dimmrampe 0;
BA_ "GenSigSwitchedByIgnition" SG_ 2463978607 BCM_RGB_Dimmrampe 0;
BA_ "GenSigSendType" SG_ 2463978607 BCM_RGB_Dimmzeit_Zeitbasis 0;
BA_ "GenSigSwitchedByIgnition" SG_ 2463978607 BCM_RGB_Dimmzeit_Zeitbasis 0;
BA_ "GenSigSendType" SG_ 2463978607 BCM_RGB_Gruen 3;
BA_ "GenSigSwitchedByIgnition" SG_ 2463978607 BCM_RGB_Gruen 0;
BA_ "Fehlerwert" SG_ 2463978607 BCM_RGB_Intensitaet 127;
BA_ "GenSigSendType" SG_ 2463978607 BCM_RGB_Intensitaet 0;
BA_ "GenSigStartValue" SG_ 2463978607 BCM_RGB_Intensitaet 126;
BA_ "GenSigSwitchedByIgnition" SG_ 2463978607 BCM_RGB_Intensitaet 0;
BA_ "GenSigSendType" SG_ 2463978607 BCM_RGB_Normierung_Intensitaet 0;
BA_ "GenSigSwitchedByIgnition" SG_ 2463978607 BCM_RGB_Normierung_Intensitaet 0;
BA_ "GenSigSendType" SG_ 2463978607 BCM_RGB_Rot 3;
BA_ "GenSigSwitchedByIgnition" SG_ 2463978607 BCM_RGB_Rot 0;
BA_ "GenSigSendType" SG_ 1432 BCM_BFS_Massage_Taster 3;
BA_ "GenSigSwitchedByIgnition" SG_ 1432 BCM_BFS_Massage_Taster 0;
BA_ "GenSigSendType" SG_ 1432 BCM_BFS_Multif_Taster 3;
BA_ "GenSigSwitchedByIgnition" SG_ 1432 BCM_BFS_Multif_Taster 0;
BA_ "GenSigSendType" SG_ 1432 BCM_BFS_Pneumatik_Verstellung 3;
BA_ "GenSigSwitchedByIgnition" SG_ 1432 BCM_BFS_Pneumatik_Verstellung 0;
BA_ "GenSigSendType" SG_ 1432 BCM_BFS_Programmwippe 3;
BA_ "GenSigSwitchedByIgnition" SG_ 1432 BCM_BFS_Programmwippe 0;
BA_ "GenSigSendType" SG_ 1432 BCM_FS_Massage_Taster 3;
BA_ "GenSigSwitchedByIgnition" SG_ 1432 BCM_FS_Massage_Taster 0;
BA_ "GenSigSendType" SG_ 1432 BCM_FS_Multif_Taster 3;
BA_ "GenSigSwitchedByIgnition" SG_ 1432 BCM_FS_Multif_Taster 0;
BA_ "GenSigSendType" SG_ 1432 BCM_FS_Pneumatik_Verstellung 3;
BA_ "GenSigSwitchedByIgnition" SG_ 1432 BCM_FS_Pneumatik_Verstellung 0;
BA_ "GenSigSendType" SG_ 1432 BCM_FS_Programmwippe 3;
BA_ "GenSigSwitchedByIgnition" SG_ 1432 BCM_FS_Programmwippe 0;
BA_ "Fehlerwert" SG_ 1432 FAS_Profile_Taster 3;
BA_ "GenSigSendType" SG_ 1432 FAS_Profile_Taster 4;
BA_ "GenSigStartValue" SG_ 1432 FAS_Profile_Taster 2;
BA_ "GenSigSwitchedByIgnition" SG_ 1432 FAS_Profile_Taster 0;
BA_ "GenSigSendType" SG_ 1432 LIM_bCall_Taster 4;
BA_ "GenSigSwitchedByIgnition" SG_ 1432 LIM_bCall_Taster 0;
BA_ "GenSigSendType" SG_ 1432 LIM_iCall_Taster 4;
BA_ "GenSigSwitchedByIgnition" SG_ 1432 LIM_iCall_Taster 0;
BA_ "GenSigActiveRepetitions" SG_ 1432 LIM_S_Rollo_hi 5;
BA_ "GenSigSendType" SG_ 1432 LIM_S_Rollo_hi 4;
BA_ "GenSigSwitchedByIgnition" SG_ 1432 LIM_S_Rollo_hi 0;
BA_ "GenSigActiveRepetitions" SG_ 1432 LIM_S_Rollo_vo 5;
BA_ "GenSigSendType" SG_ 1432 LIM_S_Rollo_vo 4;
BA_ "GenSigSwitchedByIgnition" SG_ 1432 LIM_S_Rollo_vo 0;
BA_ "GenSigActiveRepetitions" SG_ 1432 LIM_S_SAD_hi 5;
BA_ "GenSigSendType" SG_ 1432 LIM_S_SAD_hi 4;
BA_ "GenSigSwitchedByIgnition" SG_ 1432 LIM_S_SAD_hi 0;
BA_ "GenSigActiveRepetitions" SG_ 1432 LIM_S_SAD_Vo 5;
BA_ "GenSigSendType" SG_ 1432 LIM_S_SAD_Vo 4;
BA_ "GenSigSwitchedByIgnition" SG_ 1432 LIM_S_SAD_Vo 0;
BA_ "Fehlerwert" SG_ 1432 LINDa_Touch_Event 15;
BA_ "GenSigSendType" SG_ 1432 LINDa_Touch_Event 3;
BA_ "GenSigSwitchedByIgnition" SG_ 1432 LINDa_Touch_Event 0;
BA_ "GenSigSendType" SG_ 1432 Tuerkontakt_Innenlicht_Taste 4;
BA_ "GenSigSwitchedByIgnition" SG_ 1432 Tuerkontakt_Innenlicht_Taste 0;
BA_ "Fehlerwert" SG_ 2527679781 LINDa_HL_SR3_Touch_Event 15;
BA_ "GenSigSendType" SG_ 2527679781 LINDa_HL_SR3_Touch_Event 3;
BA_ "GenSigSwitchedByIgnition" SG_ 2527679781 LINDa_HL_SR3_Touch_Event 0;
BA_ "Fehlerwert" SG_ 2527679781 LINDa_HL_Touch_Event 15;
BA_ "GenSigSendType" SG_ 2527679781 LINDa_HL_Touch_Event 3;
BA_ "GenSigSwitchedByIgnition" SG_ 2527679781 LINDa_HL_Touch_Event 0;
BA_ "Fehlerwert" SG_ 2527679781 LINDa_HR_SR3_Touch_Event 15;
BA_ "GenSigSendType" SG_ 2527679781 LINDa_HR_SR3_Touch_Event 3;
BA_ "GenSigSwitchedByIgnition" SG_ 2527679781 LINDa_HR_SR3_Touch_Event 0;
BA_ "Fehlerwert" SG_ 2527679781 LINDa_HR_Touch_Event 15;
BA_ "GenSigSendType" SG_ 2527679781 LINDa_HR_Touch_Event 3;
BA_ "GenSigSwitchedByIgnition" SG_ 2527679781 LINDa_HR_Touch_Event 0;
BA_ "GenSigSendType" SG_ 1635 BEM_Anf_KL15_schalten 0;
BA_ "GenSigSwitchedByIgnition" SG_ 1635 BEM_Anf_KL15_schalten 0;
BA_ "GenSigSendType" SG_ 1635 BEM_Batt_Ab 0;
BA_ "GenSigSwitchedByIgnition" SG_ 1635 BEM_Batt_Ab 0;
BA_ "Fehlerwert" SG_ 1635 BEM_Batteriediagnose 7;
BA_ "GenSigSendType" SG_ 1635 BEM_Batteriediagnose 0;
BA_ "GenSigSwitchedByIgnition" SG_ 1635 BEM_Batteriediagnose 0;
BA_ "GenSigSendType" SG_ 1635 BEM_DFM 0;
BA_ "GenSigSwitchedByIgnition" SG_ 1635 BEM_DFM 0;
BA_ "GenSigSendType" SG_ 1635 BEM_EMLIN_ungueltig 0;
BA_ "GenSigSwitchedByIgnition" SG_ 1635 BEM_EMLIN_ungueltig 0;
BA_ "GenSigSendType" SG_ 1635 BEM_Generatordiagnose 0;
BA_ "GenSigSwitchedByIgnition" SG_ 1635 BEM_Generatordiagnose 0;
BA_ "GenSigSendType" SG_ 1635 BEM_HL_Kontingentierung 0;
BA_ "GenSigSwitchedByIgnition" SG_ 1635 BEM_HL_Kontingentierung 0;
BA_ "GenSigSendType" SG_ 1635 BEM_HL_Regelung_Status 0;
BA_ "GenSigSwitchedByIgnition" SG_ 1635 BEM_HL_Regelung_Status 0;
BA_ "Fehlerwert" SG_ 1635 BEM_Ladezustand 15;
BA_ "GenSigSendType" SG_ 1635 BEM_Ladezustand 0;
BA_ "GenSigStartValue" SG_ 1635 BEM_Ladezustand 14;
BA_ "GenSigSwitchedByIgnition" SG_ 1635 BEM_Ladezustand 0;
BA_ "GenSigSendType" SG_ 1635 BEM_MMI_Vorwarnung 0;
BA_ "GenSigSwitchedByIgnition" SG_ 1635 BEM_MMI_Vorwarnung 0;
BA_ "GenSigSendType" SG_ 1635 BEM_Red_Innengeblaese 0;
BA_ "GenSigSwitchedByIgnition" SG_ 1635 BEM_Red_Innengeblaese 0;
BA_ "GenSigSendType" SG_ 1635 BEM_REK_aktiv 0;
BA_ "GenSigSwitchedByIgnition" SG_ 1635 BEM_REK_aktiv 0;
BA_ "GenSigSendType" SG_ 1635 BEM_STH_Einschaltverbot 0;
BA_ "GenSigSwitchedByIgnition" SG_ 1635 BEM_STH_Einschaltverbot 0;
BA_ "Fehlerwert" SG_ 1635 BEM_STH_Zielzeit 15;
BA_ "GenSigSendType" SG_ 1635 BEM_STH_Zielzeit 0;
BA_ "GenSigStartValue" SG_ 1635 BEM_STH_Zielzeit 14;
BA_ "GenSigSwitchedByIgnition" SG_ 1635 BEM_STH_Zielzeit 0;
BA_ "Fehlerwert" SG_ 1635 BEM_UBDM 255;
BA_ "GenSigSendType" SG_ 1635 BEM_UBDM 0;
BA_ "GenSigSwitchedByIgnition" SG_ 1635 BEM_UBDM 0;
BA_ "GenSigSendType" SG_ 1635 BEM_UGenSoll 0;
BA_ "GenSigSwitchedByIgnition" SG_ 1635 BEM_UGenSoll 0;
BA_ "GenSigSendType" SG_ 1635 MIB_Stromsparmodus 0;
BA_ "GenSigSwitchedByIgnition" SG_ 1635 MIB_Stromsparmodus 0;
BA_ "GenSigSendType" SG_ 1635 NVEM_Abschaltstufe 0;
BA_ "GenSigSwitchedByIgnition" SG_ 1635 NVEM_Abschaltstufe 0;
BA_ "GenSigSendType" SG_ 1635 NVEM_Anf_SD_schalten 0;
BA_ "GenSigSwitchedByIgnition" SG_ 1635 NVEM_Anf_SD_schalten 0;
BA_ "GenSigSendType" SG_ 1635 NVEM_Batterie_Service 0;
BA_ "GenSigSwitchedByIgnition" SG_ 1635 NVEM_Batterie_Service 0;
BA_ "GenSigSendType" SG_ 1635 NVEM_Freigabe_OnlineUpdate 0;
BA_ "GenSigSwitchedByIgnition" SG_ 1635 NVEM_Freigabe_OnlineUpdate 0;
BA_ "GenSigSendType" SG_ 1635 NVEM_Freigabe_ORU4 0;
BA_ "GenSigSwitchedByIgnition" SG_ 1635 NVEM_Freigabe_ORU4 0;
BA_ "GenSigSendType" SG_ 1635 NVEM_Freigabe_ZusBatt_Laden 0;
BA_ "GenSigSwitchedByIgnition" SG_ 1635 NVEM_Freigabe_ZusBatt_Laden 0;
BA_ "GenSigSendType" SG_ 1635 NVEM_Verbraucherabsch_Anz 0;
BA_ "GenSigSwitchedByIgnition" SG_ 1635 NVEM_Verbraucherabsch_Anz 0;
BA_ "GenSigFuncType" SG_ 1163 BEM_06_BZ 1;
BA_ "GenSigSendType" SG_ 1163 BEM_06_BZ 0;
BA_ "GenSigSwitchedByIgnition" SG_ 1163 BEM_06_BZ 0;
BA_ "GenSigFuncType" SG_ 1163 BEM_06_CRC 2;
BA_ "GenSigSendType" SG_ 1163 BEM_06_CRC 0;
BA_ "GenSigSwitchedByIgnition" SG_ 1163 BEM_06_CRC 0;
BA_ "Fehlerwert" SG_ 1163 HLR_PTC_linear_Freigabe 63;
BA_ "GenSigSendType" SG_ 1163 HLR_PTC_linear_Freigabe 0;
BA_ "GenSigSwitchedByIgnition" SG_ 1163 HLR_PTC_linear_Freigabe 0;
BA_ "Fehlerwert" SG_ 1163 NVEM2_Status_FuSiFahrt 7;
BA_ "GenSigSendType" SG_ 1163 NVEM2_Status_FuSiFahrt 0;
BA_ "GenSigSwitchedByIgnition" SG_ 1163 NVEM2_Status_FuSiFahrt 0;
BA_ "Fehlerwert" SG_ 1163 NVEM2_Typ_EnergieNetz 14;
BA_ "GenSigSendType" SG_ 1163 NVEM2_Typ_EnergieNetz 0;
BA_ "GenSigSwitchedByIgnition" SG_ 1163 NVEM2_Typ_EnergieNetz 0;
BA_ "Fehlerwert" SG_ 1163 NVEM_Betriebsart 15;
BA_ "GenSigSendType" SG_ 1163 NVEM_Betriebsart 0;
BA_ "GenSigSwitchedByIgnition" SG_ 1163 NVEM_Betriebsart 0;
BA_ "GenSigSendType" SG_ 1163 NVEM_Bordnetzdiagnose 0;
BA_ "GenSigSwitchedByIgnition" SG_ 1163 NVEM_Bordnetzdiagnose 0;
BA_ "Fehlerwert" SG_ 1163 NVEM_Energie_Klima_Vorgabe 255;
BA_ "GenSigSendType" SG_ 1163 NVEM_Energie_Klima_Vorgabe 0;
BA_ "GenSigStartValue" SG_ 1163 NVEM_Energie_Klima_Vorgabe 254;
BA_ "GenSigSwitchedByIgnition" SG_ 1163 NVEM_Energie_Klima_Vorgabe 0;
BA_ "Fehlerwert" SG_ 1163 NVEM_Energienetz_Status 7;
BA_ "GenSigSendType" SG_ 1163 NVEM_Energienetz_Status 0;
BA_ "GenSigStartValue" SG_ 1163 NVEM_Energienetz_Status 6;
BA_ "GenSigSwitchedByIgnition" SG_ 1163 NVEM_Energienetz_Status 0;
BA_ "Fehlerwert" SG_ 1163 NVEM_Ladezustand 127;
BA_ "GenSigSendType" SG_ 1163 NVEM_Ladezustand 0;
BA_ "GenSigStartValue" SG_ 1163 NVEM_Ladezustand 126;
BA_ "GenSigSwitchedByIgnition" SG_ 1163 NVEM_Ladezustand 0;
BA_ "GenSigSendType" SG_ 1163 NVEM_Last_Anf 0;
BA_ "GenSigSwitchedByIgnition" SG_ 1163 NVEM_Last_Anf 0;
BA_ "GenSigSendType" SG_ 1163 NVEM_PTC_Sollstufe 0;
BA_ "GenSigSwitchedByIgnition" SG_ 1163 NVEM_PTC_Sollstufe 0;
BA_ "Fehlerwert" SG_ 1163 NVEM_Red_KomfortVerbrauch 15;
BA_ "GenSigSendType" SG_ 1163 NVEM_Red_KomfortVerbrauch 0;
BA_ "GenSigSwitchedByIgnition" SG_ 1163 NVEM_Red_KomfortVerbrauch 0;
BA_ "Fehlerwert" SG_ 1163 NVEM_STH_ZielzeitLang 15;
BA_ "GenSigSendType" SG_ 1163 NVEM_STH_ZielzeitLang 0;
BA_ "GenSigStartValue" SG_ 1163 NVEM_STH_ZielzeitLang 14;
BA_ "GenSigSwitchedByIgnition" SG_ 1163 NVEM_STH_ZielzeitLang 0;
BA_ "Fehlerwert" SG_ 1163 NVEM_Vorgabe_Leistungsstufe 7;
BA_ "GenSigSendType" SG_ 1163 NVEM_Vorgabe_Leistungsstufe 0;
BA_ "Fehlerwert" SG_ 2463978850 NVEM2_VerbrZustandsAnf 15;
BA_ "GenSigSendType" SG_ 2463978850 NVEM2_VerbrZustandsAnf 0;
BA_ "GenSigStartValue" SG_ 2463978850 NVEM2_VerbrZustandsAnf 14;
BA_ "GenSigSwitchedByIgnition" SG_ 2463978850 NVEM2_VerbrZustandsAnf 0;
BA_ "Fehlerwert" SG_ 2463978850 NVEM_Bordnetz_Information 15;
BA_ "GenSigSendType" SG_ 2463978850 NVEM_Bordnetz_Information 0;
BA_ "GenSigStartValue" SG_ 2463978850 NVEM_Bordnetz_Information 14;
BA_ "GenSigSwitchedByIgnition" SG_ 2463978850 NVEM_Bordnetz_Information 0;
BA_ "GenSigSendType" SG_ 2463978850 NVEM_EntnehmbareLadung 0;
BA_ "GenSigSwitchedByIgnition" SG_ 2463978850 NVEM_EntnehmbareLadung 0;
BA_ "Fehlerwert" SG_ 2463978850 NVEM_HVEM_FunktionsAnf 255;
BA_ "GenSigSendType" SG_ 2463978850 NVEM_HVEM_FunktionsAnf 0;
BA_ "GenSigSwitchedByIgnition" SG_ 2463978850 NVEM_HVEM_FunktionsAnf 0;
BA_ "Fehlerwert" SG_ 2463978850 NVEM_NVStuetzungAnf 3;
BA_ "GenSigSendType" SG_ 2463978850 NVEM_NVStuetzungAnf 0;
BA_ "GenSigSwitchedByIgnition" SG_ 2463978850 NVEM_NVStuetzungAnf 0;
BA_ "Fehlerwert" SG_ 2463978850 NVEM_Verbraucher_Information 7;
BA_ "GenSigSendType" SG_ 2463978850 NVEM_Verbraucher_Information 0;
BA_ "GenSigStartValue" SG_ 2463978850 NVEM_Verbraucher_Information 6;
BA_ "GenSigSendType" SG_ 870 Blinken_li_Fzg_Takt 4;
BA_ "GenSigSwitchedByIgnition" SG_ 870 Blinken_li_Fzg_Takt 0;
BA_ "GenSigSendType" SG_ 870 Blinken_li_Kombi_Takt 4;
BA_ "GenSigSwitchedByIgnition" SG_ 870 Blinken_li_Kombi_Takt 0;
BA_ "GenSigSendType" SG_ 870 Blinken_re_Fzg_Takt 4;
BA_ "GenSigSwitchedByIgnition" SG_ 870 Blinken_re_Fzg_Takt 0;
BA_ "GenSigSendType" SG_ 870 Blinken_re_Kombi_Takt 4;
BA_ "GenSigSwitchedByIgnition" SG_ 870 Blinken_re_Kombi_Takt 0;
BA_ "GenSigFuncType" SG_ 870 Blinkmodi_02_BZ 1;
BA_ "GenSigSendType" SG_ 870 Blinkmodi_02_BZ 0;
BA_ "GenSigSwitchedByIgnition" SG_ 870 Blinkmodi_02_BZ 0;
BA_ "GenSigFuncType" SG_ 870 Blinkmodi_02_CRC 2;
BA_ "GenSigSendType" SG_ 870 Blinkmodi_02_CRC 0;
BA_ "GenSigSwitchedByIgnition" SG_ 870 Blinkmodi_02_CRC 0;
BA_ "GenSigSendType" SG_ 870 BM_Autobahn 4;
BA_ "GenSigSwitchedByIgnition" SG_ 870 BM_Autobahn 0;
BA_ "GenSigSendType" SG_ 870 BM_Crash 4;
BA_ "GenSigSwitchedByIgnition" SG_ 870 BM_Crash 0;
BA_ "GenSigSendType" SG_ 870 BM_DWA_Alarm 4;
BA_ "GenSigSwitchedByIgnition" SG_ 870 BM_DWA_Alarm 0;
BA_ "GenSigSendType" SG_ 870 BM_DWA_ein 4;
BA_ "GenSigSwitchedByIgnition" SG_ 870 BM_DWA_ein 0;
BA_ "GenSigSendType" SG_ 870 BM_GDO 4;
BA_ "GenSigSwitchedByIgnition" SG_ 870 BM_GDO 0;
BA_ "GenSigSendType" SG_ 870 BM_HD_Oeffnung_angelernt 3;
BA_ "GenSigSwitchedByIgnition" SG_ 870 BM_HD_Oeffnung_angelernt 0;
BA_ "GenSigSendType" SG_ 870 BM_links 4;
BA_ "GenSigSwitchedByIgnition" SG_ 870 BM_links 0;
BA_ "GenSigSendType" SG_ 870 BM_NBA_n_codiert_n_aktiv 3;
BA_ "GenSigStartValue" SG_ 870 BM_NBA_n_codiert_n_aktiv 1;
BA_ "GenSigSwitchedByIgnition" SG_ 870 BM_NBA_n_codiert_n_aktiv 0;
BA_ "GenSigSendType" SG_ 870 BM_NBA_Status 4;
BA_ "GenSigSwitchedByIgnition" SG_ 870 BM_NBA_Status 0;
BA_ "GenSigSendType" SG_ 870 BM_Not_Bremsung 4;
BA_ "GenSigSwitchedByIgnition" SG_ 870 BM_Not_Bremsung 0;
BA_ "GenSigSendType" SG_ 870 BM_Panik 4;
BA_ "GenSigSwitchedByIgnition" SG_ 870 BM_Panik 0;
BA_ "GenSigSendType" SG_ 870 BM_PiloPa 4;
BA_ "GenSigSwitchedByIgnition" SG_ 870 BM_PiloPa 0;
BA_ "GenSigSendType" SG_ 870 BM_Recas 5;
BA_ "GenSigSwitchedByIgnition" SG_ 870 BM_Recas 0;
BA_ "GenSigSendType" SG_ 870 BM_rechts 4;
BA_ "GenSigSwitchedByIgnition" SG_ 870 BM_rechts 0;
BA_ "GenSigSendType" SG_ 870 BM_Rollenmodus_Blinken 5;
BA_ "GenSigSwitchedByIgnition" SG_ 870 BM_Rollenmodus_Blinken 0;
BA_ "GenSigSendType" SG_ 870 BM_Taxi_Notalarm 4;
BA_ "GenSigSwitchedByIgnition" SG_ 870 BM_Taxi_Notalarm 0;
BA_ "GenSigSendType" SG_ 870 BM_Telematik 4;
BA_ "GenSigSwitchedByIgnition" SG_ 870 BM_Telematik 0;
BA_ "GenSigSendType" SG_ 870 BM_Telematik_Abbruchgrund 4;
BA_ "GenSigSwitchedByIgnition" SG_ 870 BM_Telematik_Abbruchgrund 0;
BA_ "GenSigSendType" SG_ 870 BM_Warnblinken 4;
BA_ "GenSigSwitchedByIgnition" SG_ 870 BM_Warnblinken 0;
BA_ "GenSigSendType" SG_ 870 BM_WBT_Beleuchtung 3;
BA_ "GenSigSwitchedByIgnition" SG_ 870 BM_WBT_Beleuchtung 0;
BA_ "GenSigSendType" SG_ 870 BM_Wischblinken 4;
BA_ "GenSigSwitchedByIgnition" SG_ 870 BM_Wischblinken 0;
BA_ "GenSigSendType" SG_ 870 BM_ZV_auf 4;
BA_ "GenSigSwitchedByIgnition" SG_ 870 BM_ZV_auf 0;
BA_ "GenSigSendType" SG_ 870 BM_ZV_zu 4;
BA_ "GenSigSwitchedByIgnition" SG_ 870 BM_ZV_zu 0;
BA_ "Fehlerwert" SG_ 870 DWA_Alarmquelle 31;
BA_ "GenSigSendType" SG_ 870 DWA_Alarmquelle 0;
BA_ "GenSigStartValue" SG_ 870 DWA_Alarmquelle 30;
BA_ "GenSigSwitchedByIgnition" SG_ 870 DWA_Alarmquelle 0;
BA_ "GenSigSendType" SG_ 870 SAL_TA_Blinken_Status 4;
BA_ "GenSigSwitchedByIgnition" SG_ 870 SAL_TA_Blinken_Status 0;
BA_ "Fehlerwert" SG_ 687 BMC_Spannung 16383;
BA_ "GenSigSendType" SG_ 687 BMC_Spannung 0;
BA_ "GenSigStartValue" SG_ 687 BMC_Spannung 16382;
BA_ "GenSigSwitchedByIgnition" SG_ 687 BMC_Spannung 0;
BA_ "GenSigSendType" SG_ 687 BMS_As_Entladezaehler 0;
BA_ "GenSigSwitchedByIgnition" SG_ 687 BMS_As_Entladezaehler 0;
BA_ "GenSigSendType" SG_ 687 BMS_As_Entladezaehler_Ueberlauf 0;
BA_ "GenSigSwitchedByIgnition" SG_ 687 BMS_As_Entladezaehler_Ueberlauf 0;
BA_ "GenSigSendType" SG_ 687 BMS_Rekuperation 0;
BA_ "GenSigSwitchedByIgnition" SG_ 687 BMS_Rekuperation 0;
BA_ "GenSigSendType" SG_ 687 BMS_Rekuperation_Ueberlauf 0;
BA_ "GenSigSwitchedByIgnition" SG_ 687 BMS_Rekuperation_Ueberlauf 0;
BA_ "GenSigSendType" SG_ 687 BMS_Verbrauch 0;
BA_ "GenSigSwitchedByIgnition" SG_ 687 BMS_Verbrauch 0;
BA_ "GenSigSendType" SG_ 687 BMS_Verbrauch_Ueberlauf 0;
BA_ "GenSigSwitchedByIgnition" SG_ 687 BMS_Verbrauch_Ueberlauf 0;
BA_ "GenSigFuncType" SG_ 1482 BMS_07_BZ 1;
BA_ "GenSigSendType" SG_ 1482 BMS_07_BZ 0;
BA_ "GenSigSwitchedByIgnition" SG_ 1482 BMS_07_BZ 0;
BA_ "GenSigFuncType" SG_ 1482 BMS_07_CRC 2;
BA_ "GenSigSendType" SG_ 1482 BMS_07_CRC 0;
BA_ "GenSigSwitchedByIgnition" SG_ 1482 BMS_07_CRC 0;
BA_ "GenSigSendType" SG_ 1482 BMS_Ausgleichsladung_Anf 0;
BA_ "GenSigSwitchedByIgnition" SG_ 1482 BMS_Ausgleichsladung_Anf 0;
BA_ "Fehlerwert" SG_ 1482 BMS_Batteriediagnose 7;
BA_ "GenSigSendType" SG_ 1482 BMS_Batteriediagnose 3;
BA_ "GenSigStartValue" SG_ 1482 BMS_Batteriediagnose 1;
BA_ "GenSigSwitchedByIgnition" SG_ 1482 BMS_Batteriediagnose 0;
BA_ "Fehlerwert" SG_ 1482 BMS_Energieinhalt 2047;
BA_ "GenSigSendType" SG_ 1482 BMS_Energieinhalt 0;
BA_ "GenSigStartValue" SG_ 1482 BMS_Energieinhalt 2046;
BA_ "GenSigSwitchedByIgnition" SG_ 1482 BMS_Energieinhalt 0;
BA_ "GenSigSendType" SG_ 1482 BMS_Gesamtst_Spgfreiheit 3;
BA_ "GenSigSwitchedByIgnition" SG_ 1482 BMS_Gesamtst_Spgfreiheit 0;
BA_ "GenSigSendType" SG_ 1482 BMS_KundenWarnung 3;
BA_ "GenSigSwitchedByIgnition" SG_ 1482 BMS_KundenWarnung 0;
BA_ "Fehlerwert" SG_ 1482 BMS_MaxEnergieinhalt 2047;
BA_ "GenSigSendType" SG_ 1482 BMS_MaxEnergieinhalt 0;
BA_ "GenSigStartValue" SG_ 1482 BMS_MaxEnergieinhalt 2046;
BA_ "GenSigSwitchedByIgnition" SG_ 1482 BMS_MaxEnergieinhalt 0;
BA_ "GenSigFuncType" SG_ 903 Bremse_EV_02_BZ 1;
BA_ "GenSigSendType" SG_ 903 Bremse_EV_02_BZ 0;
BA_ "GenSigSwitchedByIgnition" SG_ 903 Bremse_EV_02_BZ 0;
BA_ "GenSigFuncType" SG_ 903 Bremse_EV_02_CRC 2;
BA_ "GenSigSendType" SG_ 903 Bremse_EV_02_CRC 0;
BA_ "GenSigSwitchedByIgnition" SG_ 903 Bremse_EV_02_CRC 0;
BA_ "GenSigSendType" SG_ 903 EBKV_BKL_Warnungen 0;
BA_ "GenSigSwitchedByIgnition" SG_ 903 EBKV_BKL_Warnungen 0;
BA_ "GenSigSendType" SG_ 903 EBKV_Charisma_FahrPr 0;
BA_ "GenSigSwitchedByIgnition" SG_ 903 EBKV_Charisma_FahrPr 0;
BA_ "GenSigSendType" SG_ 903 EBKV_Charisma_Status 0;
BA_ "GenSigSwitchedByIgnition" SG_ 903 EBKV_Charisma_Status 0;
BA_ "GenSigSendType" SG_ 903 EBKV_Hinweise 0;
BA_ "GenSigSwitchedByIgnition" SG_ 903 EBKV_Hinweise 0;
BA_ "GenSigSendType" SG_ 903 EBKV_SpannungsAnf 0;
BA_ "GenSigSwitchedByIgnition" SG_ 903 EBKV_SpannungsAnf 0;
BA_ "GenSigSendType" SG_ 903 EBKV_Warnungen 0;
BA_ "GenSigSwitchedByIgnition" SG_ 903 EBKV_Warnungen 0;
BA_ "GenSigSendType" SG_ 903 EPB_Fehlermeldung_ext 0;
BA_ "GenSigSwitchedByIgnition" SG_ 903 EPB_Fehlermeldung_ext 0;
BA_ "GenSigSendType" SG_ 903 EPB_Funktionslampe_ext 0;
BA_ "GenSigSwitchedByIgnition" SG_ 903 EPB_Funktionslampe_ext 0;
BA_ "GenSigSendType" SG_ 902 CHA_Charge_LED 3;
BA_ "GenSigSwitchedByIgnition" SG_ 902 CHA_Charge_LED 0;
BA_ "Fehlerwert" SG_ 902 CHA_Charisma_Taste2_LED 3;
BA_ "GenSigSendType" SG_ 902 CHA_Charisma_Taste2_LED 3;
BA_ "GenSigSwitchedByIgnition" SG_ 902 CHA_Charisma_Taste2_LED 0;
BA_ "GenSigSendType" SG_ 902 CHA_Current_Mode 3;
BA_ "GenSigSwitchedByIgnition" SG_ 902 CHA_Current_Mode 0;
BA_ "GenSigSendType" SG_ 902 CHA_Current_Mode_FPA 3;
BA_ "GenSigSwitchedByIgnition" SG_ 902 CHA_Current_Mode_FPA 0;
BA_ "GenSigSendType" SG_ 902 CHA_Eco_Charisma_LED 3;
BA_ "GenSigSwitchedByIgnition" SG_ 902 CHA_Eco_Charisma_LED 0;
BA_ "GenSigSendType" SG_ 902 CHA_EV_LED 3;
BA_ "GenSigSwitchedByIgnition" SG_ 902 CHA_EV_LED 0;
BA_ "GenSigSendType" SG_ 902 CHA_Fahrer_Umschaltung 3;
BA_ "GenSigSwitchedByIgnition" SG_ 902 CHA_Fahrer_Umschaltung 0;
BA_ "GenSigSendType" SG_ 902 CHA_Kombi_Texte 3;
BA_ "GenSigSwitchedByIgnition" SG_ 902 CHA_Kombi_Texte 0;
BA_ "GenSigSendType" SG_ 902 CHA_Kombi_Texte_02 3;
BA_ "GenSigSwitchedByIgnition" SG_ 902 CHA_Kombi_Texte_02 0;
BA_ "Fehlerwert" SG_ 902 CHA_Offroad_LED 3;
BA_ "GenSigSendType" SG_ 902 CHA_Offroad_LED 3;
BA_ "GenSigSwitchedByIgnition" SG_ 902 CHA_Offroad_LED 0;
BA_ "GenSigSendType" SG_ 902 CHA_ReqPrgDispSetup 3;
BA_ "GenSigSwitchedByIgnition" SG_ 902 CHA_ReqPrgDispSetup 0;
BA_ "GenSigSendType" SG_ 902 CHA_StCurProfDft 3;
BA_ "GenSigSwitchedByIgnition" SG_ 902 CHA_StCurProfDft 0;
BA_ "GenSigSendType" SG_ 902 CHA_Ziel_FahrPr_03_01 3;
BA_ "GenSigSwitchedByIgnition" SG_ 902 CHA_Ziel_FahrPr_03_01 0;
BA_ "GenSigSendType" SG_ 902 CHA_Ziel_FahrPr_03_02 3;
BA_ "GenSigSwitchedByIgnition" SG_ 902 CHA_Ziel_FahrPr_03_02 0;
BA_ "GenSigSendType" SG_ 902 CHA_Ziel_FahrPr_AMB 3;
BA_ "GenSigSwitchedByIgnition" SG_ 902 CHA_Ziel_FahrPr_AMB 0;
BA_ "GenSigSendType" SG_ 902 CHA_Ziel_FahrPr_HSP 3;
BA_ "GenSigSwitchedByIgnition" SG_ 902 CHA_Ziel_FahrPr_HSP 0;
BA_ "GenSigSendType" SG_ 902 CHA_Ziel_FahrPr_IVB 3;
BA_ "GenSigSwitchedByIgnition" SG_ 902 CHA_Ziel_FahrPr_IVB 0;
BA_ "GenSigSendType" SG_ 902 CHA_Ziel_FahrPr_KL 3;
BA_ "GenSigSwitchedByIgnition" SG_ 902 CHA_Ziel_FahrPr_KL 0;
BA_ "GenSigSendType" SG_ 902 CHA_Ziel_FahrPr_RWB 3;
BA_ "GenSigSwitchedByIgnition" SG_ 902 CHA_Ziel_FahrPr_RWB 0;
BA_ "GenSigSendType" SG_ 918 DR_Gelbe_Warnlampe 0;
BA_ "GenSigSwitchedByIgnition" SG_ 918 DR_Gelbe_Warnlampe 0;
BA_ "GenSigSendType" SG_ 2463978758 DR_DCCMonitor_I_Add 0;
BA_ "GenSigSwitchedByIgnition" SG_ 2463978758 DR_DCCMonitor_I_Add 0;
BA_ "GenSigSendType" SG_ 2463978758 DR_DCCMonitor_I_HL 0;
BA_ "GenSigSwitchedByIgnition" SG_ 2463978758 DR_DCCMonitor_I_HL 0;
BA_ "GenSigSendType" SG_ 2463978758 DR_DCCMonitor_I_HR 0;
BA_ "GenSigSwitchedByIgnition" SG_ 2463978758 DR_DCCMonitor_I_HR 0;
BA_ "GenSigSendType" SG_ 2463978758 DR_DCCMonitor_I_SZ_Add 0;
BA_ "GenSigSwitchedByIgnition" SG_ 2463978758 DR_DCCMonitor_I_SZ_Add 0;
BA_ "GenSigSendType" SG_ 2463978758 DR_DCCMonitor_I_SZ_HL 0;
BA_ "GenSigSwitchedByIgnition" SG_ 2463978758 DR_DCCMonitor_I_SZ_HL 0;
BA_ "GenSigSendType" SG_ 2463978758 DR_DCCMonitor_I_SZ_HR 0;
BA_ "GenSigSwitchedByIgnition" SG_ 2463978758 DR_DCCMonitor_I_SZ_HR 0;
BA_ "GenSigSendType" SG_ 2463978758 DR_DCCMonitor_I_SZ_VL 0;
BA_ "GenSigSwitchedByIgnition" SG_ 2463978758 DR_DCCMonitor_I_SZ_VL 0;
BA_ "GenSigSendType" SG_ 2463978758 DR_DCCMonitor_I_SZ_VR 0;
BA_ "GenSigSwitchedByIgnition" SG_ 2463978758 DR_DCCMonitor_I_SZ_VR 0;
BA_ "GenSigSendType" SG_ 2463978758 DR_DCCMonitor_I_VL 0;
BA_ "GenSigSwitchedByIgnition" SG_ 2463978758 DR_DCCMonitor_I_VL 0;
BA_ "GenSigSendType" SG_ 2463978758 DR_DCCMonitor_I_VR 0;
BA_ "GenSigSwitchedByIgnition" SG_ 2463978758 DR_DCCMonitor_I_VR 0;
BA_ "Fehlerwert" SG_ 1012 DC_HYB_Auslastungsgrad 255;
BA_ "GenSigSendType" SG_ 1012 DC_HYB_Auslastungsgrad 0;
BA_ "GenSigStartValue" SG_ 1012 DC_HYB_Auslastungsgrad 254;
BA_ "Fehlerwert" SG_ 1012 DC_ReserveStrom_NV 1023;
BA_ "GenSigSendType" SG_ 1012 DC_ReserveStrom_NV 0;
BA_ "GenSigStartValue" SG_ 1012 DC_ReserveStrom_NV 1022;
BA_ "GenSigSwitchedByIgnition" SG_ 1012 DC_ReserveStrom_NV 0;
BA_ "GenSigSendType" SG_ 1012 DC_Verbrauch 0;
BA_ "GenSigSwitchedByIgnition" SG_ 1012 DC_Verbrauch 0;
BA_ "GenSigSendType" SG_ 1012 DC_Verbrauch_Ueberlauf 0;
BA_ "GenSigSwitchedByIgnition" SG_ 1012 DC_Verbrauch_Ueberlauf 0;
BA_ "Fehlerwert" SG_ 1012 DC_Verlustleistung 63;
BA_ "GenSigSendType" SG_ 1012 DC_Verlustleistung 0;
BA_ "GenSigStartValue" SG_ 1012 DC_Verlustleistung 62;
BA_ "GenSigSwitchedByIgnition" SG_ 1012 DC_Verlustleistung 0;
BA_ "GenSigFuncType" SG_ 1012 DCDC_02_BZ 1;
BA_ "GenSigSendType" SG_ 1012 DCDC_02_BZ 0;
BA_ "GenSigSwitchedByIgnition" SG_ 1012 DCDC_02_BZ 0;
BA_ "GenSigFuncType" SG_ 1012 DCDC_02_CRC 2;
BA_ "GenSigSendType" SG_ 1012 DCDC_02_CRC 0;
BA_ "GenSigSwitchedByIgnition" SG_ 1012 DCDC_02_CRC 0;
BA_ "GenSigSwitchedByIgnition" SG_ 2617039369 DEV_HUD_Rx_09_Data 0;
BA_ "GenSigSwitchedByIgnition" SG_ 2617039370 DEV_HUD_Rx_10_Data 0;
BA_ "GenSigSwitchedByIgnition" SG_ 2617039361 DEV_HUD_Tx_01_Data 0;
BA_ "GenSigSwitchedByIgnition" SG_ 2617039362 DEV_HUD_Tx_02_Data 0;
BA_ "GenSigSwitchedByIgnition" SG_ 2591834880 DEV_SmaLi_Tx_01_Data 0;
BA_ "GenSigSwitchedByIgnition" SG_ 2617219613 DEV_ZR_Produktion_1_Rx_1D_Data 0;
BA_ "GenSigSwitchedByIgnition" SG_ 2617219612 DEV_ZR_Produktion_1_Tx_1C_Data 0;
BA_ "GenSigSwitchedByIgnition" SG_ 2617219597 DEV_ZR_Req_0D_Data 0;
BA_ "GenSigSwitchedByIgnition" SG_ 2617219584 DEV_ZR_Resp_00_Data 0;
BA_ "GenSigSwitchedByIgnition" SG_ 2617219621 DEV_ZR_SmaLi_01_Tx 0;
BA_ "GenSigSwitchedByIgnition" SG_ 2617219604 DEV_ZR_Tx_14_Data 0;
BA_ "GenSigSwitchedByIgnition" SG_ 2617219605 DEV_ZR_Tx_15_Data 0;
BA_ "GenSigSwitchedByIgnition" SG_ 2617219605 MMI_State 0;
BA_ "GenSigStartValue" SG_ 2617219605 Reset_Counter 254;
BA_ "GenSigSwitchedByIgnition" SG_ 2617219605 Reset_Counter 0;
BA_ "GenSigSwitchedByIgnition" SG_ 2617219605 Routeg_aktiv 0;
BA_ "GenSigSwitchedByIgnition" SG_ 2617219605 SI_MOST_Status 0;
BA_ "GenSigSwitchedByIgnition" SG_ 2617219605 Tel_aktiv 0;
BA_ "GenSigSwitchedByIgnition" SG_ 2617219605 Tel_SIM_aktiv 0;
BA_ "Fehlerwert" SG_ 2617219605 ZR_KL_30F 255;
BA_ "GenSigStartValue" SG_ 2617219605 ZR_KL_30F 254;
BA_ "GenSigSwitchedByIgnition" SG_ 2617219605 ZR_KL_30F 0;
BA_ "GenSigStartValue" SG_ 2617219605 ZR_LastOn 7;
BA_ "GenSigSwitchedByIgnition" SG_ 2617219605 ZR_LastOn 0;
BA_ "GenSigSwitchedByIgnition" SG_ 2617219605 ZR_State_DU_1 0;
BA_ "Fehlerwert" SG_ 2617219605 ZR_TempSens 255;
BA_ "GenSigStartValue" SG_ 2617219605 ZR_TempSens 254;
BA_ "GenSigSwitchedByIgnition" SG_ 2617219605 ZR_TempSens 0;
BA_ "GenSigFuncType" SG_ 2549880334 DIA_ABT_1_Req_Data 9;
BA_ "GenSigSendType" SG_ 2549880334 DIA_ABT_1_Req_Data 3;
BA_ "GenSigSwitchedByIgnition" SG_ 2549880334 DIA_ABT_1_Req_Data 0;
BA_ "GenSigFuncType" SG_ 2550011406 DIA_ABT_1_Resp_Data 9;
BA_ "GenSigSendType" SG_ 2550011406 DIA_ABT_1_Resp_Data 3;
BA_ "GenSigSwitchedByIgnition" SG_ 2550011406 DIA_ABT_1_Resp_Data 0;
BA_ "GenSigSendType" SG_ 1714 DGN_Verlernzaehler 0;
BA_ "GenSigSwitchedByIgnition" SG_ 1714 DGN_Verlernzaehler 0;
BA_ "Fehlerwert" SG_ 1714 KBI_Kilometerstand 1048575;
BA_ "GenSigSendType" SG_ 1714 KBI_Kilometerstand 0;
BA_ "GenSigStartValue" SG_ 1714 KBI_Kilometerstand 1048574;
BA_ "GenSigSwitchedByIgnition" SG_ 1714 KBI_Kilometerstand 0;
BA_ "GenSigFuncType" SG_ 1714 Kombi_02_alt 5;
BA_ "GenSigSendType" SG_ 1714 Kombi_02_alt 0;
BA_ "GenSigStartValue" SG_ 1714 Kombi_02_alt 1;
BA_ "GenSigSwitchedByIgnition" SG_ 1714 Kombi_02_alt 0;
BA_ "GenSigSendType" SG_ 1714 UH_Jahr 0;
BA_ "GenSigSwitchedByIgnition" SG_ 1714 UH_Jahr 0;
BA_ "GenSigSendType" SG_ 1714 UH_Minute 0;
BA_ "GenSigSwitchedByIgnition" SG_ 1714 UH_Minute 0;
BA_ "Fehlerwert" SG_ 1714 UH_Monat 15;
BA_ "GenSigSendType" SG_ 1714 UH_Monat 0;
BA_ "GenSigSwitchedByIgnition" SG_ 1714 UH_Monat 0;
BA_ "GenSigSendType" SG_ 1714 UH_Sekunde 0;
BA_ "GenSigSwitchedByIgnition" SG_ 1714 UH_Sekunde 0;
BA_ "GenSigSendType" SG_ 1714 UH_Stunde 0;
BA_ "GenSigSwitchedByIgnition" SG_ 1714 UH_Stunde 0;
BA_ "GenSigSendType" SG_ 1714 UH_Tag 0;
BA_ "GenSigSwitchedByIgnition" SG_ 1714 UH_Tag 0;
BA_ "GenSigFuncType" SG_ 1714 Uhrzeit_01_alt 5;
BA_ "GenSigSendType" SG_ 1714 Uhrzeit_01_alt 0;
BA_ "GenSigStartValue" SG_ 1714 Uhrzeit_01_alt 1;
BA_ "GenSigSwitchedByIgnition" SG_ 1714 Uhrzeit_01_alt 0;
BA_ "GenSigSendType" SG_ 1714 Vehicle_Driving_Cycle 0;
BA_ "GenSigSwitchedByIgnition" SG_ 1714 Vehicle_Driving_Cycle 0;
BA_REL_ "GenSigTimeoutTime" BU_SG_REL_ Fahrerdisplay_Kombi SG_ 870 Blinken_li_Kombi_Takt 5000;
BA_REL_ "GenSigTimeoutTime" BU_SG_REL_ Fahrerdisplay_Kombi SG_ 870 Blinken_re_Kombi_Takt 5000;
BA_REL_ "GenSigTimeoutTime" BU_SG_REL_ Fahrerdisplay_Kombi SG_ 903 Bremse_EV_02_BZ 1000;
BA_REL_ "GenSigTimeoutTime" BU_SG_REL_ Fahrerdisplay_Kombi SG_ 903 Bremse_EV_02_CRC 1000;
BA_REL_ "GenSigTimeoutTime" BU_SG_REL_ Fahrerdisplay_Kombi SG_ 903 EPB_Fehlermeldung_ext 1000;
BA_REL_ "GenSigTimeoutTime" BU_SG_REL_ Fahrerdisplay_Kombi SG_ 903 EPB_Funktionslampe_ext 1000;
BA_REL_ "GenSigTimeoutTime" BU_SG_REL_ Fahrerdisplay_Kombi SG_ 1163 BEM_06_BZ 1000;
BA_REL_ "GenSigTimeoutTime" BU_SG_REL_ Fahrerdisplay_Kombi SG_ 1163 BEM_06_CRC 1000;
BA_REL_ "GenSigTimeoutTime" BU_SG_REL_ Fahrerdisplay_Kombi SG_ 1163 NVEM_Bordnetzdiagnose 1000;
BA_REL_ "GenSigTimeoutTime" BU_SG_REL_ Fahrerdisplay_Kombi SG_ 1482 BMS_KundenWarnung 5000;
BA_REL_ "GenSigTimeoutTime" BU_SG_REL_ Fahrerdisplay_Kombi SG_ 1626 BCM_Bremsfluessigkeit_Sensor 5000;
BA_REL_ "GenSigTimeoutTime" BU_SG_REL_ Fahrerdisplay_Kombi SG_ 1714 DGN_Verlernzaehler 5000;
BA_REL_ "GenSigTimeoutTime" BU_SG_REL_ Fahrerdisplay_Kombi SG_ 1714 KBI_Kilometerstand 5000;
BA_REL_ "GenSigTimeoutTime" BU_SG_REL_ Fahrerdisplay_Kombi SG_ 1714 UH_Jahr 5000;
BA_REL_ "GenSigTimeoutTime" BU_SG_REL_ Fahrerdisplay_Kombi SG_ 1714 UH_Minute 5000;
BA_REL_ "GenSigTimeoutTime" BU_SG_REL_ Fahrerdisplay_Kombi SG_ 1714 UH_Monat 5000;
BA_REL_ "GenSigTimeoutTime" BU_SG_REL_ Fahrerdisplay_Kombi SG_ 1714 UH_Sekunde 5000;
BA_REL_ "GenSigTimeoutTime" BU_SG_REL_ Fahrerdisplay_Kombi SG_ 1714 UH_Stunde 5000;
BA_REL_ "GenSigTimeoutTime" BU_SG_REL_ Fahrerdisplay_Kombi SG_ 1714 UH_Tag 5000;
BA_REL_ "GenSigTimeoutTime" BU_SG_REL_ HUD SG_ 1635 NVEM_Abschaltstufe 1000;
BA_REL_ "GenSigTimeoutTime" BU_SG_REL_ HUD SG_ 1714 DGN_Verlernzaehler 5000;
BA_REL_ "GenSigTimeoutTime" BU_SG_REL_ HUD SG_ 1714 KBI_Kilometerstand 5000;
BA_REL_ "GenSigTimeoutTime" BU_SG_REL_ HUD SG_ 1714 UH_Jahr 5000;
BA_REL_ "GenSigTimeoutTime" BU_SG_REL_ HUD SG_ 1714 UH_Minute 5000;
BA_REL_ "GenSigTimeoutTime" BU_SG_REL_ HUD SG_ 1714 UH_Monat 5000;
BA_REL_ "GenSigTimeoutTime" BU_SG_REL_ HUD SG_ 1714 UH_Sekunde 5000;
BA_REL_ "GenSigTimeoutTime" BU_SG_REL_ HUD SG_ 1714 UH_Stunde 5000;
BA_REL_ "GenSigTimeoutTime" BU_SG_REL_ HUD SG_ 1714 UH_Tag 5000;
BA_REL_ "GenSigTimeoutTime" BU_SG_REL_ ICAS1_X_Gateway SG_ 2536702720 BAP_ParkHeater_ASG_01_Header 800;
BA_REL_ "GenSigTimeoutTime" BU_SG_REL_ ICAS1_X_Gateway SG_ 2536705536 BAP_Mirror_ASG_01_Header 800;
BA_REL_ "GenSigTimeoutTime" BU_SG_REL_ ICAS1_X_Gateway SG_ 2536710656 BAP_MKE_ASG_01_Header 800;
BA_REL_ "GenSigTimeoutTime" BU_SG_REL_ ICAS1_X_Gateway SG_ 2536721664 BAP_FAS_Profiles_ASG_01_Header 800;
BA_REL_ "GenSigTimeoutTime" BU_SG_REL_ ICAS1_X_Gateway SG_ 2536721921 BAP_RemoteServices_ASG_02_Header 800;
BA_REL_ "GenSigTimeoutTime" BU_SG_REL_ ICAS1_X_Gateway SG_ 2536722944 BAP_IAA_PSO_ASG_01_Header 800;
BA_REL_ "GenSigTimeoutTime" BU_SG_REL_ ICAS1_X_Gateway SG_ 2536723712 BAP_PaCo_ASG_01_Header 500;
BA_REL_ "GenSigTimeoutTime" BU_SG_REL_ ICAS1_X_Gateway SG_ 2536723713 BAP_PaCo_ASG_02_Header 500;
BA_REL_ "GenSigTimeoutTime" BU_SG_REL_ ICAS1_X_Gateway SG_ 2536729088 BAP_Innenlicht2_ASG_01_Header 800;
BA_REL_ "GenSigTimeoutTime" BU_SG_REL_ ICAS1_X_Gateway SG_ 2536732416 BAP_MobDevKey_ASG_01_Header 800;
BA_REL_ "GenSigTimeoutTime" BU_SG_REL_ ICAS3_Gateway SG_ 870 Blinken_li_Kombi_Takt 5000;
BA_REL_ "GenSigTimeoutTime" BU_SG_REL_ ICAS3_Gateway SG_ 870 Blinken_re_Kombi_Takt 5000;
BA_REL_ "GenSigTimeoutTime" BU_SG_REL_ ICAS3_Gateway SG_ 1432 LINDa_Touch_Event 5000;
BA_REL_ "GenSigTimeoutTime" BU_SG_REL_ ICAS3_Gateway SG_ 1626 BCM1_MH_Schalter 5000;
BA_REL_ "GenSigTimeoutTime" BU_SG_REL_ ICAS3_Gateway SG_ 1635 BEM_MMI_Vorwarnung 1000;
BA_REL_ "GenSigTimeoutTime" BU_SG_REL_ ICAS3_Gateway SG_ 1635 NVEM_Abschaltstufe 1000;
BA_REL_ "GenSigTimeoutTime" BU_SG_REL_ ICAS3_Gateway SG_ 1635 NVEM_Freigabe_OnlineUpdate 1000;
BA_REL_ "GenSigTimeoutTime" BU_SG_REL_ ICAS3_Gateway SG_ 1714 DGN_Verlernzaehler 5000;
BA_REL_ "GenSigTimeoutTime" BU_SG_REL_ ICAS3_Gateway SG_ 1714 KBI_Kilometerstand 5000;
BA_REL_ "GenSigTimeoutTime" BU_SG_REL_ ICAS3_Gateway SG_ 1714 UH_Jahr 5000;
BA_REL_ "GenSigTimeoutTime" BU_SG_REL_ ICAS3_Gateway SG_ 1714 UH_Minute 5000;
BA_REL_ "GenSigTimeoutTime" BU_SG_REL_ ICAS3_Gateway SG_ 1714 UH_Monat 5000;
BA_REL_ "GenSigTimeoutTime" BU_SG_REL_ ICAS3_Gateway SG_ 1714 UH_Sekunde 5000;
BA_REL_ "GenSigTimeoutTime" BU_SG_REL_ ICAS3_Gateway SG_ 1714 UH_Stunde 5000;
BA_REL_ "GenSigTimeoutTime" BU_SG_REL_ ICAS3_Gateway SG_ 1714 UH_Tag 5000;
BA_REL_ "GenSigTimeoutTime" BU_SG_REL_ ICAS3_Gateway SG_ 1714 Vehicle_Driving_Cycle 5000;
BA_REL_ "GenSigTimeoutTime" BU_SG_REL_ ICAS3_Gateway SG_ 2463978607 BCM_RGB_Blau 2000;
BA_REL_ "GenSigTimeoutTime" BU_SG_REL_ ICAS3_Gateway SG_ 2463978607 BCM_RGB_Gruen 2000;
BA_REL_ "GenSigTimeoutTime" BU_SG_REL_ ICAS3_Gateway SG_ 2463978607 BCM_RGB_Rot 2000;
BA_REL_ "GenSigTimeoutTime" BU_SG_REL_ ICAS3_Gateway SG_ 2463978758 DR_DCCMonitor_I_Add 1000;
BA_REL_ "GenSigTimeoutTime" BU_SG_REL_ ICAS3_Gateway SG_ 2463978758 DR_DCCMonitor_I_HL 1000;
BA_REL_ "GenSigTimeoutTime" BU_SG_REL_ ICAS3_Gateway SG_ 2463978758 DR_DCCMonitor_I_HR 1000;
BA_REL_ "GenSigTimeoutTime" BU_SG_REL_ ICAS3_Gateway SG_ 2463978758 DR_DCCMonitor_I_SZ_Add 1000;
BA_REL_ "GenSigTimeoutTime" BU_SG_REL_ ICAS3_Gateway SG_ 2463978758 DR_DCCMonitor_I_SZ_HL 1000;
BA_REL_ "GenSigTimeoutTime" BU_SG_REL_ ICAS3_Gateway SG_ 2463978758 DR_DCCMonitor_I_SZ_HR 1000;
BA_REL_ "GenSigTimeoutTime" BU_SG_REL_ ICAS3_Gateway SG_ 2463978758 DR_DCCMonitor_I_SZ_VL 1000;
BA_REL_ "GenSigTimeoutTime" BU_SG_REL_ ICAS3_Gateway SG_ 2463978758 DR_DCCMonitor_I_SZ_VR 1000;
BA_REL_ "GenSigTimeoutTime" BU_SG_REL_ ICAS3_Gateway SG_ 2463978758 DR_DCCMonitor_I_VL 1000;
BA_REL_ "GenSigTimeoutTime" BU_SG_REL_ ICAS3_Gateway SG_ 2463978758 DR_DCCMonitor_I_VR 1000;
BA_REL_ "GenSigTimeoutTime" BU_SG_REL_ ICAS3_Gateway SG_ 2463978850 NVEM_HVEM_FunktionsAnf 1000;
BA_REL_ "GenSigTimeoutTime" BU_SG_REL_ ICAS3_Gateway SG_ 2527679637 BCM_LTM_Allwetterl_Status 5000;
BA_REL_ "GenSigTimeoutTime" BU_SG_REL_ ICAS3_Gateway SG_ 2527679781 LINDa_HL_SR3_Touch_Event 5000;
BA_REL_ "GenSigTimeoutTime" BU_SG_REL_ ICAS3_Gateway SG_ 2527679781 LINDa_HL_Touch_Event 5000;
BA_REL_ "GenSigTimeoutTime" BU_SG_REL_ ICAS3_Gateway SG_ 2527679781 LINDa_HR_SR3_Touch_Event 5000;
BA_REL_ "GenSigTimeoutTime" BU_SG_REL_ ICAS3_Gateway SG_ 2527679781 LINDa_HR_Touch_Event 5000;
BA_REL_ "GenSigTimeoutTime" BU_SG_REL_ ICAS3_Gateway SG_ 2536702224 BAP_Klima1_FSG_01_Header 5000;
BA_REL_ "GenSigTimeoutTime" BU_SG_REL_ ICAS3_Gateway SG_ 2536702480 BAP_Klima2_FSG_01_Header 5000;
BA_REL_ "GenSigTimeoutTime" BU_SG_REL_ ICAS3_Gateway SG_ 2536702736 BAP_ParkHeater_FSG_01_Header 5000;
BA_REL_ "GenSigTimeoutTime" BU_SG_REL_ ICAS3_Gateway SG_ 2536703760 BAP_RDK_FSG_01_Header 5000;
BA_REL_ "GenSigTimeoutTime" BU_SG_REL_ ICAS3_Gateway SG_ 2536704016 BAP_Innenlicht_FSG_01_Header 5000;
BA_REL_ "GenSigTimeoutTime" BU_SG_REL_ ICAS3_Gateway SG_ 2536704528 BAP_OPS_FSG_01_Header 5000;
BA_REL_ "GenSigTimeoutTime" BU_SG_REL_ ICAS3_Gateway SG_ 2536704529 BAP_OPS_FSG_02_Header 5000;
BA_REL_ "GenSigTimeoutTime" BU_SG_REL_ ICAS3_Gateway SG_ 2536704784 BAP_RVC_FSG_01_Header 5000;
BA_REL_ "GenSigTimeoutTime" BU_SG_REL_ ICAS3_Gateway SG_ 2536705040 BAP_Wiper_FSG_01_Header 5000;
BA_REL_ "GenSigTimeoutTime" BU_SG_REL_ ICAS3_Gateway SG_ 2536705552 BAP_Mirror_FSG_01_Header 5000;
BA_REL_ "GenSigTimeoutTime" BU_SG_REL_ ICAS3_Gateway SG_ 2536706064 BAP_Sitz1_FSG_01_Header 5000;
BA_REL_ "GenSigTimeoutTime" BU_SG_REL_ ICAS3_Gateway SG_ 2536708368 BAP_LDW_FSG_01_Header 5000;
BA_REL_ "GenSigTimeoutTime" BU_SG_REL_ ICAS3_Gateway SG_ 2536708624 BAP_SWA_FSG_01_Header 5000;
BA_REL_ "GenSigTimeoutTime" BU_SG_REL_ ICAS3_Gateway SG_ 2536710416 BAP_VZA_FSG_01_Header 5000;
BA_REL_ "GenSigTimeoutTime" BU_SG_REL_ ICAS3_Gateway SG_ 2536710672 BAP_MKE_FSG_01_Header 5000;
BA_REL_ "GenSigTimeoutTime" BU_SG_REL_ ICAS3_Gateway SG_ 2536715792 BAP_TrailerAssist_FSG_01_Header 5000;
BA_REL_ "GenSigTimeoutTime" BU_SG_REL_ ICAS3_Gateway SG_ 2536717072 BAP_SeatPneumatic_FSG_01_Header 5000;
BA_REL_ "GenSigTimeoutTime" BU_SG_REL_ ICAS3_Gateway SG_ 2536718864 BAP_KlimaMaster_FSG_01_Header 5000;
BA_REL_ "GenSigTimeoutTime" BU_SG_REL_ ICAS3_Gateway SG_ 2536721168 BAP_Sunroof_FSG_01_Header 5000;
BA_REL_ "GenSigTimeoutTime" BU_SG_REL_ ICAS3_Gateway SG_ 2536721680 BAP_FAS_Profiles_FSG_01_Header 5000;
BA_REL_ "GenSigTimeoutTime" BU_SG_REL_ ICAS3_Gateway SG_ 2536721936 BAP_RemoteServices_FSG_01_Header 5000;
BA_REL_ "GenSigTimeoutTime" BU_SG_REL_ ICAS3_Gateway SG_ 2536722434 BAP_InfoSettings_ASG_03_Header 500;
BA_REL_ "GenSigTimeoutTime" BU_SG_REL_ ICAS3_Gateway SG_ 2536722960 BAP_IAA_PSO_FSG_01_Header 5000;
BA_REL_ "GenSigTimeoutTime" BU_SG_REL_ ICAS3_Gateway SG_ 2536723728 BAP_PaCo_FSG_01_Header 5000;
BA_REL_ "GenSigTimeoutTime" BU_SG_REL_ ICAS3_Gateway SG_ 2536726288 BAP_TPA_FSG_01_Header 5000;
BA_REL_ "GenSigTimeoutTime" BU_SG_REL_ ICAS3_Gateway SG_ 2536728592 BAP_THA_FSG_01_Header 5000;
BA_REL_ "GenSigTimeoutTime" BU_SG_REL_ ICAS3_Gateway SG_ 2536729104 BAP_Innenlicht2_FSG_01_Header 5000;
BA_REL_ "GenSigTimeoutTime" BU_SG_REL_ ICAS3_Gateway SG_ 2536732432 BAP_MobDevKey_FSG_01_Header 5000;
BA_REL_ "GenSigTimeoutTime" BU_SG_REL_ ICC_IO_Node SG_ 1432 LINDa_Touch_Event 5000;
BA_REL_ "GenSigTimeoutTime" BU_SG_REL_ ICC_IO_Node SG_ 1635 BEM_MMI_Vorwarnung 1000;
BA_REL_ "GenSigTimeoutTime" BU_SG_REL_ ICC_IO_Node SG_ 1635 NVEM_Abschaltstufe 1000;
BA_REL_ "GenSigTimeoutTime" BU_SG_REL_ ICC_IO_Node SG_ 1714 DGN_Verlernzaehler 5000;
BA_REL_ "GenSigTimeoutTime" BU_SG_REL_ ICC_IO_Node SG_ 1714 KBI_Kilometerstand 5000;
BA_REL_ "GenSigTimeoutTime" BU_SG_REL_ ICC_IO_Node SG_ 1714 UH_Jahr 5000;
BA_REL_ "GenSigTimeoutTime" BU_SG_REL_ ICC_IO_Node SG_ 1714 UH_Minute 5000;
BA_REL_ "GenSigTimeoutTime" BU_SG_REL_ ICC_IO_Node SG_ 1714 UH_Monat 5000;
BA_REL_ "GenSigTimeoutTime" BU_SG_REL_ ICC_IO_Node SG_ 1714 UH_Sekunde 5000;
BA_REL_ "GenSigTimeoutTime" BU_SG_REL_ ICC_IO_Node SG_ 1714 UH_Stunde 5000;
BA_REL_ "GenSigTimeoutTime" BU_SG_REL_ ICC_IO_Node SG_ 1714 UH_Tag 5000;
BA_REL_ "GenSigTimeoutTime" BU_SG_REL_ ICC_IO_Node SG_ 1714 Vehicle_Driving_Cycle 5000;
BA_REL_ "GenSigTimeoutTime" BU_SG_REL_ ICC_IO_Node SG_ 2527679781 LINDa_HL_SR3_Touch_Event 5000;
BA_REL_ "GenSigTimeoutTime" BU_SG_REL_ ICC_IO_Node SG_ 2527679781 LINDa_HL_Touch_Event 5000;
BA_REL_ "GenSigTimeoutTime" BU_SG_REL_ ICC_IO_Node SG_ 2527679781 LINDa_HR_SR3_Touch_Event 5000;
BA_REL_ "GenSigTimeoutTime" BU_SG_REL_ ICC_IO_Node SG_ 2527679781 LINDa_HR_Touch_Event 5000;
BA_REL_ "GenSigTimeoutTime" BU_SG_REL_ Kombi SG_ 687 BMS_Rekuperation 500;
BA_REL_ "GenSigTimeoutTime" BU_SG_REL_ Kombi SG_ 687 BMS_Rekuperation_Ueberlauf 500;
BA_REL_ "GenSigTimeoutTime" BU_SG_REL_ Kombi SG_ 687 BMS_Verbrauch 500;
BA_REL_ "GenSigTimeoutTime" BU_SG_REL_ Kombi SG_ 687 BMS_Verbrauch_Ueberlauf 500;
BA_REL_ "GenSigTimeoutTime" BU_SG_REL_ Kombi SG_ 870 BM_Warnblinken 5000;
BA_REL_ "GenSigTimeoutTime" BU_SG_REL_ Kombi SG_ 870 Blinken_li_Kombi_Takt 5000;
BA_REL_ "GenSigTimeoutTime" BU_SG_REL_ Kombi SG_ 870 Blinken_re_Kombi_Takt 5000;
BA_REL_ "GenSigTimeoutTime" BU_SG_REL_ Kombi SG_ 902 CHA_Current_Mode_FPA 5000;
BA_REL_ "GenSigTimeoutTime" BU_SG_REL_ Kombi SG_ 902 CHA_Kombi_Texte 5000;
BA_REL_ "GenSigTimeoutTime" BU_SG_REL_ Kombi SG_ 902 CHA_Kombi_Texte_02 5000;
BA_REL_ "GenSigTimeoutTime" BU_SG_REL_ Kombi SG_ 902 CHA_ReqPrgDispSetup 5000;
BA_REL_ "GenSigTimeoutTime" BU_SG_REL_ Kombi SG_ 902 CHA_StCurProfDft 5000;
BA_REL_ "GenSigTimeoutTime" BU_SG_REL_ Kombi SG_ 903 Bremse_EV_02_BZ 1000;
BA_REL_ "GenSigTimeoutTime" BU_SG_REL_ Kombi SG_ 903 Bremse_EV_02_CRC 1000;
BA_REL_ "GenSigTimeoutTime" BU_SG_REL_ Kombi SG_ 903 EBKV_Hinweise 1000;
BA_REL_ "GenSigTimeoutTime" BU_SG_REL_ Kombi SG_ 903 EBKV_Warnungen 1000;
BA_REL_ "GenSigTimeoutTime" BU_SG_REL_ Kombi SG_ 903 EPB_Fehlermeldung_ext 1000;
BA_REL_ "GenSigTimeoutTime" BU_SG_REL_ Kombi SG_ 903 EPB_Funktionslampe_ext 1000;
BA_REL_ "GenSigTimeoutTime" BU_SG_REL_ Kombi SG_ 918 DR_Gelbe_Warnlampe 1000;
BA_REL_ "GenSigTimeoutTime" BU_SG_REL_ Kombi SG_ 1012 DC_Verbrauch 500;
BA_REL_ "GenSigTimeoutTime" BU_SG_REL_ Kombi SG_ 1012 DC_Verbrauch_Ueberlauf 500;
BA_REL_ "GenSigTimeoutTime" BU_SG_REL_ Kombi SG_ 1163 BEM_06_BZ 1000;
BA_REL_ "GenSigTimeoutTime" BU_SG_REL_ Kombi SG_ 1163 BEM_06_CRC 1000;
BA_REL_ "GenSigTimeoutTime" BU_SG_REL_ Kombi SG_ 1163 NVEM_Bordnetzdiagnose 1000;
BA_REL_ "GenSigTimeoutTime" BU_SG_REL_ Kombi SG_ 1482 BMS_KundenWarnung 5000;
BA_REL_ "GenSigTimeoutTime" BU_SG_REL_ Kombi SG_ 1626 BCM1_MH_Schalter 5000;
BA_REL_ "GenSigTimeoutTime" BU_SG_REL_ Kombi SG_ 1626 BCM_Bremsbelag_Sensor 5000;
BA_REL_ "GenSigTimeoutTime" BU_SG_REL_ Kombi SG_ 1626 BCM_Bremsfluessigkeit_Sensor 5000;
BA_REL_ "GenSigTimeoutTime" BU_SG_REL_ Kombi SG_ 1626 BCM_Kuehlmittel_Sensor 5000;
BA_REL_ "GenSigTimeoutTime" BU_SG_REL_ Kombi SG_ 1626 BCM_Waschwasser_Sensor 5000;
BA_REL_ "GenSigTimeoutTime" BU_SG_REL_ Kombi SG_ 1635 BEM_Batteriediagnose 1000;
BA_REL_ "GenSigTimeoutTime" BU_SG_REL_ Kombi SG_ 1635 BEM_Generatordiagnose 1000;
BA_REL_ "GenSigTimeoutTime" BU_SG_REL_ Kombi SG_ 1635 BEM_Ladezustand 1000;
BA_REL_ "GenSigTimeoutTime" BU_SG_REL_ Kombi SG_ 1635 NVEM_Abschaltstufe 1000;
BA_REL_ "GenSigTimeoutTime" BU_SG_REL_ Kombi SG_ 1635 NVEM_Batterie_Service 1000;
BA_REL_ "GenSigTimeoutTime" BU_SG_REL_ Kombi SG_ 1635 NVEM_Verbraucherabsch_Anz 1000;
BA_REL_ "GenSigTimeoutTime" BU_SG_REL_ Kombi SG_ 1714 DGN_Verlernzaehler 5000;
BA_REL_ "GenSigTimeoutTime" BU_SG_REL_ Kombi SG_ 1714 KBI_Kilometerstand 5000;
BA_REL_ "GenSigTimeoutTime" BU_SG_REL_ Kombi SG_ 1714 UH_Jahr 5000;
BA_REL_ "GenSigTimeoutTime" BU_SG_REL_ Kombi SG_ 1714 UH_Minute 5000;
BA_REL_ "GenSigTimeoutTime" BU_SG_REL_ Kombi SG_ 1714 UH_Monat 5000;
BA_REL_ "GenSigTimeoutTime" BU_SG_REL_ Kombi SG_ 1714 UH_Sekunde 5000;
BA_REL_ "GenSigTimeoutTime" BU_SG_REL_ Kombi SG_ 1714 UH_Stunde 5000;
BA_REL_ "GenSigTimeoutTime" BU_SG_REL_ Kombi SG_ 1714 UH_Tag 5000;
BA_REL_ "GenSigTimeoutTime" BU_SG_REL_ Kombi SG_ 2527679637 BCM_LTM_Allwetterl_Status 5000;
BA_REL_ "GenSigTimeoutTime" BU_SG_REL_ Kombi SG_ 2527679637 BCM_LTM_Nebell_Status 5000;
BA_REL_ "GenSigTimeoutTime" BU_SG_REL_ Kombi SG_ 2527679637 BCM_LTM_Nebelschluss_Status 5000;
BA_REL_ "GenSigTimeoutTime" BU_SG_REL_ Kombi SG_ 2527679637 BCM_LTM_PopUp_Anf 5000;
BA_REL_ "GenSigTimeoutTime" BU_SG_REL_ Kombi SG_ 2527679637 BCM_LTM_PopUp_Inhalt 5000;
BA_REL_ "GenSigTimeoutTime" BU_SG_REL_ Kombi SG_ 2527679637 BCM_LTM_PopUp_Status 5000;
BA_REL_ "GenSigTimeoutTime" BU_SG_REL_ Kombi SG_ 2527679637 CPD_Warnung 5000;
BA_REL_ "GenSigTimeoutTime" BU_SG_REL_ Kombi SG_ 2536706560 BAP_SIA_ASG_01_Header 800;
BA_REL_ "GenSigTimeoutTime" BU_SG_REL_ Kombi SG_ 2536710416 BAP_VZA_FSG_01_Header 5000;
BA_REL_ "GenSigTimeoutTime" BU_SG_REL_ Kombi SG_ 2536712208 BAP_Telefon_FSG_01_Header 5000;
BA_REL_ "GenSigTimeoutTime" BU_SG_REL_ Kombi SG_ 2536712209 BAP_Telefon_FSG_02_Header 5000;
BA_REL_ "GenSigTimeoutTime" BU_SG_REL_ Kombi SG_ 2536712464 BAP_Telefon2_FSG_01_Header 5000;
BA_REL_ "GenSigTimeoutTime" BU_SG_REL_ Kombi SG_ 2536712465 BAP_Telefon2_FSG_02_Header 5000;
BA_REL_ "GenSigTimeoutTime" BU_SG_REL_ Kombi SG_ 2536712720 BAP_OnlineFunction_FSG_01_Header 5000;
BA_REL_ "GenSigTimeoutTime" BU_SG_REL_ Kombi SG_ 2536714768 BAP_Navigation_FSG_01_Header 5000;
BA_REL_ "GenSigTimeoutTime" BU_SG_REL_ Kombi SG_ 2536714769 BAP_Navigation_FSG_02_Header 5000;
BA_REL_ "GenSigTimeoutTime" BU_SG_REL_ Kombi SG_ 2536715280 BAP_MFL_FSG_01_Header 5000;
BA_REL_ "GenSigTimeoutTime" BU_SG_REL_ Kombi SG_ 2536723728 BAP_PaCo_FSG_01_Header 5000;
BA_REL_ "GenSigTimeoutTime" BU_SG_REL_ SmartLight_01 SG_ 1635 NVEM_Abschaltstufe 1000;
BA_REL_ "GenSigTimeoutTime" BU_SG_REL_ SmartLight_01 SG_ 1714 DGN_Verlernzaehler 5000;
BA_REL_ "GenSigTimeoutTime" BU_SG_REL_ SmartLight_01 SG_ 1714 KBI_Kilometerstand 5000;
BA_REL_ "GenSigTimeoutTime" BU_SG_REL_ SmartLight_01 SG_ 1714 UH_Jahr 5000;
BA_REL_ "GenSigTimeoutTime" BU_SG_REL_ SmartLight_01 SG_ 1714 UH_Minute 5000;
BA_REL_ "GenSigTimeoutTime" BU_SG_REL_ SmartLight_01 SG_ 1714 UH_Monat 5000;
BA_REL_ "GenSigTimeoutTime" BU_SG_REL_ SmartLight_01 SG_ 1714 UH_Sekunde 5000;
BA_REL_ "GenSigTimeoutTime" BU_SG_REL_ SmartLight_01 SG_ 1714 UH_Stunde 5000;
BA_REL_ "GenSigTimeoutTime" BU_SG_REL_ SmartLight_01 SG_ 1714 UH_Tag 5000;
BA_REL_ "GenSigTimeoutTime" BU_SG_REL_ ZR_MIB_TOP_ab_Gen3 SG_ 870 BM_Autobahn 5000;
BA_REL_ "GenSigTimeoutTime" BU_SG_REL_ ZR_MIB_TOP_ab_Gen3 SG_ 870 Blinken_li_Kombi_Takt 5000;
BA_REL_ "GenSigTimeoutTime" BU_SG_REL_ ZR_MIB_TOP_ab_Gen3 SG_ 870 Blinken_re_Kombi_Takt 5000;
BA_REL_ "GenSigTimeoutTime" BU_SG_REL_ ZR_MIB_TOP_ab_Gen3 SG_ 1432 FAS_Profile_Taster 5000;
BA_REL_ "GenSigTimeoutTime" BU_SG_REL_ ZR_MIB_TOP_ab_Gen3 SG_ 1432 LINDa_Touch_Event 5000;
BA_REL_ "GenSigTimeoutTime" BU_SG_REL_ ZR_MIB_TOP_ab_Gen3 SG_ 1626 BCM1_MH_Schalter 5000;
BA_REL_ "GenSigTimeoutTime" BU_SG_REL_ ZR_MIB_TOP_ab_Gen3 SG_ 1635 BEM_MMI_Vorwarnung 1000;
BA_REL_ "GenSigTimeoutTime" BU_SG_REL_ ZR_MIB_TOP_ab_Gen3 SG_ 1635 BEM_UBDM 1000;
BA_REL_ "GenSigTimeoutTime" BU_SG_REL_ ZR_MIB_TOP_ab_Gen3 SG_ 1635 NVEM_Abschaltstufe 1000;
BA_REL_ "GenSigTimeoutTime" BU_SG_REL_ ZR_MIB_TOP_ab_Gen3 SG_ 1635 NVEM_Freigabe_OnlineUpdate 1000;
BA_REL_ "GenSigTimeoutTime" BU_SG_REL_ ZR_MIB_TOP_ab_Gen3 SG_ 1714 DGN_Verlernzaehler 5000;
BA_REL_ "GenSigTimeoutTime" BU_SG_REL_ ZR_MIB_TOP_ab_Gen3 SG_ 1714 KBI_Kilometerstand 5000;
BA_REL_ "GenSigTimeoutTime" BU_SG_REL_ ZR_MIB_TOP_ab_Gen3 SG_ 1714 UH_Jahr 5000;
BA_REL_ "GenSigTimeoutTime" BU_SG_REL_ ZR_MIB_TOP_ab_Gen3 SG_ 1714 UH_Minute 5000;
BA_REL_ "GenSigTimeoutTime" BU_SG_REL_ ZR_MIB_TOP_ab_Gen3 SG_ 1714 UH_Monat 5000;
BA_REL_ "GenSigTimeoutTime" BU_SG_REL_ ZR_MIB_TOP_ab_Gen3 SG_ 1714 UH_Sekunde 5000;
BA_REL_ "GenSigTimeoutTime" BU_SG_REL_ ZR_MIB_TOP_ab_Gen3 SG_ 1714 UH_Stunde 5000;
BA_REL_ "GenSigTimeoutTime" BU_SG_REL_ ZR_MIB_TOP_ab_Gen3 SG_ 1714 UH_Tag 5000;
BA_REL_ "GenSigTimeoutTime" BU_SG_REL_ ZR_MIB_TOP_ab_Gen3 SG_ 1714 Vehicle_Driving_Cycle 5000;
BA_REL_ "GenSigTimeoutTime" BU_SG_REL_ ZR_MIB_TOP_ab_Gen3 SG_ 2463978607 BCM_RGB_Blau 2000;
BA_REL_ "GenSigTimeoutTime" BU_SG_REL_ ZR_MIB_TOP_ab_Gen3 SG_ 2463978607 BCM_RGB_Gruen 2000;
BA_REL_ "GenSigTimeoutTime" BU_SG_REL_ ZR_MIB_TOP_ab_Gen3 SG_ 2463978607 BCM_RGB_Rot 2000;
BA_REL_ "GenSigTimeoutTime" BU_SG_REL_ ZR_MIB_TOP_ab_Gen3 SG_ 2527679781 LINDa_HL_SR3_Touch_Event 5000;
BA_REL_ "GenSigTimeoutTime" BU_SG_REL_ ZR_MIB_TOP_ab_Gen3 SG_ 2527679781 LINDa_HL_Touch_Event 5000;
BA_REL_ "GenSigTimeoutTime" BU_SG_REL_ ZR_MIB_TOP_ab_Gen3 SG_ 2527679781 LINDa_HR_SR3_Touch_Event 5000;
BA_REL_ "GenSigTimeoutTime" BU_SG_REL_ ZR_MIB_TOP_ab_Gen3 SG_ 2527679781 LINDa_HR_Touch_Event 5000;
BA_REL_ "GenSigTimeoutTime" BU_SG_REL_ ZR_MIB_TOP_ab_Gen3 SG_ 2536702224 BAP_Klima1_FSG_01_Header 5000;
BA_REL_ "GenSigTimeoutTime" BU_SG_REL_ ZR_MIB_TOP_ab_Gen3 SG_ 2536702480 BAP_Klima2_FSG_01_Header 5000;
BA_REL_ "GenSigTimeoutTime" BU_SG_REL_ ZR_MIB_TOP_ab_Gen3 SG_ 2536702736 BAP_ParkHeater_FSG_01_Header 5000;
BA_REL_ "GenSigTimeoutTime" BU_SG_REL_ ZR_MIB_TOP_ab_Gen3 SG_ 2536703760 BAP_RDK_FSG_01_Header 5000;
BA_REL_ "GenSigTimeoutTime" BU_SG_REL_ ZR_MIB_TOP_ab_Gen3 SG_ 2536704016 BAP_Innenlicht_FSG_01_Header 5000;
BA_REL_ "GenSigTimeoutTime" BU_SG_REL_ ZR_MIB_TOP_ab_Gen3 SG_ 2536704528 BAP_OPS_FSG_01_Header 5000;
BA_REL_ "GenSigTimeoutTime" BU_SG_REL_ ZR_MIB_TOP_ab_Gen3 SG_ 2536704529 BAP_OPS_FSG_02_Header 5000;
BA_REL_ "GenSigTimeoutTime" BU_SG_REL_ ZR_MIB_TOP_ab_Gen3 SG_ 2536704784 BAP_RVC_FSG_01_Header 5000;
BA_REL_ "GenSigTimeoutTime" BU_SG_REL_ ZR_MIB_TOP_ab_Gen3 SG_ 2536705040 BAP_Wiper_FSG_01_Header 5000;
BA_REL_ "GenSigTimeoutTime" BU_SG_REL_ ZR_MIB_TOP_ab_Gen3 SG_ 2536705552 BAP_Mirror_FSG_01_Header 5000;
BA_REL_ "GenSigTimeoutTime" BU_SG_REL_ ZR_MIB_TOP_ab_Gen3 SG_ 2536706064 BAP_Sitz1_FSG_01_Header 5000;
BA_REL_ "GenSigTimeoutTime" BU_SG_REL_ ZR_MIB_TOP_ab_Gen3 SG_ 2536706576 BAP_SIA_FSG_01_Header 5000;
BA_REL_ "GenSigTimeoutTime" BU_SG_REL_ ZR_MIB_TOP_ab_Gen3 SG_ 2536707088 BAP_Homelink_FSG_01_Header 5000;
BA_REL_ "GenSigTimeoutTime" BU_SG_REL_ ZR_MIB_TOP_ab_Gen3 SG_ 2536708368 BAP_LDW_FSG_01_Header 5000;
BA_REL_ "GenSigTimeoutTime" BU_SG_REL_ ZR_MIB_TOP_ab_Gen3 SG_ 2536708624 BAP_SWA_FSG_01_Header 5000;
BA_REL_ "GenSigTimeoutTime" BU_SG_REL_ ZR_MIB_TOP_ab_Gen3 SG_ 2536710160 BAP_Sitz2_FSG_01_Header 5000;
BA_REL_ "GenSigTimeoutTime" BU_SG_REL_ ZR_MIB_TOP_ab_Gen3 SG_ 2536710416 BAP_VZA_FSG_01_Header 5000;
BA_REL_ "GenSigTimeoutTime" BU_SG_REL_ ZR_MIB_TOP_ab_Gen3 SG_ 2536710672 BAP_MKE_FSG_01_Header 5000;
BA_REL_ "GenSigTimeoutTime" BU_SG_REL_ ZR_MIB_TOP_ab_Gen3 SG_ 2536712192 BAP_Telefon_ASG_01_Header 500;
BA_REL_ "GenSigTimeoutTime" BU_SG_REL_ ZR_MIB_TOP_ab_Gen3 SG_ 2536712193 BAP_Telefon_ASG_02_Header 500;
BA_REL_ "GenSigTimeoutTime" BU_SG_REL_ ZR_MIB_TOP_ab_Gen3 SG_ 2536712448 BAP_Telefon2_ASG_01_Header 800;
BA_REL_ "GenSigTimeoutTime" BU_SG_REL_ ZR_MIB_TOP_ab_Gen3 SG_ 2536712704 BAP_OnlineFunction_ASG_01_Header 800;
BA_REL_ "GenSigTimeoutTime" BU_SG_REL_ ZR_MIB_TOP_ab_Gen3 SG_ 2536714752 BAP_Navigation_ASG_01_Header 500;
BA_REL_ "GenSigTimeoutTime" BU_SG_REL_ ZR_MIB_TOP_ab_Gen3 SG_ 2536714753 BAP_Navigation_ASG_02_Header 500;
BA_REL_ "GenSigTimeoutTime" BU_SG_REL_ ZR_MIB_TOP_ab_Gen3 SG_ 2536715264 BAP_MFL_ASG_01_Header 800;
BA_REL_ "GenSigTimeoutTime" BU_SG_REL_ ZR_MIB_TOP_ab_Gen3 SG_ 2536715792 BAP_TrailerAssist_FSG_01_Header 5000;
BA_REL_ "GenSigTimeoutTime" BU_SG_REL_ ZR_MIB_TOP_ab_Gen3 SG_ 2536717072 BAP_SeatPneumatic_FSG_01_Header 5000;
BA_REL_ "GenSigTimeoutTime" BU_SG_REL_ ZR_MIB_TOP_ab_Gen3 SG_ 2536718864 BAP_KlimaMaster_FSG_01_Header 5000;
BA_REL_ "GenSigTimeoutTime" BU_SG_REL_ ZR_MIB_TOP_ab_Gen3 SG_ 2536721936 BAP_RemoteServices_FSG_01_Header 5000;
BA_REL_ "GenSigTimeoutTime" BU_SG_REL_ ZR_MIB_TOP_ab_Gen3 SG_ 2536722434 BAP_InfoSettings_ASG_03_Header 500;
BA_REL_ "GenSigTimeoutTime" BU_SG_REL_ ZR_MIB_TOP_ab_Gen3 SG_ 2536722960 BAP_IAA_PSO_FSG_01_Header 5000;
BA_REL_ "GenSigTimeoutTime" BU_SG_REL_ ZR_MIB_TOP_ab_Gen3 SG_ 2536723728 BAP_PaCo_FSG_01_Header 5000;
BA_REL_ "GenSigTimeoutTime" BU_SG_REL_ ZR_MIB_TOP_ab_Gen3 SG_ 2536729104 BAP_Innenlicht2_FSG_01_Header 5000;
VAL_ 1626 APS_Tongeber_defekt 0 "iO" 1 "defekt" ;
VAL_ 1626 BCM1_AFS_Lampe 0 "Aus" 1 "Ein" ;
VAL_ 1626 BCM1_EasyEntry_Status 0 "Aus" 1 "Ein" ;
VAL_ 1626 BCM1_Kl_15_HW_erkannt 1 "Klemme 15 erkannt" ;
VAL_ 1626 BCM1_Kl_15_Sig_HW_erkannt 0 "KL15_HW_Signal_von_BCM1_nicht_erkannt" 1 "KL15_HW_Signal_von_BCM1_erkannt" ;
VAL_ 1626 BCM1_Lenksaeule_aktiv 0 "Lenksaeulenverstellung nicht aktiv" 1 "Lenksaeulenverstellung aktiv" ;
VAL_ 1626 BCM1_MH_Schalter 0 "MH_geschlossen" 1 "MH_offen" ;
VAL_ 1626 BCM1_MH_WIV_Schalter 0 "MH_geschlossen" 1 "MH_offen" ;
VAL_ 1626 BCM1_NV_Taster 0 "Taster_nicht_betaetigt" 1 "Taster_betaetigt" ;
VAL_ 1626 BCM1_Reisemodus_Texte 0 "keine_Anzeige" 1 "Umschaltung_auf_Linksverkehr_aktiv" 2 "Umschaltung_auf_Rechtsverkehr_aktiv" ;
VAL_ 1626 BCM1_Rueckfahrlicht_Schalter 0 "nicht_betaetigt" 1 "betaetigt" ;
VAL_ 1626 BCM1_Spannungs_Anf 0 "keine_Anforderung" 1 "Anforderung_Stufe_1" 2 "Anforderung_Stufe_2" 3 "Anforderung_Stufe_3" ;
VAL_ 1626 BCM1_Valet_Parking_Taster 0 "nicht_betaetigt" 1 "betaetigt" ;
VAL_ 1626 BCM1_Warnblink_Taster 0 "nicht_betaetigt" 1 "betaetigt" ;
VAL_ 1626 BCM_Anf_AAW_MoLaWa 0 "Init" 1 "AAW_angefordert" 2 "MoLaWa_angefordert" ;
VAL_ 1626 BCM_Bremsbelag_Sensor 0 "OK" 1 "Bremsbelag_unter_min" ;
VAL_ 1626 BCM_Bremsfluessigkeit_Sensor 0 "OK" 1 "Bremsfluessigkeit_unter_min" ;
VAL_ 1626 BCM_Charisma_Taste2 0 "nicht_betaetigt" 1 "betaetigt" ;
VAL_ 1626 BCM_Eco_Charisma_Taste 0 "nicht_betaetigt" 1 "betaetigt" ;
VAL_ 1626 BCM_Handbremse_Hinweis 0 "inaktiv" 1 "aktiv" ;
VAL_ 1626 BCM_HDF_betaetigt 0 "nicht_betaetigt" 1 "betaetigt" ;
VAL_ 1626 BCM_Hybrid_StartStopp_Taste 0 "nicht_betaetigt" 1 "betaetigt" ;
VAL_ 1626 BCM_Hybrid_StSt_Taste_Fehler 0 "kein_Fehler_StSt_Taster" 1 "Fehler_StSt_Taster" ;
VAL_ 1626 BCM_Kuehlmittel_Sensor 0 "OK" 1 "Kuehlmittel_unter_min" ;
VAL_ 1626 BCM_Kuehlmittel_Sensor_02 0 "OK" 1 "Kuehlmittel_unter_min" ;
VAL_ 1626 BCM_Offroad_Taste 0 "Taster_nicht_betaetigt" 1 "Taster_betaetigt" ;
VAL_ 1626 BCM_ValetTaster_Fkts_LED 0 "LED_aus" 1 "LED_ein" ;
VAL_ 1626 BCM_Waschwasser_Sensor 0 "OK" 1 "Waschwasser_unter_min" ;
VAL_ 1626 Gong_TFL_Umschaltung 0 "kein_Gong" 1 "Gong_einmalig" ;
VAL_ 1626 LRH_Taster 0 "nicht_betaetigt" 1 "betaetigt" ;
VAL_ 2527679637 BCM_anf_VLW 0 "Init" 1 "VLW_angefordert_VLK2_1" 2 "deg_VLW_FT_angefordert" 3 "deg_VLW_Werkstatt_angefordert" 4 "VLW_angefordert_VLK2_2" 5 "Wegrollwarnung_angefordert" 6 "Rollfaehigkeit_ohne_Akustik" 7 "Rollfaehigkeit_mit_Akustik" ;
VAL_ 2527679637 BCM_LTM_Allwetterl_Status 0 "nicht_aktiv" 1 "aktiv" ;
VAL_ 2527679637 BCM_LTM_Nebell_Status 0 "nicht_aktiv" 1 "aktiv" ;
VAL_ 2527679637 BCM_LTM_Nebelschluss_Status 0 "nicht_aktiv" 1 "aktiv" ;
VAL_ 2527679637 BCM_LTM_PopUp_Anf 0 "keine_Anforderung" 1 "Licht_PopUp" 2 "Nebellicht_PopUp" 3 "Allwetterlicht_PopUp" 4 "Nebelschlusslicht_PopUp" ;
VAL_ 2527679637 BCM_LTM_PopUp_Inhalt 0 "Init" 1 "AUTO" 2 "Abblendlicht" 4 "Standlicht" 8 "OFF" ;
VAL_ 2527679637 BCM_LTM_PopUp_Status 0 "Init" 1 "AUTO" 2 "Abblendlicht" 3 "Standlicht" 4 "OFF" ;
VAL_ 2527679637 BCM_LTM_PopUp_Texte 0 "keine_Anzeige" 1 "Ausschalt_Hinweis" 2 "Ausschalt_Quittierung" ;
VAL_ 2527679637 CPD_Warnung 0 "keine_Warnung" 1 "Warnung_mit_Ton" 2 "Warnung_ohne_Ton" ;
VAL_ 2463978607 BCM_RGB_Dimmzeit_Zeitbasis 0 "Zeitbasis_50ms" 1 "Zeitbasis_250ms" ;
VAL_ 2463978607 BCM_RGB_Intensitaet 126 "Init" 127 "Fehler" ;
VAL_ 2463978607 BCM_RGB_Normierung_Intensitaet 0 "ohne Normierung" 1 "Normierung der Intensitï?½t" ;
VAL_ 1432 BCM_BFS_Massage_Taster 0 "Taster_unbetaetigt" 1 "Taster_betaetigt" ;
VAL_ 1432 BCM_BFS_Multif_Taster 0 "Taster_unbetaetigt" 1 "Taster_betaetigt" ;
VAL_ 1432 BCM_BFS_Pneumatik_Verstellung 0 "keine_Verstellung" 1 "Pneumatikverstellung_aktiv" ;
VAL_ 1432 BCM_BFS_Programmwippe 0 "Taster_unbetaetigt" 1 "Taster_betaetigt" ;
VAL_ 1432 BCM_FS_Massage_Taster 0 "Taster_unbetaetigt" 1 "Taster_betaetigt" ;
VAL_ 1432 BCM_FS_Multif_Taster 0 "Taster_unbetaetigt" 1 "Taster_betaetigt" ;
VAL_ 1432 BCM_FS_Pneumatik_Verstellung 0 "keine_Verstellung" 1 "Pneumatikverstellung_aktiv" ;
VAL_ 1432 BCM_FS_Programmwippe 0 "Taster_unbetaetigt" 1 "Taster_betaetigt" ;
VAL_ 1432 FAS_Profile_Taster 0 "Taste_nicht_betaetigt" 1 "Taste_entprellt_betaetigt" 2 "Init_oder_nicht_verbaut" 3 "Fehler" ;
VAL_ 1432 LIM_bCall_Taster 0 "nicht_betaetigt" 1 "betaetigt" ;
VAL_ 1432 LIM_iCall_Taster 0 "nicht_betaetigt" 1 "betaetigt" ;
VAL_ 1432 LIM_S_Rollo_hi 0 "nicht_betaetigt" 1 "man_zu" 2 "auto_zu" 3 "man_auf" 4 "auto_auf" 5 "stop" 6 "fehler_schalter_haengt" 7 "fehler_schalter_unplausibel" ;
VAL_ 1432 LIM_S_Rollo_vo 0 "nicht_betaetigt" 1 "man_zu" 2 "auto_zu" 3 "man_auf" 4 "auto_auf" 5 "stop" 6 "fehler_schalter_haengt" 7 "fehler_schalter_unplausibel" ;
VAL_ 1432 LIM_S_SAD_hi 0 "nicht_betaetigt" 1 "man_sl_zu" 2 "auto_sl_zu" 3 "man_sl_auf" 4 "auto_sl_auf" 5 "man_al_auf" 6 "auto_al_auf" 7 "man_al_zu" 8 "auto_al_zu" 14 "fehler_schalter_haengt" 15 "fehler_schalter_unplausibel" ;
VAL_ 1432 LIM_S_SAD_Vo 0 "nicht_betaetigt" 1 "man_sl_zu" 2 "auto_sl_zu" 3 "man_sl_auf" 4 "auto_sl_auf" 5 "man_al_auf" 6 "auto_al_auf" 7 "man_al_zu" 8 "auto_al_zu" 9 "stop" 10 "Toggle_Taster_AL_betaetigt" 14 "fehler_schalter_haengt" 15 "fehler_schalter_unplausibel" ;
VAL_ 1432 LINDa_Touch_Event 0 "nicht_betaetigt" 1 "Tippen" 2 "Wischen_Slide" 3 "Geste" 4 "Doppeltippen" 5 "Longpress_1" 6 "Longpress_2" 7 "Longpress_3" 8 "Press" 9 "Strongpress" 10 "reserviert" 11 "reserviert" 12 "reserviert" 13 "reserviert" 14 "Taktgeber_Inkrement" 15 "Fehler" ;
VAL_ 1432 Tuerkontakt_Innenlicht_Taste 0 "Taste_unbetaetigt" 1 "Taste_betaetigt" ;
VAL_ 2527679781 LINDa_HL_SR3_Touch_Event 0 "nicht_betaetigt" 1 "Tippen" 2 "Wischen_Slide" 3 "Geste" 4 "Doppeltippen" 5 "Longpress_1" 6 "Longpress_2" 7 "Longpress_3" 8 "Press" 9 "Strongpress" 10 "reserviert" 11 "reserviert" 12 "reserviert" 13 "reserviert" 14 "Taktgeber_Inkrement" 15 "Fehler" ;
VAL_ 2527679781 LINDa_HL_Touch_Event 0 "nicht_betaetigt" 1 "Tippen" 2 "Wischen_Slide" 3 "Geste" 4 "Doppeltippen" 5 "Longpress_1" 6 "Longpress_2" 7 "Longpress_3" 8 "Press" 9 "Strongpress" 10 "reserviert" 11 "reserviert" 12 "reserviert" 13 "reserviert" 14 "Taktgeber_Inkrement" 15 "Fehler" ;
VAL_ 2527679781 LINDa_HR_SR3_Touch_Event 0 "nicht_betaetigt" 1 "Tippen" 2 "Wischen_Slide" 3 "Geste" 4 "Doppeltippen" 5 "Longpress_1" 6 "Longpress_2" 7 "Longpress_3" 8 "Press" 9 "Strongpress" 10 "reserviert" 11 "reserviert" 12 "reserviert" 13 "reserviert" 14 "Taktgeber_Inkrement" 15 "Fehler" ;
VAL_ 2527679781 LINDa_HR_Touch_Event 0 "nicht_betaetigt" 1 "Tippen" 2 "Wischen_Slide" 3 "Geste" 4 "Doppeltippen" 5 "Longpress_1" 6 "Longpress_2" 7 "Longpress_3" 8 "Press" 9 "Strongpress" 10 "reserviert" 11 "reserviert" 12 "reserviert" 13 "reserviert" 14 "Taktgeber_Inkrement" 15 "Fehler" ;
VAL_ 1635 BEM_Anf_KL15_schalten 0 "Keine_Einschraenkung_Kl15" 1 "Empfehlung_auto_Abschaltung_Kl15" 2 "Veto_auto_Abschaltung_Kl15" 3 "Veto_auto_Abschaltung_Fahrtbetrieb" ;
VAL_ 1635 BEM_Batt_Ab 0 "verbunden" 1 "nicht_verbunden" ;
VAL_ 1635 BEM_Batteriediagnose 0 "keine_Anzeige" 1 "nicht_belegt" 2 "Anzeige_aberkannte_Batterie" 3 "Anzeige_schwache_Batterie" 4 "Anzeige_Batterie_OK" 5 "Anzeige_Batterie_Laden" 6 "Anzeige_Batterie_Pruefen" 7 "Fehler" ;
VAL_ 1635 BEM_EMLIN_ungueltig 0 "Signale_gueltig" 1 "Signale_ungueltig" ;
VAL_ 1635 BEM_Generatordiagnose 0 "keine Anzeige" 1 "Ladekontrollanzeige ein (Vorhalt)" 2 "rotes Batteriesymbol und Text (Generator defekt)" 3 "Hybrid_DCDC_Wandler_defekt" ;
VAL_ 1635 BEM_HL_Regelung_Status 0 "HL_Regelung_inaktiv_(vor_und_waehrend_Motorstart)" 1 "HL_Regelung_Stufe_1" 2 "HL_Regelung_Stufe_2" 3 "HL_Regelung_Stufe_3" 4 "Verbrauchernotabschaltung_(VNA)" 5 "HL_Regelung_Stufe_5" 7 "Default" ;
VAL_ 1635 BEM_Ladezustand 14 "Init" 15 "Fehler" ;
VAL_ 1635 BEM_MMI_Vorwarnung 0 "keine Anzeige" 1 "Anzeige MMI-Vorwarnung" ;
VAL_ 1635 BEM_Red_Innengeblaese 0 "keine Reduzierung" 1 "Reduzierung Stufe 1" 2 "Reduzierung Stufe 2" 3 "Reduzierung Stufe 2 und Abschaltung Kompressor" ;
VAL_ 1635 BEM_REK_aktiv 0 "keine_Rekuperationsfreigabe" 1 "Rekuperationsfreigabe" ;
VAL_ 1635 BEM_STH_Einschaltverbot 0 "volle Verfuegbarkeit Standheizung/-lueftung" 1 "Standheizung/-lueftung nicht aktivierbar" ;
VAL_ 1635 BEM_STH_Zielzeit 14 "Init" 15 "Fehler" ;
VAL_ 1635 BEM_UBDM 0 "Init" 255 "Fehler" ;
VAL_ 1635 MIB_Stromsparmodus 0 "inaktiv" 1 "aktiv" ;
VAL_ 1635 NVEM_Abschaltstufe 0 "Stufe_0_keine_Einschraenkung" 1 "Stufe_1" 2 "Stufe_2" 3 "Stufe_3" ;
VAL_ 1635 NVEM_Anf_SD_schalten 0 "Anf_SD_Nachlauf_nicht_aktiv" 1 "Anf_SD_Nachlauf_aktiv" ;
VAL_ 1635 NVEM_Batterie_Service 0 "kein_Service" 1 "Service_Information1" 2 "Service_Information2" 3 "Service_Information3" ;
VAL_ 1635 NVEM_Freigabe_OnlineUpdate 0 "keine_Freigabe" 1 "Freigabe" ;
VAL_ 1635 NVEM_Freigabe_ORU4 0 "Init" 1 "keine_Freigabe" 2 "Freigabe_erteilt" 3 "Veto_Freigabe" ;
VAL_ 1635 NVEM_Freigabe_ZusBatt_Laden 0 "keine_Freigabe_Laderelais" 1 "Freigabe_Laderelais_schliessen" ;
VAL_ 1635 NVEM_Verbraucherabsch_Anz 0 "keine_Anzeige" 1 "Anzeige_aktiv" ;
VAL_ 1163 HLR_PTC_linear_Freigabe 63 "Fehler" ;
VAL_ 1163 NVEM2_Status_FuSiFahrt 0 "Init" 1 "Keine_FuSi_Fahrt" 2 "Qualifikation_FuSi_Fahrt" 3 "FuSi_Fahrt_Aktiv" 4 "Qualifikation_Ende_FuSi_Fahrt" 5 "FuSi_Stand" 6 "FuSi_Nachlauf" 7 "Fehler" ;
VAL_ 1163 NVEM2_Typ_EnergieNetz 0 "Sp12V_Gen_ICE" 1 "Sp12V_BEV" 2 "Sp12V_PHEV" 3 "Sp12V_MHEV" 4 "Sp12V_HEV" 5 "Sp12V_Sp48V_Gen_Insel" 6 "Sp12V_Sp12V_RSG_MHEV12V" 7 "Sp12V_BEV_ASILC" 14 "Fehler" 15 "Init" ;
VAL_ 1163 NVEM_Betriebsart 0 "oKl15_Sing_oVerbr" 1 "oKl15_Red_RedKontingent_oVerbr" 2 "oKl15_Red_HohKontingent_oVerbr" 3 "oKl15_Red_mVerbr" 4 "reserved" 5 "reserved" 6 "reserved" 7 "reserved" 8 "mKl15_Sing_oVerbr" 9 "mKl15_Red_RedKontingent_oVerbr" 10 "mKl15_Red_HohKontingent_oVerbr" 11 "mKl15_Red_mVerbr" 12 "Fahrbereitschaft_mVerbr" 13 "reserved" 14 "reserved" 15 "Fehler" ;
VAL_ 1163 NVEM_Bordnetzdiagnose 0 "kein_Fehler" 1 "Warnung_1" 2 "Warnung_2" 3 "Warnung_3" ;
VAL_ 1163 NVEM_Energie_Klima_Vorgabe 254 "Init" 255 "Fehler" ;
VAL_ 1163 NVEM_Energienetz_Status 0 "QM" 1 "ASIL_A" 2 "ASIL_B" 6 "Init" 7 "Fehler" ;
VAL_ 1163 NVEM_Ladezustand 126 "INIT" 127 "Fehler" ;
VAL_ 1163 NVEM_Last_Anf 0 "keine Anforderung" 1 "Verbraucher_Anforderung_Stufe_1" 2 "Verbraucher_Anforderung_Stufe_2" 3 "Verbraucher_Anforderung_Stufe_3" ;
VAL_ 1163 NVEM_PTC_Sollstufe 0 "Aus" 1 "Stufe_1" 2 "Stufe_2" 3 "Stufe_3" ;
VAL_ 1163 NVEM_Red_KomfortVerbrauch 0 "keine_Einschraenkung" 1 "Einschraenkung_Stufe_1" 2 "Einschraenkung_Stufe_2" 3 "Einschraenkung_Stufe_3" 4 "Einschraenkung_Stufe_4" 5 "Einschraenkung_Stufe_5" 6 "Einschraenkung_Stufe_6" 7 "Einschraenkung_Stufe_7" 8 "Einschraenkung_Stufe_8" 15 "Fehler" ;
VAL_ 1163 NVEM_STH_ZielzeitLang 14 "Init" 15 "Fehler" ;
VAL_ 1163 NVEM_Vorgabe_Leistungsstufe 0 "Init" 1 "Leistungsstufe_0" 2 "Leistungsstufe_1" 3 "Leistungsstufe_2" 4 "Leistungsstufe_3" 5 "Leistungsstufe_4" 6 "Leistungsstufe_5" 7 "Fehler" ;
VAL_ 2463978850 NVEM2_VerbrZustandsAnf 0 "Freigabe" 1 "Verbraucher_Sperren" 2 "Verbr_Sperren_KL_Red" 3 "reserved" 4 "reserved" 5 "reserved" 6 "Verbr_Sperren_KL_Anf" 7 "Teilweise_Anschalt_Anf" 8 "Anschalt_Anf" 9 "reserved" 10 "reserved" 11 "Abschaltstufe_1" 12 "Abschaltstufe_2" 13 "Abschaltstufe_3" 14 "Init" 15 "Fehler" ;
VAL_ 2463978850 NVEM_Bordnetz_Information 0 "keine_Anzeige" 1 "NV_Batterie_iO" 2 "NV_Batterie_laden" 3 "NV_Batterie_pruefen" 4 "NV_Batterie_schwach" 5 "NV_Batterie_Ab" 6 "NV_Batterie_Service" 7 "NV_Energiesystem_unplausibel" 8 "Ladekontrollleuchte" 9 "Generator_defekt" 10 "reserviert" 11 "reserviert" 12 "reserviert" 13 "reserviert" 14 "Init" 15 "Fehler" ;
VAL_ 2463978850 NVEM_HVEM_FunktionsAnf 0 "keine_Anforderung" 1 "Autonomes_Nachladen" 2 "Autonomes_Nachladen_TRM" 3 "Standklimatisierung" 4 "TMM_Nachlauf" 5 "Vorlauf" 6 "ORU_Vorbereitung" 7 "PP_Vorbereitung" 8 "Nachlauf_Ausstieg" 9 "ORU" 255 "Fehler" ;
VAL_ 2463978850 NVEM_NVStuetzungAnf 0 "keine_Anforderung" 1 "Anforderung_sichere_Versorgung" 2 "Anforderung_Abschaltung" 3 "Fehler" ;
VAL_ 2463978850 NVEM_Verbraucher_Information 0 "Keine_Anzeige" 1 "MMI_Vorwarnung" 2 "Anzeige_Verbraucherabschaltung" 3 "reserviert" 4 "reserviert" 5 "reserviert" 6 "Init" 7 "Fehler" ;
VAL_ 870 Blinken_li_Fzg_Takt 0 "Blinker_links_ausgeschaltet" 1 "Blinker_links_eingeschaltet" ;
VAL_ 870 Blinken_li_Kombi_Takt 0 "Blinkerkontrolllampe_links_ausgeschaltet" 1 "Blinkerkontrolllampe_links_eingeschaltet" ;
VAL_ 870 Blinken_re_Fzg_Takt 0 "Blinker_rechts_ausgeschaltet" 1 "Blinker_rechts_eingeschaltet" ;
VAL_ 870 Blinken_re_Kombi_Takt 0 "Blinkerkontrolllampe_rechts_ausgeschaltet" 1 "Blinkerkontrolllampe_rechts_eingeschaltet" ;
VAL_ 870 BM_Autobahn 0 "inaktiv" 1 "aktiv" ;
VAL_ 870 BM_Crash 0 "inaktiv" 1 "aktiv" ;
VAL_ 870 BM_DWA_Alarm 0 "inaktiv" 1 "aktiv" ;
VAL_ 870 BM_DWA_ein 0 "inaktiv" 1 "aktiv" ;
VAL_ 870 BM_GDO 0 "inaktiv" 1 "aktiv" ;
VAL_ 870 BM_HD_Oeffnung_angelernt 0 "keine_Quittierung" 1 "Quittierung" ;
VAL_ 870 BM_links 0 "inaktiv" 1 "aktiv" ;
VAL_ 870 BM_NBA_n_codiert_n_aktiv 0 "codiert_AND_kein_Fehler" 1 "nicht_codiert_OR_Fehler_erkannt" ;
VAL_ 870 BM_NBA_Status 0 "NBA_nicht_aktiv" 1 "BRL_Dunkelphase" 3 "BRL_Hellphase" ;
VAL_ 870 BM_Not_Bremsung 0 "kein_blinken" 1 "Notbremswarnblinken_aktiv" ;
VAL_ 870 BM_Panik 0 "inaktiv" 1 "aktiv" ;
VAL_ 870 BM_PiloPa 0 "PiloPa_Blinkerquittierung_inaktiv" 1 "PiloPa_Blinkerquittierung_aktiv" ;
VAL_ 870 BM_Recas 0 "kein_blinken" 1 "Recasblinken_aktiv" ;
VAL_ 870 BM_rechts 0 "inaktiv" 1 "aktiv" ;
VAL_ 870 BM_Rollenmodus_Blinken 0 "inaktiv" 1 "aktiv" ;
VAL_ 870 BM_Taxi_Notalarm 0 "inaktiv" 1 "aktiv" ;
VAL_ 870 BM_Telematik 0 "inaktiv" 1 "aktiv" ;
VAL_ 870 BM_Telematik_Abbruchgrund 0 "Init" 1 "speed_out_of_range" 2 "defect" 3 "clamp_s_on" 4 "clamp_15_on" 5 "door_open" 6 "engine_hood_open" 7 "trunk_open" 8 "convertible_top_not_locked" 9 "horn_activated_by_user" 10 "Higher_Prioritiy_Function_active" 11 "Central_Lock_status_changed" 12 "Request_Dropped_by_Requester" 13 "Service_Duration_Expired" 14 "not_possible_due_to_coding" 15 "no_reason_or_unknown_timeout" ;
VAL_ 870 BM_Warnblinken 0 "inaktiv" 1 "aktiv" ;
VAL_ 870 BM_WBT_Beleuchtung 0 "inaktiv" 1 "aktiv" ;
VAL_ 870 BM_Wischblinken 0 "inaktiv" 1 "aktiv" ;
VAL_ 870 BM_ZV_auf 0 "inaktiv" 1 "aktiv" ;
VAL_ 870 BM_ZV_zu 0 "inaktiv" 1 "aktiv" ;
VAL_ 870 DWA_Alarmquelle 0 "kein_Ausloesegrund" 1 "Tuerkontakt_Fahrertuer" 2 "Tuerkontakt_Beifahrertuer" 3 "Tuerkontakt_hinten_links" 4 "Tuerkontakt_hinten_rechts" 5 "Motorhaubenkontakt_vorne" 6 "Kofferraum_hinten" 7 "Masseschleife_der_Heckscheibe" 8 "Innenraumueberwachung" 9 "Alarm_durch_Noteinstieg" 10 "Sounder" 11 "Neigungssensor" 12 "TSG_FT_am_CAN_Bus" 13 "TSG_BT_am_CAN_Bus" 14 "TSG_HFS_am_CAN_Bus" 15 "TSG_HBFS_am_CAN_Bus" 16 "Klemme_15" 17 "Klemme_15sig" 18 "frei" 19 "Anhaengerueberwachung" 20 "Scheinwerferueberwachung_links" 21 "Scheinwerferueberwachung_rechts" 22 "Handschuhkasten" 23 "Verdeckueberwachung" 24 "OBD_Alarm" 25 "Power_on_Reset" 30 "Init" 31 "Fehler" ;
VAL_ 870 SAL_TA_Blinken_Status 0 "init" 1 "nicht_bereit" 2 "bereit" 3 "aktiv_links" 4 "aktiv_rechts" ;
VAL_ 687 BMC_Spannung 16381 "Null_Bank" 16382 "Init" 16383 "Fehler" ;
VAL_ 687 BMS_As_Entladezaehler_Ueberlauf 0 "kein_Ueberlauf" 1 "Ueberlauf" ;
VAL_ 687 BMS_Rekuperation_Ueberlauf 0 "kein_Ueberlauf" 1 "Ueberlauf" ;
VAL_ 687 BMS_Verbrauch_Ueberlauf 0 "kein_Ueberlauf" 1 "Ueberlauf" ;
VAL_ 1482 BMS_Ausgleichsladung_Anf 1 "Balancing_Request" ;
VAL_ 1482 BMS_Batteriediagnose 1 "Anzeige_Batterie" 4 "Anzeige_Batterie_OK" 5 "Anzeige_Batterie_Laden" 6 "Anzeige_Batterie_Pruefen" 7 "Fehler" ;
VAL_ 1482 BMS_Energieinhalt 2046 "Init" 2047 "Fehler" ;
VAL_ 1482 BMS_Gesamtst_Spgfreiheit 0 "Funktion_nicht_aktiviert" 1 "HV_System_spannungsfrei" 2 "HV_System_nicht_spannungsfrei" 3 "Fehler_nicht_spannungsfrei" ;
VAL_ 1482 BMS_KundenWarnung 0 "keine_Warnung" 1 "Warnung_Temperatur_Level1" 2 "Warnung_Temperatur_Level2" ;
VAL_ 1482 BMS_MaxEnergieinhalt 2046 "Init" 2047 "Fehler" ;
VAL_ 903 EBKV_BKL_Warnungen 0 "i_O_System" 1 "Lampen_Pruefung" 2 "Ausfall_eBKV_und_HBV" ;
VAL_ 903 EBKV_Charisma_FahrPr 0 "keine_Funktion" 1 "Programm_1" 2 "Programm_2" 3 "Programm_3" 4 "Programm_4" 5 "Programm_5" 6 "Programm_6" 7 "Programm_7" 8 "Programm_8" 9 "Programm_9" 10 "Programm_10" 11 "Programm_11" 12 "Programm_12" 13 "Programm_13" 14 "Programm_14" 15 "Programm_15" ;
VAL_ 903 EBKV_Charisma_Status 0 "Init" 1 "verfuegbar" 2 "nicht_verfuegbar" 3 "asynchron_durch_Fahrerwunsch" ;
VAL_ 903 EBKV_Hinweise 0 "i_O_System" 1 "Werkstattdiagnose" 2 "Rollenmodes" 3 "Uebernahme_Feststellbremse" ;
VAL_ 903 EBKV_SpannungsAnf 0 "keine_Anforderung" 1 "Anforderung_Stufe_1" 2 "Anforderung_Stufe_2" 3 "Anforderung_Stufe_3" ;
VAL_ 903 EBKV_Warnungen 0 "i_O_System" 1 "Ausfall_2nd_Aktuator" 2 "Reduktion_Bremsverstaerkung" 3 "Ausfall_eBKV_ohne_HBV" 4 "Ausfall_Stillstandsmanagement" ;
VAL_ 903 EPB_Fehlermeldung_ext 0 "keine_Anzeige" 1 "Systemstoerung_Kl15an" 2 "Systemstoerung_Kl15aus" 3 "Parkbremse_betaetigen" 4 "Systemstoerung_Hanghaltefaehigkeit" 5 "Funktionseinschraenkung_Kl15an" 6 "Funktionseinschraenkung_Kl15aus" 7 "HU_Modus_aktiv" 8 "Transportmodus" 9 "Produktionsmodus" 10 "FktEinschr_Taster_defekt" 11 "Funktionseinschraenkung_Hanghalt" ;
VAL_ 903 EPB_Funktionslampe_ext 0 "Aus" 1 "Ein" ;
VAL_ 902 CHA_Charge_LED 0 "LED_aus" 1 "LED_ein" ;
VAL_ 902 CHA_Charisma_Taste2_LED 0 "LED_aus" 1 "LED_ein" 2 "LED_blinken" 3 "Fehler" ;
VAL_ 902 CHA_Current_Mode 0 "keine_Funktion" 1 "Programm_1" 2 "Programm_2" 3 "Programm_3" 4 "Programm_4" 5 "Programm_5" 6 "Programm_6" 7 "Programm_7" 8 "Programm_8" 9 "Programm_9" 10 "Programm_10" 11 "Programm_11" 12 "Programm_12" 13 "Programm_13" 14 "Programm_14" 15 "Programm_15" ;
VAL_ 902 CHA_Current_Mode_FPA 0 "keine_Funktion" 1 "Programm_1" 2 "Programm_2" 3 "Programm_3" 4 "Programm_4" 5 "Programm_5" 6 "Programm_6" 7 "Programm_7" 8 "Programm_8" 9 "Programm_9" 10 "Programm_10" 11 "Programm_11" 12 "Programm_12" 13 "Programm_13" 14 "Programm_14" 15 "Programm_15" 16 "Programm_16" 17 "Programm_17" 18 "Programm_18" 19 "Programm_19" 20 "Programm_20" 21 "Programm_21" 22 "Programm_22" 23 "Programm_23" 24 "Programm_24" 25 "Programm_25" 26 "Programm_26" 27 "Programm_27" 28 "Programm_28" 29 "Programm_29" 30 "Programm_30" 31 "Programm_31" 32 "Programm_32" ;
VAL_ 902 CHA_Eco_Charisma_LED 0 "LED_aus_und_Blinken_aus" 1 "LED_ein_und_Blinken_aus" 2 "LED_ein_und_Blinken_ein_50_percent" 3 "reserviert" ;
VAL_ 902 CHA_EV_LED 0 "LED_aus" 1 "LED_an" ;
VAL_ 902 CHA_Fahrer_Umschaltung 0 "keine_oder_automatische_Umschaltung" 1 "manuelle_Umschaltung" ;
VAL_ 902 CHA_Kombi_Texte 0 "keine_Anzeige" 1 "Text_1" 2 "Text_2" 3 "Text_3" 4 "Text_4" 5 "Text_5" 6 "Text_6" 7 "Text_7" 8 "Text_8" 9 "Text_9" 10 "Text_10" 11 "Text_11" 12 "Text_12" 13 "Text_13" 14 "Text_14" 15 "Text_15" ;
VAL_ 902 CHA_Kombi_Texte_02 0 "Init" 1 "Text_1" 2 "Text_2" 3 "Text_3" 4 "Text_4" 5 "Text_5" 6 "Text_6" 7 "Text_7" 8 "Text_8" 9 "Text_9" 10 "Text_10" 11 "Text_11" 12 "Text_12" 13 "Text_13" 14 "Text_14" 15 "Text_15" ;
VAL_ 902 CHA_Offroad_LED 0 "LED_aus" 1 "LED_ein" 2 "LED_blinken" 3 "Fehler" ;
VAL_ 902 CHA_ReqPrgDispSetup 0 "init" 1 "layout_comfort" 2 "layout_eco" 3 "layout_sport" 4 "layout_offroad" 5 "layout_sportplus" 6 "program_6" 7 "program_7" 8 "program_8" 9 "program_9" 10 "program_10" 11 "program_11" 12 "program_12" 13 "program_13" 14 "program_14" 15 "program_15" ;
VAL_ 902 CHA_StCurProfDft 0 "Init" 1 "profile_is_not_configurable" 2 "profile_is_default" 3 "profile_is_not_default" ;
VAL_ 902 CHA_Ziel_FahrPr_03_01 0 "keine_Funktion" 1 "Programm_1" 2 "Programm_2" 3 "Programm_3" 4 "Programm_4" 5 "Programm_5" 6 "Programm_6" 7 "Programm_7" 8 "Programm_8" 9 "Programm_9" 10 "Programm_10" 11 "Programm_11" 12 "Programm_12" 13 "Programm_13" 14 "Programm_14" 15 "Programm_15" ;
VAL_ 902 CHA_Ziel_FahrPr_03_02 0 "keine_Funktion" 1 "Programm_1" 2 "Programm_2" 3 "Programm_3" 4 "Programm_4" 5 "Programm_5" 6 "Programm_6" 7 "Programm_7" 8 "Programm_8" 9 "Programm_9" 10 "Programm_10" 11 "Programm_11" 12 "Programm_12" 13 "Programm_13" 14 "Programm_14" 15 "Programm_15" ;
VAL_ 902 CHA_Ziel_FahrPr_AMB 0 "keine_Funktion" 1 "Programm_1" 2 "Programm_2" 3 "Programm_3" 4 "Programm_4" 5 "Programm_5" 6 "Programm_6" 7 "Programm_7" 8 "Programm_8" 9 "Programm_9" 10 "Programm_10" 11 "Programm_11" 12 "Programm_12" 13 "Programm_13" 14 "Programm_14" 15 "Programm_15" ;
VAL_ 902 CHA_Ziel_FahrPr_HSP 0 "keine_Funktion" 1 "Programm_1" 2 "Programm_2" 3 "Programm_3" 4 "Programm_4" 5 "Programm_5" 6 "Programm_6" 7 "Programm_7" 8 "Programm_8" 9 "Programm_9" 10 "Programm_10" 11 "Programm_11" 12 "Programm_12" 13 "Programm_13" 14 "Programm_14" 15 "Programm_15" ;
VAL_ 902 CHA_Ziel_FahrPr_IVB 0 "keine_Funktion" 1 "Programm_1" 2 "Programm_2" 3 "Programm_3" 4 "Programm_4" 5 "Programm_5" 6 "Programm_6" 7 "Programm_7" 8 "Programm_8" 9 "Programm_9" 10 "Programm_10" 11 "Programm_11" 12 "Programm_12" 13 "Programm_13" 14 "Programm_14" 15 "Programm_15" ;
VAL_ 902 CHA_Ziel_FahrPr_KL 0 "keine_Funktion" 1 "Programm_1" 2 "Programm_2" 3 "Programm_3" 4 "Programm_4" 5 "Programm_5" 6 "Programm_6" 7 "Programm_7" 8 "Programm_8" 9 "Programm_9" 10 "Programm_10" 11 "Programm_11" 12 "Programm_12" 13 "Programm_13" 14 "Programm_14" 15 "Programm_15" ;
VAL_ 902 CHA_Ziel_FahrPr_RWB 0 "keine_Funktion" 1 "Programm_1" 2 "Programm_2" 3 "Programm_3" 4 "Programm_4" 5 "Programm_5" 6 "Programm_6" 7 "Programm_7" 8 "Programm_8" 9 "Programm_9" 10 "Programm_10" 11 "Programm_11" 12 "Programm_12" 13 "Programm_13" 14 "Programm_14" 15 "Programm_15" ;
VAL_ 918 DR_Gelbe_Warnlampe 0 "Warnlampe aus" 1 "Warnlampe ein (Aufprï?½fen)" 2 "Warnlampe an (Warnung)" 3 "reserviert" ;
VAL_ 1012 DC_HYB_Auslastungsgrad 254 "Init" 255 "Fehler" ;
VAL_ 1012 DC_ReserveStrom_NV 1022 "Init" 1023 "Fehler" ;
VAL_ 1012 DC_Verbrauch_Ueberlauf 0 "kein_Ueberlauf" 1 "Ueberlauf" ;
VAL_ 1012 DC_Verlustleistung 62 "Init" 63 "Fehler" ;
VAL_ 2617219605 MMI_State 0 "MMI_OFF" 1 "MMI_IOC" 2 "MMI_STDBY" 3 "MMI_ON" 4 "MMI_STDBY_PWR_SAVE" 5 "MMI_STDBY_RESTR" 6 "MMI_ON_DIAG" 7 "MMI_ON_TEL" 8 "MMI_ON_SWDL" 9 "MMI_ON_CUST_SWDL" 10 "MMI_STDBY_PWR_SAVE_1" 11 "MMI_STDBY_PWR_SAVE_2" 12 "MMI_STANDBY_CUST_SWDL" 13 "MMI_ONLINE_IOC" 14 "MMI_ONLINE" 15 "MMI_PHONE_IOC" 16 "MMI_PHONE" 17 "MMI_RTC" 18 "MMI_DCI" ;
VAL_ 2617219605 Reset_Counter 254 "Init" 255 "Fehler" ;
VAL_ 2617219605 Routeg_aktiv 0 "inaktiv" 1 "aktiv" ;
VAL_ 2617219605 SI_MOST_Status 0 "MOST_sleep_(Licht_AUS)" 1 "MOST_aktiv_(Kommunikation_moeglich)" ;
VAL_ 2617219605 Tel_aktiv 0 "inaktiv" 1 "aktiv" ;
VAL_ 2617219605 Tel_SIM_aktiv 0 "inaktiv" 1 "aktiv" ;
VAL_ 2617219605 ZR_KL_30F 254 "Init" 255 "Fehler" ;
VAL_ 2617219605 ZR_LastOn 7 "Init" ;
VAL_ 2617219605 ZR_State_DU_1 0 "Disp_Off" 1 "Disp_On" 2 "LowPow" ;
VAL_ 2617219605 ZR_TempSens 254 "Init" 255 "Fehler" ;
VAL_ 1714 DGN_Verlernzaehler 255 "ungï?½ltiger Zï?½hlerstand oder kein gï?½ltiger Fahrzyklus" ;
VAL_ 1714 KBI_Kilometerstand 1048574 "Init" 1048575 "Fehler" ;
VAL_ 1714 Kombi_02_alt 0 "aktuell" 1 "veraltet" ;
VAL_ 1714 UH_Monat 0 "Init" 14 "Relatives_Datum" 15 "Fehler" ;
VAL_ 1714 UH_Tag 0 "Init" ;
VAL_ 1714 Uhrzeit_01_alt 0 "aktuell" 1 "veraltet" ;
VAL_ 1714 Vehicle_Driving_Cycle 0 "kein_Driving_Cycle_erkannt" 1 "Driving_Cycle_erkannt" ;
